VERSION ""

NS_ :

BS_:

BU_: Skylark_EV

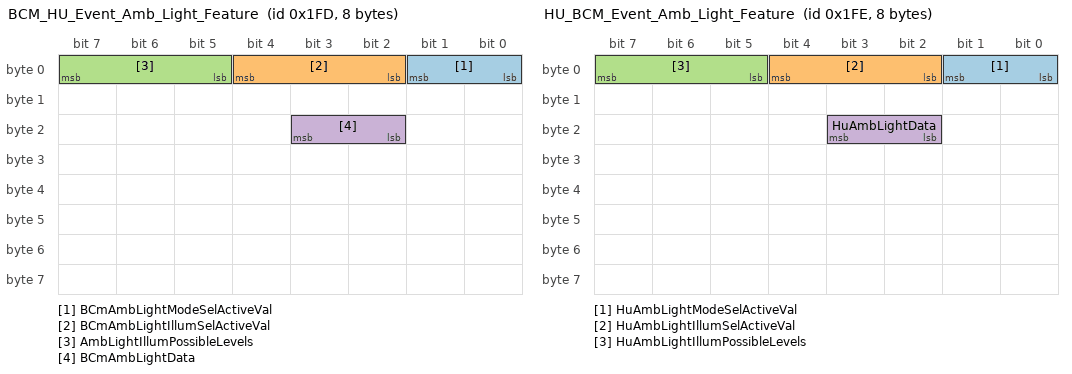
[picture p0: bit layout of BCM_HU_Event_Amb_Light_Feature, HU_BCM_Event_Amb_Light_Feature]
BO_ 509 BCM_HU_Event_Amb_Light_Feature: 8 Vector__XXX
 SG_ BCmAmbLightModeSelActiveVal : 1|2@0+ (1,0) [0|3] ""  Skylark_EV
 SG_ BCmAmbLightIllumSelActiveVal : 4|3@0+ (1,0) [0|7] ""  Skylark_EV
 SG_ AmbLightIllumPossibleLevels : 7|3@0+ (1,0) [0|7] ""  Skylark_EV
 SG_ BCmAmbLightData : 19|2@0+ (1,0) [0|3] ""  Skylark_EV

BO_ 510 HU_BCM_Event_Amb_Light_Feature: 8 Skylark_EV
 SG_ HuAmbLightModeSelActiveVal : 1|2@0+ (1,0) [0|3] "" Vector__XXX
 SG_ HuAmbLightIllumSelActiveVal : 4|3@0+ (1,0) [0|7] "" Vector__XXX
 SG_ HuAmbLightIllumPossibleLevels : 7|3@0+ (1,0) [0|7] "" Vector__XXX
 SG_ HuAmbLightData : 19|2@0+ (1,0) [0|3] "" Vector__XXX

BO_ 571 CCM_HU_Info: 8 Vector__XXX
 SG_ ColorThemeCoDrvr : 50|3@0+ (1,0) [0|7] ""  Skylark_EV
 SG_ ColorThemeDrvr : 53|3@0+ (1,0) [0|7] ""  Skylark_EV
 SG_ CcmHuRearBlwrOnOffState : 56|1@0+ (1,0) [0|1] ""  Skylark_EV
 SG_ CcmHuUserInterventionBeep : 62|1@0+ (1,0) [0|1] ""  Skylark_EV
 SG_ AutoDefogState : 40|2@0+ (1,0) [0|3] ""  Skylark_EV
 SG_ CCmHuExpressCoolSwitchStatus : 63|1@0+ (1,0) [0|1] ""  Skylark_EV
 SG_ CCmHuFanSpdStatus : 3|4@0+ (1,0) [0|15] ""  Skylark_EV
 SG_ CCmHuDistribSwitchStatus : 6|3@0+ (1,0) [0|7] ""  Skylark_EV
 SG_ CCmHuDualModeSwStatus : 7|1@0+ (1,0) [0|1] ""  Skylark_EV
 SG_ CCmHuTempWhlStatusPass : 12|5@0+ (0.5,0) [0|31] "Deg C"  Skylark_EV
 SG_ CCMHuFreshAirRecircSwitchStatus : 14|2@0+ (1,0) [0|3] ""  Skylark_EV
 SG_ CCmHuAutoSwitchStatus : 15|1@0+ (1,0) [0|1] ""  Skylark_EV
 SG_ CCmHuTempWhlStatus : 20|5@0+ (0.5,0) [0|31] "Deg C"  Skylark_EV
 SG_ CCmHuEconModeSwitchStatus : 21|1@0+ (1,0) [0|1] ""  Skylark_EV
 SG_ CCmHuMaxDefrstSwitchStatus : 22|1@0+ (1,0) [0|1] ""  Skylark_EV
 SG_ CCmHuRearDefogSwitchStatus : 23|1@0+ (1,0) [0|1] ""  Skylark_EV
 SG_ CCmHuTempWhlStatusDrvr : 28|5@0+ (0.5,0) [0|31] "Deg  C"  Skylark_EV
 SG_ CCmHuAirConCompSwitchStatus : 29|1@0+ (1,0) [0|1] ""  Skylark_EV
 SG_ CCmHuCtrlPnlStatus : 30|1@0+ (1,0) [0|1] ""  Skylark_EV
 SG_ CCmHuChangeBit : 31|1@0+ (1,0) [0|1] ""  Skylark_EV
 SG_ CCmHuUserInterventionStatusFlag : 37|5@0+ (1,0) [0|31] ""  Skylark_EV
 SG_ CCmHuTempWhlStatusStatus : 39|2@0+ (1,0) [0|3] ""  Skylark_EV
 SG_ CCmHuErrStatus : 41|1@0+ (1,0) [0|1] ""  Skylark_EV
 SG_ CCmHuDualModeSwStatusStatus : 43|2@0+ (1,0) [0|3] ""  Skylark_EV
 SG_ CCmHuTempWhlStatusPassStatus : 45|2@0+ (1,0) [0|3] ""  Skylark_EV
 SG_ CCmHuTempWhlStatusDrvrStatus : 47|2@0+ (1,0) [0|3] ""  Skylark_EV

BO_ 573 ESCL1_RC: 8 Vector__XXX
 SG_ LockStateESCL : 2|1@0+ (1,0) [0|1] ""  Skylark_EV
 SG_ UnlockStateESCL : 3|1@0+ (1,0) [0|1] ""  Skylark_EV

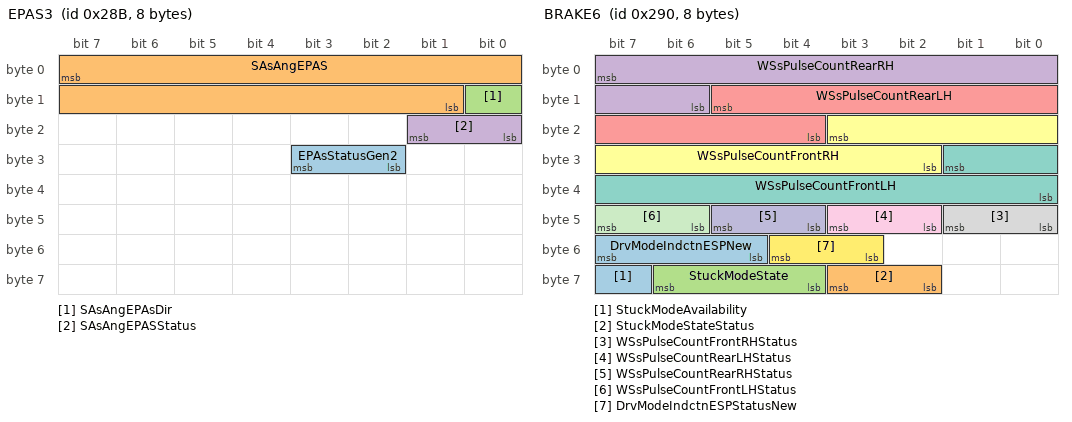
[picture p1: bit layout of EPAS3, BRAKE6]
BO_ 651 EPAS3: 8 Vector__XXX
 SG_ EPAsStatusGen2 : 27|2@0+ (1,0) [0|3] ""  Skylark_EV
 SG_ SAsAngEPAS : 7|15@0+ (0.04375,0) [0|1433.55625] " deg"  Skylark_EV
 SG_ SAsAngEPAsDir : 8|1@0+ (1,0) [0|1] ""  Skylark_EV
 SG_ SAsAngEPASStatus : 17|2@0+ (1,0) [0|3] ""  Skylark_EV

BO_ 656 BRAKE6: 8 Vector__XXX
 SG_ StuckModeAvailability : 63|1@0+ (1,0) [0|1] ""  Skylark_EV
 SG_ StuckModeStateStatus : 59|2@0+ (1,0) [0|3] ""  Skylark_EV
 SG_ StuckModeState : 62|3@0+ (1,0) [0|7] ""  Skylark_EV
 SG_ WSsPulseCountRearRH : 7|10@0+ (1,0) [0|1023] "Pulse"  Skylark_EV
 SG_ WSsPulseCountRearLH : 13|10@0+ (1,0) [0|1023] "Pulse"  Skylark_EV
 SG_ WSsPulseCountFrontRH : 19|10@0+ (1,0) [0|1023] "Pulse"  Skylark_EV
 SG_ WSsPulseCountFrontLH : 25|10@0+ (1,0) [0|1023] "Pulse"  Skylark_EV
 SG_ WSsPulseCountFrontRHStatus : 41|2@0+ (1,0) [0|3] ""  Skylark_EV
 SG_ WSsPulseCountRearLHStatus : 43|2@0+ (1,0) [0|3] ""  Skylark_EV
 SG_ WSsPulseCountRearRHStatus : 45|2@0+ (1,0) [0|3] ""  Skylark_EV
 SG_ WSsPulseCountFrontLHStatus : 47|2@0+ (1,0) [0|3] ""  Skylark_EV
 SG_ DrvModeIndctnESPStatusNew : 52|2@0+ (1,0) [0|3] ""  Skylark_EV
 SG_ DrvModeIndctnESPNew : 55|3@0+ (1,0) [0|7] ""  Skylark_EV

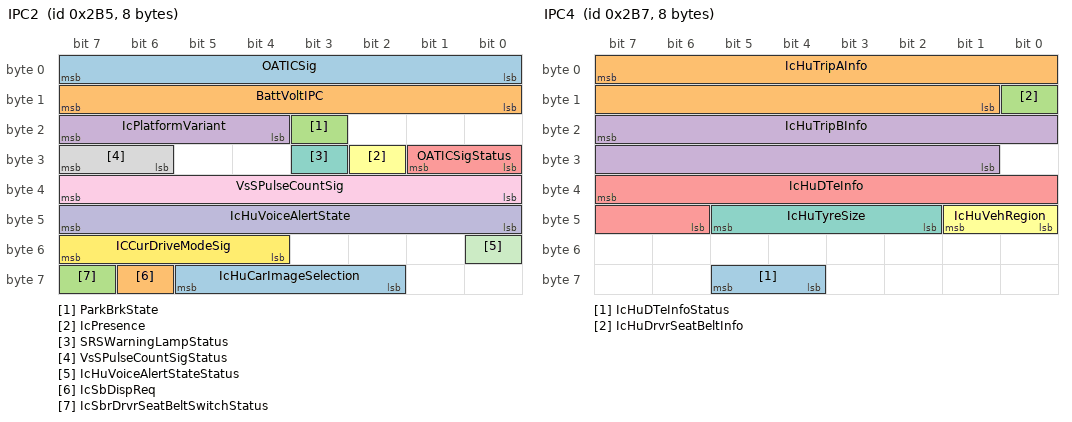
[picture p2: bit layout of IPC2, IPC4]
BO_ 693 IPC2: 8 Vector__XXX
 SG_ OATICSig : 7|8@0+ (0.5,-40) [-40|85] "degC"  Skylark_EV
 SG_ BattVoltIPC : 15|8@0+ (0.1,0) [0|25.4] "Volts"  Skylark_EV
 SG_ ParkBrkState : 19|1@0+ (1,0) [0|1] ""  Skylark_EV
 SG_ IcPlatformVariant : 23|4@0+ (1,0) [0|15] ""  Skylark_EV
 SG_ OATICSigStatus : 25|2@0+ (1,0) [0|3] ""  Skylark_EV
 SG_ IcPresence : 26|1@0+ (1,0) [0|1] ""  Skylark_EV
 SG_ SRSWarningLampStatus : 27|1@0+ (1,0) [0|1] ""  Skylark_EV
 SG_ VsSPulseCountSigStatus : 31|2@0+ (1,0) [0|3] ""  Skylark_EV
 SG_ VsSPulseCountSig : 39|8@0+ (1,0) [0|255] "Pulse"  Skylark_EV
 SG_ IcHuVoiceAlertState : 47|8@0+ (1,0) [0|255] ""  Skylark_EV
 SG_ IcHuVoiceAlertStateStatus : 48|1@0+ (1,0) [0|1] ""  Skylark_EV
 SG_ ICCurDriveModeSig : 55|4@0+ (1,0) [0|15] ""  Skylark_EV
 SG_ IcHuCarImageSelection : 61|4@0+ (1,0) [0|15] ""  Skylark_EV
 SG_ IcSbDispReq : 62|1@0+ (1,0) [0|1] ""  Skylark_EV
 SG_ IcSbrDrvrSeatBeltSwitchStatus : 63|1@0+ (1,0) [0|1] ""  Skylark_EV

BO_ 695 IPC4: 8 Vector__XXX
 SG_ IcHuDTeInfoStatus : 61|2@0+ (1,0) [0|3] ""  Skylark_EV
 SG_ IcHuTripAInfo : 7|15@0+ (0.1,0) [0|1999] "Km"  Skylark_EV
 SG_ IcHuDrvrSeatBeltInfo : 8|1@0+ (1,0) [0|1] ""  Skylark_EV
 SG_ IcHuTripBInfo : 23|15@0+ (0.1,0) [0|1999] "Km"  Skylark_EV
 SG_ IcHuDTeInfo : 39|10@0+ (1,0) [0|999] ""  Skylark_EV
 SG_ IcHuVehRegion : 41|2@0+ (1,0) [0|3] ""  Skylark_EV
 SG_ IcHuTyreSize : 45|4@0+ (1,0) [0|15] ""  Skylark_EV

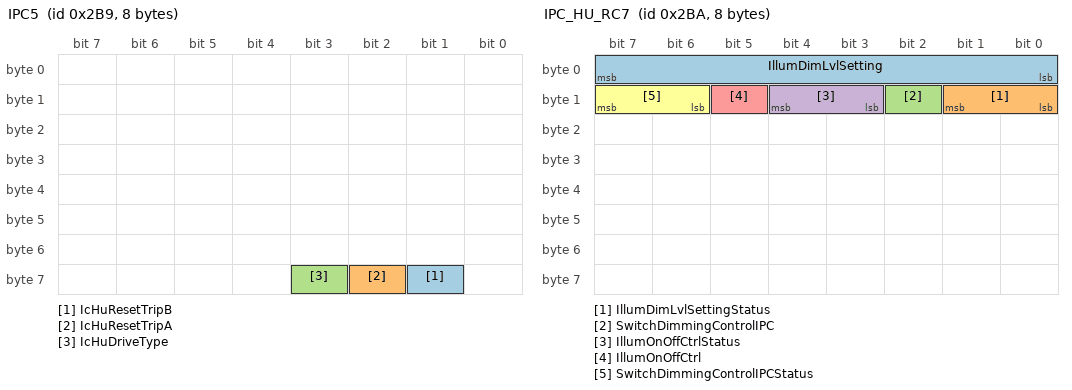
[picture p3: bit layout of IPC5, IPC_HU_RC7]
BO_ 697 IPC5: 8 Vector__XXX
 SG_ IcHuResetTripB : 57|1@0+ (1,0) [0|1] ""  Skylark_EV
 SG_ IcHuResetTripA : 58|1@0+ (1,0) [0|1] ""  Skylark_EV
 SG_ IcHuDriveType : 59|1@0+ (1,0) [0|1] ""  Skylark_EV

BO_ 698 IPC_HU_RC7: 8 Vector__XXX
 SG_ IllumDimLvlSetting : 7|8@0+ (1,0) [0|100] "%"  Skylark_EV
 SG_ IllumDimLvlSettingStatus : 9|2@0+ (1,0) [0|3] ""  Skylark_EV
 SG_ SwitchDimmingControlIPC : 10|1@0+ (1,0) [0|1] ""  Skylark_EV
 SG_ IllumOnOffCtrlStatus : 12|2@0+ (1,0) [0|3] ""  Skylark_EV
 SG_ IllumOnOffCtrl : 13|1@0+ (1,0) [0|1] ""  Skylark_EV
 SG_ SwitchDimmingControlIPCStatus : 15|2@0+ (1,0) [0|3] ""  Skylark_EV

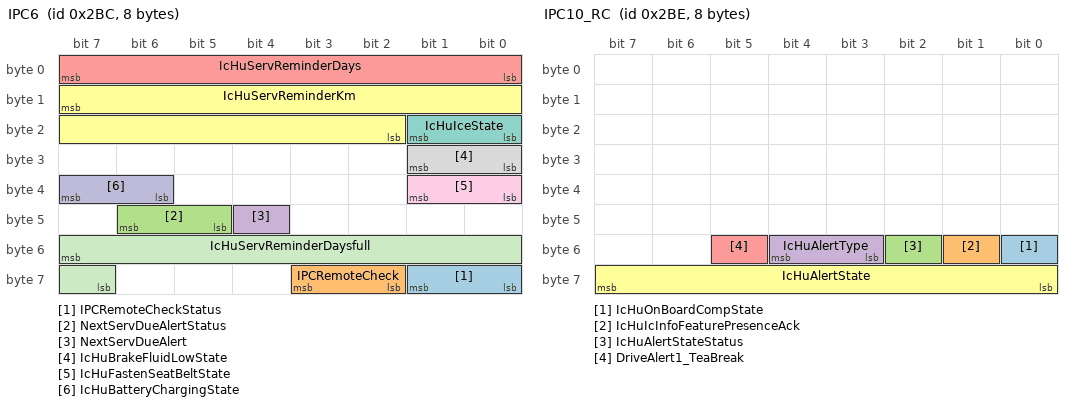
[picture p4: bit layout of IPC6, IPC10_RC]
BO_ 700 IPC6: 8 Vector__XXX
 SG_ IPCRemoteCheckStatus : 57|2@0+ (1,0) [0|3] ""  Skylark_EV
 SG_ IPCRemoteCheck : 59|2@0+ (1,0) [0|3] ""  Skylark_EV
 SG_ NextServDueAlertStatus : 46|2@0+ (1,0) [0|3] ""  Skylark_EV
 SG_ NextServDueAlert : 44|1@0+ (1,0) [0|1] ""  Skylark_EV
 SG_ IcHuServReminderDays : 7|8@0+ (1,0) [0|255] "Day"  Skylark_EV
 SG_ IcHuServReminderKm : 15|14@0+ (1,0) [0|16383] "Km"  Skylark_EV
 SG_ IcHuIceState : 17|2@0+ (1,0) [0|3] ""  Skylark_EV
 SG_ IcHuBrakeFluidLowState : 25|2@0+ (1,0) [0|3] ""  Skylark_EV
 SG_ IcHuFastenSeatBeltState : 33|2@0+ (1,0) [0|3] ""  Skylark_EV
 SG_ IcHuBatteryChargingState : 39|2@0+ (1,0) [0|3] ""  Skylark_EV
 SG_ IcHuServReminderDaysfull : 55|9@0+ (1,0) [0|511] "Day"  Skylark_EV

BO_ 702 IPC10_RC: 8 Vector__XXX
 SG_ IcHuOnBoardCompState : 48|1@0+ (1,0) [0|1] ""  Skylark_EV
 SG_ IcHuIcInfoFeaturePresenceAck : 49|1@0+ (1,0) [0|1] ""  Skylark_EV
 SG_ IcHuAlertStateStatus : 50|1@0+ (1,0) [0|1] ""  Skylark_EV
 SG_ IcHuAlertType : 52|2@0+ (1,0) [0|3] ""  Skylark_EV
 SG_ DriveAlert1_TeaBreak : 53|1@0+ (1,0) [0|1] ""  Skylark_EV
 SG_ IcHuAlertState : 63|8@0+ (1,0) [0|255] ""  Skylark_EV

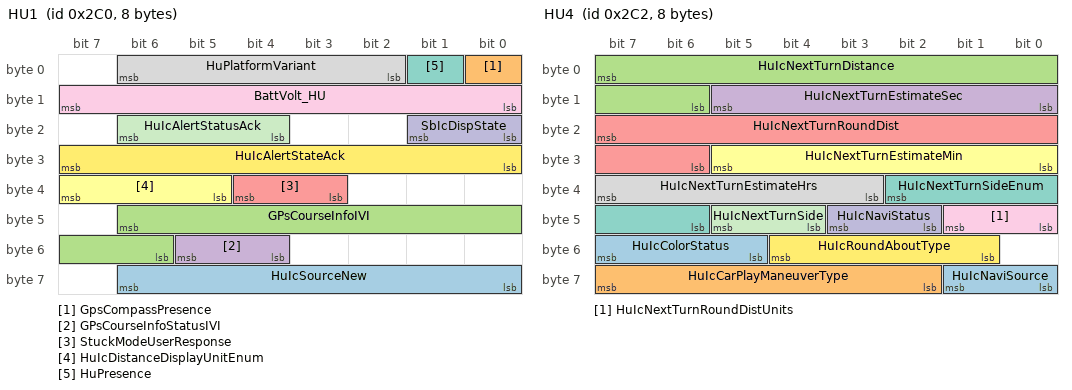
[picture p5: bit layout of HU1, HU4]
BO_ 704 HU1: 8 Skylark_EV
 SG_ HuIcSourceNew : 62|7@0+ (1,0) [0|127] "" Vector__XXX
 SG_ GpsCompassPresence : 0|1@0+ (1,0) [0|1] "" Vector__XXX
 SG_ GPsCourseInfoIVI : 46|9@0+ (1,0) [0|360] "" Vector__XXX
 SG_ GPsCourseInfoStatusIVI : 53|2@0+ (1,0) [0|3] "" Vector__XXX
 SG_ StuckModeUserResponse : 36|2@0+ (1,0) [0|3] "" Vector__XXX
 SG_ HuIcDistanceDisplayUnitEnum : 39|3@0+ (1,0) [0|7] "" Vector__XXX
 SG_ HuPresence : 1|1@0+ (1,0) [0|1] "" Vector__XXX
 SG_ HuPlatformVariant : 6|5@0+ (1,0) [0|31] "" Vector__XXX
 SG_ BattVolt_HU : 15|8@0+ (0.1,0) [0|25] "Volts" Vector__XXX
 SG_ SbIcDispState : 17|2@0+ (1,0) [0|3] "" Vector__XXX
 SG_ HuIcAlertStatusAck : 22|3@0+ (1,0) [0|7] "" Vector__XXX
 SG_ HuIcAlertStateAck : 31|8@0+ (1,0) [0|255] "" Vector__XXX

BO_ 706 HU4: 8 Skylark_EV
 SG_ HuIcNaviSource : 57|2@0+ (1,0) [0|3] "" Vector__XXX
 SG_ HuIcCarPlayManeuverType : 63|6@0+ (1,0) [0|63] "" Vector__XXX
 SG_ HuIcNextTurnDistance : 7|10@0+ (1,0) [0|1023] "m" Vector__XXX
 SG_ HuIcNextTurnEstimateSec : 13|6@0+ (1,0) [0|59] "sec" Vector__XXX
 SG_ HuIcNextTurnRoundDist : 23|10@0+ (1,0) [0|1023] "m" Vector__XXX
 SG_ HuIcNextTurnEstimateMin : 29|6@0+ (1,0) [0|59] "min" Vector__XXX
 SG_ HuIcNextTurnSideEnum : 34|5@0+ (1,0) [0|31] "" Vector__XXX
 SG_ HuIcNextTurnEstimateHrs : 39|5@0+ (1,0) [0|23] "hr" Vector__XXX
 SG_ HuIcNextTurnRoundDistUnits : 41|2@0+ (1,0) [0|3] "" Vector__XXX
 SG_ HuIcNaviStatus : 43|2@0+ (1,0) [0|3] "" Vector__XXX
 SG_ HuIcNextTurnSide : 45|2@0+ (1,0) [0|3] "" Vector__XXX
 SG_ HuIcRoundAboutType : 52|4@0+ (1,0) [0|15] "" Vector__XXX
 SG_ HuIcColorStatus : 55|3@0+ (1,0) [0|7] "" Vector__XXX

BO_ 707 HU2: 8 Skylark_EV
 SG_ HuIcNextTurnRoundDistUnitsNew : 59|3@0+ (1,0) [0|7] "" Vector__XXX
 SG_ HuIcNextTurnDistanceNew : 41|14@0+ (1,0) [0|16383] "m" Vector__XXX
 SG_ LinSwcSbPowerModeCan : 43|2@0+ (1,0) [0|3] "" Vector__XXX
 SG_ LinSwcIcKey9Can : 46|3@0+ (1,0) [0|7] "" Vector__XXX
 SG_ LinSwcIcKey8Can : 33|3@0+ (1,0) [0|7] "" Vector__XXX
 SG_ LinSwcIcKey7Can : 36|3@0+ (1,0) [0|7] "" Vector__XXX
 SG_ LinSwcIcKey6Can : 39|3@0+ (1,0) [0|7] "" Vector__XXX
 SG_ LinSwcIcViewCan : 26|3@0+ (1,0) [0|7] "" Vector__XXX
 SG_ LinSwcIcMenuSelectCan : 29|3@0+ (1,0) [0|7] "" Vector__XXX
 SG_ LinSwcIcMenuDownCan : 16|3@0+ (1,0) [0|7] "" Vector__XXX
 SG_ LinSwcIcMenuUpCan : 19|3@0+ (1,0) [0|7] "" Vector__XXX
 SG_ LinSwcIcpaginationCan : 22|3@0+ (1,0) [0|7] "" Vector__XXX
 SG_ LinSwcPresenceCanStatus : 4|2@0+ (1,0) [0|3] "" Vector__XXX
 SG_ LinSwcIcVariant : 7|3@0+ (1,0) [0|7] "" Vector__XXX
 SG_ LinSwcPresenceCan : 23|1@0+ (1,0) [0|1] "" Vector__XXX
 SG_ HuIcVoiceAlertStatusAck : 2|3@0+ (1,0) [0|7] "" Vector__XXX
 SG_ HuIcVoiceAlertStateAck : 15|8@0+ (1,0) [0|255] "" Vector__XXX

BO_ 710 PDC1: 8 Vector__XXX
 SG_ PDcHuFaultState : 4|5@0+ (1,0) [0|31] ""  Skylark_EV
 SG_ PDcHuAudioZoneState : 7|3@0+ (1,0) [0|7] ""  Skylark_EV
 SG_ PDcHuVisualZoneRearLHSensState : 11|4@0+ (1,0) [0|15] ""  Skylark_EV
 SG_ PDcHuVisualZoneRearMidRHSensStat : 15|4@0+ (1,0) [0|15] ""  Skylark_EV
 SG_ PDcHuVisualZoneRearRHSensState : 19|4@0+ (1,0) [0|15] ""  Skylark_EV
 SG_ PDcHuVisualZoneRearMidLHSensStat : 23|4@0+ (1,0) [0|15] ""  Skylark_EV
 SG_ PDcPresence : 24|1@0+ (1,0) [0|1] ""  Skylark_EV
 SG_ PDcHuState : 25|1@0+ (1,0) [0|1] ""  Skylark_EV
 SG_ PDcHuPwrModeState : 29|4@0+ (1,0) [0|15] ""  Skylark_EV
 SG_ PDcVariant : 31|2@0+ (1,0) [0|3] ""  Skylark_EV
 SG_ PDcHuVisualZoneFrontLHSensState : 35|4@0+ (1,0) [0|15] ""  Skylark_EV
 SG_ PDcHuVisualZoneFrontMidLHSensSta : 39|4@0+ (1,0) [0|15] ""  Skylark_EV
 SG_ PDcHuVisualZoneFrontMidRHSensSta : 43|4@0+ (1,0) [0|15] ""  Skylark_EV
 SG_ PDcHuVisualZoneFrontRHSensState : 47|4@0+ (1,0) [0|15] ""  Skylark_EV
 SG_ PDcHuFrontAudioZoneState : 50|3@0+ (1,0) [0|7] ""  Skylark_EV
 SG_ PDcHuFrontFaultState : 55|5@0+ (1,0) [0|31] ""  Skylark_EV
 SG_ PDcHuFrontState : 56|1@0+ (1,0) [0|1] ""  Skylark_EV
 SG_ PDcIPcFrontActive : 59|1@0+ (1,0) [0|1] ""  Skylark_EV
 SG_ PDcIPcRearActive : 60|1@0+ (1,0) [0|1] ""  Skylark_EV

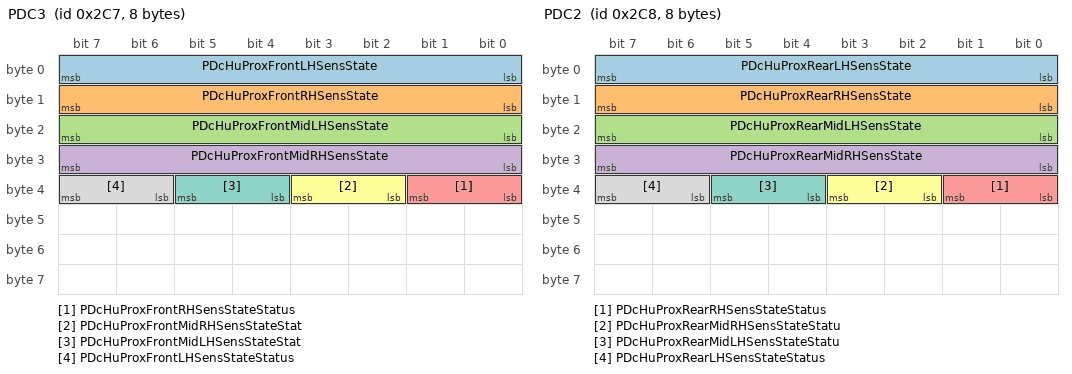
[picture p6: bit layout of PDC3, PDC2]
BO_ 711 PDC3: 8 Vector__XXX
 SG_ PDcHuProxFrontLHSensState : 7|8@0+ (1,0) [0|255] "cms"  Skylark_EV
 SG_ PDcHuProxFrontRHSensState : 15|8@0+ (1,0) [0|255] "cms"  Skylark_EV
 SG_ PDcHuProxFrontMidLHSensState : 23|8@0+ (1,0) [0|255] "cms"  Skylark_EV
 SG_ PDcHuProxFrontMidRHSensState : 31|8@0+ (1,0) [0|255] "cm"  Skylark_EV
 SG_ PDcHuProxFrontRHSensStateStatus : 33|2@0+ (1,0) [0|3] ""  Skylark_EV
 SG_ PDcHuProxFrontMidRHSensStateStat : 35|2@0+ (1,0) [0|3] ""  Skylark_EV
 SG_ PDcHuProxFrontMidLHSensStateStat : 37|2@0+ (1,0) [0|3] ""  Skylark_EV
 SG_ PDcHuProxFrontLHSensStateStatus : 39|2@0+ (1,0) [0|3] ""  Skylark_EV

BO_ 712 PDC2: 8 Vector__XXX
 SG_ PDcHuProxRearLHSensState : 7|8@0+ (1,0) [0|255] "cms"  Skylark_EV
 SG_ PDcHuProxRearRHSensState : 15|8@0+ (1,0) [0|255] "cms"  Skylark_EV
 SG_ PDcHuProxRearMidLHSensState : 23|8@0+ (1,0) [0|255] "cms"  Skylark_EV
 SG_ PDcHuProxRearMidRHSensState : 31|8@0+ (1,0) [0|255] "cm"  Skylark_EV
 SG_ PDcHuProxRearRHSensStateStatus : 33|2@0+ (1,0) [0|3] ""  Skylark_EV
 SG_ PDcHuProxRearMidRHSensStateStatu : 35|2@0+ (1,0) [0|3] ""  Skylark_EV
 SG_ PDcHuProxRearMidLHSensStateStatu : 37|2@0+ (1,0) [0|3] ""  Skylark_EV
 SG_ PDcHuProxRearLHSensStateStatus : 39|2@0+ (1,0) [0|3] ""  Skylark_EV

BO_ 713 HU5: 8 Skylark_EV
 SG_ HuIcMediaState : 3|4@0+ (1,0) [0|15] "" Vector__XXX
 SG_ HuIcSource : 7|4@0+ (1,0) [0|15] "" Vector__XXX
 SG_ HuIcAudioVolumeStatus : 12|5@0+ (1,0) [0|31] "" Vector__XXX
 SG_ HuIcBTStatus : 15|3@0+ (1,0) [0|7] "" Vector__XXX
 SG_ HuIcPlabackCallDurationSec : 21|6@0+ (1,0) [0|59] "sec." Vector__XXX
 SG_ HuIcRepeatOneState : 22|1@0+ (1,0) [0|1] "" Vector__XXX
 SG_ HuIcMuteStatus : 23|1@0+ (1,0) [0|1] "" Vector__XXX
 SG_ HuIcPlabackCallDurationMin : 29|6@0+ (1,0) [0|59] "min" Vector__XXX
 SG_ HuIcSMSReceiveState : 30|1@0+ (1,0) [0|1] "" Vector__XXX
 SG_ HuIcRepeatState : 31|1@0+ (1,0) [0|1] "" Vector__XXX
 SG_ HuIcPlabackCallDurationHrs : 36|5@0+ (1,0) [0|23] "hr" Vector__XXX
 SG_ HuIcPhoneCallStatus : 39|3@0+ (1,0) [0|7] "" Vector__XXX
 SG_ HuIcPlaybackElapsedTimeHrs : 44|5@0+ (1,0) [0|23] "hr" Vector__XXX
 SG_ HuIcNetworkSignalStatus : 47|3@0+ (1,0) [0|7] "" Vector__XXX
 SG_ HuIcPlaybackElapsedTimeMin : 53|6@0+ (1,0) [0|59] "min" Vector__XXX
 SG_ HuIcInfoFeaturePresence : 54|1@0+ (1,0) [0|1] "" Vector__XXX
 SG_ HuIcShuffleState : 55|1@0+ (1,0) [0|1] "" Vector__XXX
 SG_ HuIcPlaybackElapsedTimeSec : 61|6@0+ (1,0) [0|59] "sec" Vector__XXX

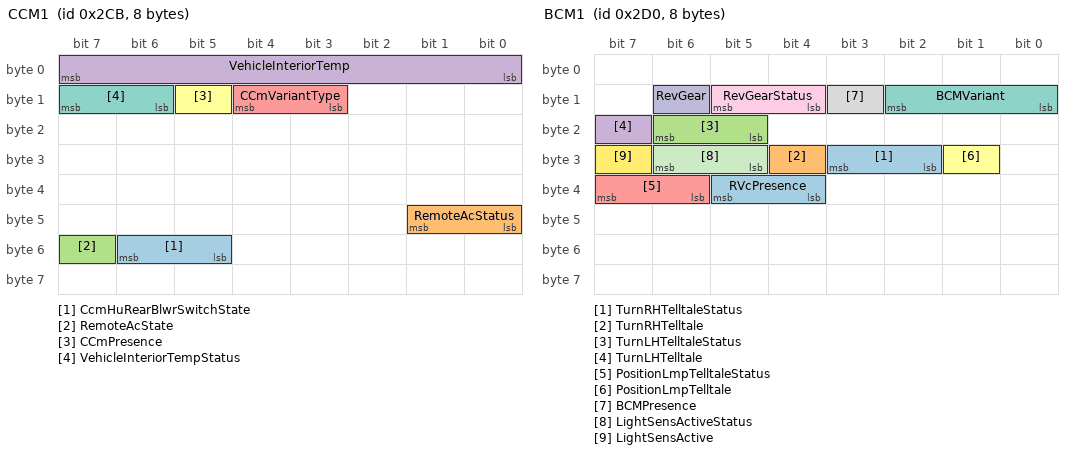
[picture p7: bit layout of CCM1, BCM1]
BO_ 715 CCM1: 8 Vector__XXX
 SG_ CcmHuRearBlwrSwitchState : 54|2@0+ (1,0) [0|3] ""  Skylark_EV
 SG_ RemoteAcStatus : 41|2@0+ (1,0) [0|3] ""  Skylark_EV
 SG_ RemoteAcState : 55|1@0+ (1,0) [0|1] ""  Skylark_EV
 SG_ VehicleInteriorTemp : 7|8@0+ (0.5,-40) [-40|85] "Deg"  Skylark_EV
 SG_ CCmVariantType : 12|2@0+ (1,0) [0|3] ""  Skylark_EV
 SG_ CCmPresence : 13|1@0+ (1,0) [0|1] ""  Skylark_EV
 SG_ VehicleInteriorTempStatus : 15|2@0+ (1,0) [0|3] ""  Skylark_EV

BO_ 720 BCM1: 8 Vector__XXX
 SG_ TurnRHTelltaleStatus : 27|2@0+ (1,0) [0|3] ""  Skylark_EV
 SG_ TurnRHTelltale : 28|1@0+ (1,0) [0|1] ""  Skylark_EV
 SG_ TurnLHTelltaleStatus : 22|2@0+ (1,0) [0|3] ""  Skylark_EV
 SG_ TurnLHTelltale : 23|1@0+ (1,0) [0|1] ""  Skylark_EV
 SG_ PositionLmpTelltaleStatus : 39|2@0+ (1,0) [0|3] ""  Skylark_EV
 SG_ PositionLmpTelltale : 25|1@0+ (1,0) [0|1] ""  Skylark_EV
 SG_ BCMVariant : 10|3@0+ (1,0) [0|7] ""  Skylark_EV
 SG_ BCMPresence : 11|1@0+ (1,0) [0|1] ""  Skylark_EV
 SG_ RevGearStatus : 13|2@0+ (1,0) [0|3] ""  Skylark_EV
 SG_ RevGear : 14|1@0+ (1,0) [0|1] ""  Skylark_EV
 SG_ LightSensActiveStatus : 30|2@0+ (1,0) [0|3] ""  Skylark_EV
 SG_ LightSensActive : 31|1@0+ (1,0) [0|1] ""  Skylark_EV
 SG_ RVcPresence : 37|2@0+ (1,0) [0|3] ""  Skylark_EV

BO_ 722 BCM_HUICTrailer_RC1: 8 Vector__XXX
 SG_ PowerModeStateMsgCnt : 51|4@0+ (1,0) [0|15] ""  Skylark_EV
 SG_ PowerModeStateCRC : 63|8@0+ (1,0) [0|255] ""  Skylark_EV
 SG_ PowerModeStateStatus : 1|2@0+ (1,0) [0|3] ""  Skylark_EV
 SG_ PowerModeState : 5|4@0+ (1,0) [0|15] ""  Skylark_EV
 SG_ PositionLmpTelltaleStatus : 7|2@0+ (1,0) [0|3] ""  Skylark_EV
 SG_ PositionLmpTelltale : 8|1@0+ (1,0) [0|1] ""  Skylark_EV
 SG_ TurnRHTelltale : 12|1@0+ (1,0) [0|1] ""  Skylark_EV
 SG_ TurnLHTelltaleStatus : 14|2@0+ (1,0) [0|3] ""  Skylark_EV
 SG_ TurnLHTelltale : 15|1@0+ (1,0) [0|1] ""  Skylark_EV
 SG_ TurnRHTelltaleStatus : 17|2@0+ (1,0) [0|3] ""  Skylark_EV
 SG_ BattSaverFnONStatus : 19|2@0+ (1,0) [0|3] ""  Skylark_EV
 SG_ BattSaverFnON : 20|1@0+ (1,0) [0|1] ""  Skylark_EV
 SG_ CockpitSigECuStatus : 25|2@0+ (1,0) [0|3] ""  Skylark_EV
 SG_ CockpitSigECu : 39|8@0+ (1,0) [0|100] "%"  Skylark_EV
 SG_ VehicleLockStateStatus : 41|2@0+ (1,0) [0|3] ""  Skylark_EV
 SG_ HighBeamTelltaleStatus : 43|2@0+ (1,0) [0|3] ""  Skylark_EV
 SG_ HighBeamTelltale : 44|1@0+ (1,0) [0|1] ""  Skylark_EV
 SG_ VehicleLockState : 55|3@0+ (1,0) [0|7] ""  Skylark_EV

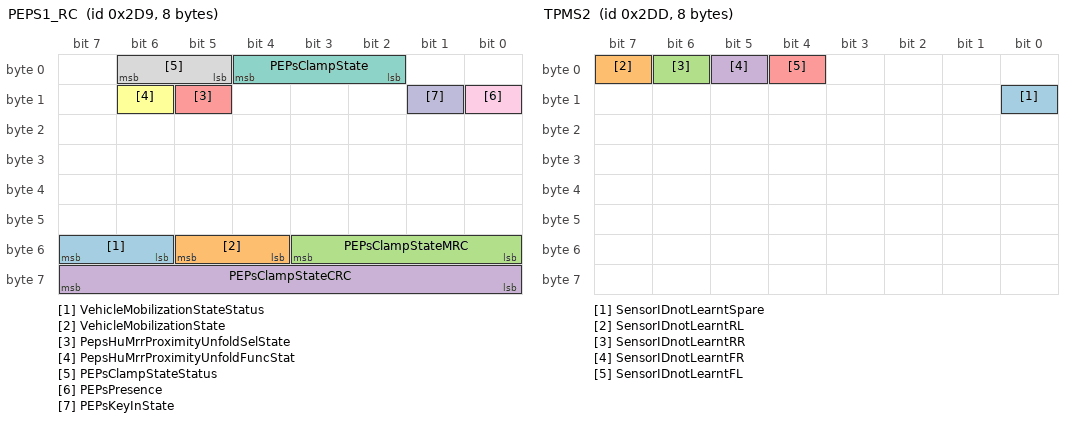
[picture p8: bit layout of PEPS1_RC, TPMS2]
BO_ 729 PEPS1_RC: 8 Vector__XXX
 SG_ VehicleMobilizationStateStatus : 55|2@0+ (1,0) [0|3] ""  Skylark_EV
 SG_ VehicleMobilizationState : 53|2@0+ (1,0) [0|3] ""  Skylark_EV
 SG_ PEPsClampStateMRC : 51|4@0+ (1,0) [0|15] ""  Skylark_EV
 SG_ PEPsClampStateCRC : 63|8@0+ (1,0) [0|255] ""  Skylark_EV
 SG_ PepsHuMrrProximityUnfoldSelState : 13|1@0+ (1,0) [0|1] ""  Skylark_EV
 SG_ PepsHuMrrProximityUnfoldFuncStat : 14|1@0+ (1,0) [0|1] ""  Skylark_EV
 SG_ PEPsClampState : 4|3@0+ (1,0) [0|7] ""  Skylark_EV
 SG_ PEPsClampStateStatus : 6|2@0+ (1,0) [0|3] ""  Skylark_EV
 SG_ PEPsPresence : 8|1@0+ (1,0) [0|1] ""  Skylark_EV
 SG_ PEPsKeyInState : 9|1@0+ (1,0) [0|1] ""  Skylark_EV

BO_ 732 TPMS1: 8 Vector__XXX
 SG_ TpmsTireSensorConfig : 47|2@0+ (1,0) [0|3] ""  Skylark_EV
 SG_ TPMSPresence : 49|1@0+ (1,0) [0|1] ""  Skylark_EV
 SG_ LowTirePresAlertSpare : 14|1@0+ (1,0) [0|1] ""  Skylark_EV
 SG_ LowTirePresAlertRL : 13|1@0+ (1,0) [0|1] ""  Skylark_EV
 SG_ LowTirePresAlertRR : 12|1@0+ (1,0) [0|1] ""  Skylark_EV
 SG_ LowTirePresAlertFR : 11|1@0+ (1,0) [0|1] ""  Skylark_EV
 SG_ LowTirePresAlertFL : 10|1@0+ (1,0) [0|1] ""  Skylark_EV
 SG_ HighTirePresAlertSpare : 4|1@0+ (1,0) [0|1] ""  Skylark_EV
 SG_ HighTirePresAlertRL : 2|1@0+ (1,0) [0|1] ""  Skylark_EV
 SG_ HighTirePresAlertRR : 3|1@0+ (1,0) [0|1] ""  Skylark_EV
 SG_ HighTirePresAlertFR : 1|1@0+ (1,0) [0|1] ""  Skylark_EV
 SG_ HighTirePresAlertFL : 0|1@0+ (1,0) [0|1] ""  Skylark_EV
 SG_ HighTireTempAlertSpare : 9|1@0+ (1,0) [0|1] ""  Skylark_EV
 SG_ HighTireTempAlertRL : 7|1@0+ (1,0) [0|1] ""  Skylark_EV
 SG_ HighTireTempAlertRR : 8|1@0+ (1,0) [0|1] ""  Skylark_EV
 SG_ HighTireTempAlertFR : 6|1@0+ (1,0) [0|1] ""  Skylark_EV
 SG_ HighTireTempAlertFL : 5|1@0+ (1,0) [0|1] ""  Skylark_EV
 SG_ PresLeakageAlertSpare : 19|1@0+ (1,0) [0|1] ""  Skylark_EV
 SG_ PresLeakageAlertRL : 17|1@0+ (1,0) [0|1] ""  Skylark_EV
 SG_ PresLeakageAlertRR : 18|1@0+ (1,0) [0|1] ""  Skylark_EV
 SG_ PresLeakageAlertFR : 16|1@0+ (1,0) [0|1] ""  Skylark_EV
 SG_ PresLeakageAlertFL : 15|1@0+ (1,0) [0|1] ""  Skylark_EV
 SG_ TpmsAlertStatus : 45|2@0+ (1,0) [0|3] ""  Skylark_EV
 SG_ TpmsReceiverRXFault : 48|1@0+ (1,0) [0|1] ""  Skylark_EV
 SG_ SensorMalfncFaultSpare : 29|1@0+ (1,0) [0|1] ""  Skylark_EV
 SG_ SensorMalfncFaultRL : 27|1@0+ (1,0) [0|1] ""  Skylark_EV
 SG_ SensorMalfncFaultRR : 28|1@0+ (1,0) [0|1] ""  Skylark_EV
 SG_ SensorMalfncFaultFR : 26|1@0+ (1,0) [0|1] ""  Skylark_EV
 SG_ SensorMalfncFaultFL : 25|1@0+ (1,0) [0|1] ""  Skylark_EV
 SG_ TpmsFaultStatus : 39|2@0+ (1,0) [0|3] ""  Skylark_EV
 SG_ TpmsNotLearntFault : 40|1@0+ (1,0) [0|1] ""  Skylark_EV
 SG_ SensorMissingFaultRL : 32|1@0+ (1,0) [0|1] ""  Skylark_EV
 SG_ SensorMissingFaultRR : 33|1@0+ (1,0) [0|1] ""  Skylark_EV
 SG_ SensorMissingFaultFR : 31|1@0+ (1,0) [0|1] ""  Skylark_EV
 SG_ SensorMissingFaultFL : 30|1@0+ (1,0) [0|1] ""  Skylark_EV
 SG_ TpmsLearnStatus : 51|2@0+ (1,0) [0|3] ""  Skylark_EV
 SG_ SpareTireSwapFlagRL : 36|1@0+ (1,0) [0|1] ""  Skylark_EV
 SG_ SpareTireSwapFlagRR : 37|1@0+ (1,0) [0|1] ""  Skylark_EV
 SG_ SpareTireSwapFlagFR : 35|1@0+ (1,0) [0|1] ""  Skylark_EV
 SG_ SpareTireSwapFlagFL : 34|1@0+ (1,0) [0|1] ""  Skylark_EV
 SG_ SensorLearningStatus : 43|3@0+ (1,0) [0|7] ""  Skylark_EV
 SG_ SensorDetectFlagSpare : 24|1@0+ (1,0) [0|1] ""  Skylark_EV
 SG_ SensorDetectFlagRL : 22|1@0+ (1,0) [0|1] ""  Skylark_EV
 SG_ SensorDetectFlagRR : 23|1@0+ (1,0) [0|1] ""  Skylark_EV
 SG_ SensorDetectFlagFR : 21|1@0+ (1,0) [0|1] ""  Skylark_EV
 SG_ SensorDetectFlagFL : 20|1@0+ (1,0) [0|1] ""  Skylark_EV

BO_ 733 TPMS2: 8 Vector__XXX
 SG_ SensorIDnotLearntSpare : 8|1@0+ (1,0) [0|1] ""  Skylark_EV
 SG_ SensorIDnotLearntRL : 7|1@0+ (1,0) [0|1] ""  Skylark_EV
 SG_ SensorIDnotLearntRR : 6|1@0+ (1,0) [0|1] ""  Skylark_EV
 SG_ SensorIDnotLearntFR : 5|1@0+ (1,0) [0|1] ""  Skylark_EV
 SG_ SensorIDnotLearntFL : 4|1@0+ (1,0) [0|1] ""  Skylark_EV

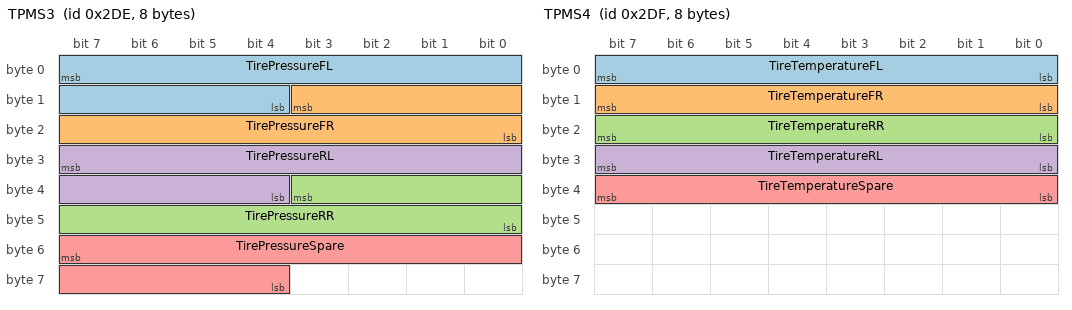
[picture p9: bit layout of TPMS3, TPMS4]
BO_ 734 TPMS3: 8 Vector__XXX
 SG_ TirePressureFL : 7|12@0+ (0.1,0) [0|409.5] "Psi"  Skylark_EV
 SG_ TirePressureFR : 11|12@0+ (0.1,0) [0|409.5] "Psi"  Skylark_EV
 SG_ TirePressureRR : 35|12@0+ (0.1,0) [0|409.5] "Psi"  Skylark_EV
 SG_ TirePressureRL : 31|12@0+ (0.1,0) [0|409.5] "Psi"  Skylark_EV
 SG_ TirePressureSpare : 55|12@0+ (0.1,0) [0|409.5] "Psi"  Skylark_EV

BO_ 735 TPMS4: 8 Vector__XXX
 SG_ TireTemperatureFL : 7|8@0+ (1,-40) [-40|215] "Deg C"  Skylark_EV
 SG_ TireTemperatureFR : 15|8@0+ (1,-40) [-40|215] "Deg C"  Skylark_EV
 SG_ TireTemperatureRR : 23|8@0+ (1,-40) [-40|215] "Deg C"  Skylark_EV
 SG_ TireTemperatureRL : 31|8@0+ (1,-40) [-40|215] "Deg C"  Skylark_EV
 SG_ TireTemperatureSpare : 39|8@0+ (1,-40) [-40|215] "Deg C"  Skylark_EV

BO_ 744 HU_CCM_VR_Control: 8 Skylark_EV
 SG_ HuCCmFanSpdDuringVR : 5|4@0+ (1,0) [0|15] "" Vector__XXX
 SG_ HuCCmVRSession : 7|2@0+ (1,0) [0|3] "" Vector__XXX

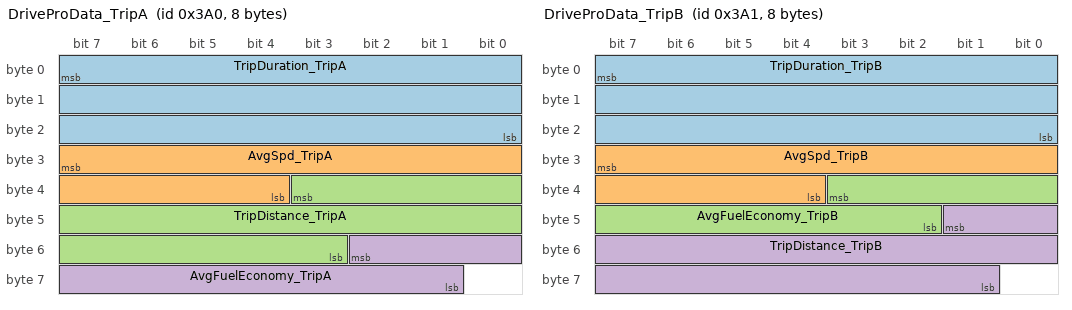
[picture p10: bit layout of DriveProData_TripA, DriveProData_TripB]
BO_ 928 DriveProData_TripA: 8 Vector__XXX
 SG_ TripDuration_TripA : 7|24@0+ (1,0) [0|3600000] "sec"  Skylark_EV
 SG_ AvgSpd_TripA : 31|12@0+ (0.03125,0) [0|127.96875] "m/s"  Skylark_EV
 SG_ TripDistance_TripA : 35|17@0+ (0.1,0) [0|9999.9] "Km"  Skylark_EV
 SG_ AvgFuelEconomy_TripA : 50|10@0+ (0.1,0) [0|99.9] "Km/L"  Skylark_EV

BO_ 929 DriveProData_TripB: 8 Vector__XXX
 SG_ TripDuration_TripB : 7|24@0+ (1,0) [0|3600000] "sec"  Skylark_EV
 SG_ AvgSpd_TripB : 31|12@0+ (0.03125,0) [0|127.96875] "m/s"  Skylark_EV
 SG_ AvgFuelEconomy_TripB : 35|10@0+ (0.1,0) [0|99.9] "Km/L"  Skylark_EV
 SG_ TripDistance_TripB : 41|17@0+ (0.1,0) [0|9999.9] "Km"  Skylark_EV

CM_ SG_ 509 BCmAmbLightModeSelActiveVal "Current Ambient light mode from BCM to HU";
CM_ SG_ 509 BCmAmbLightIllumSelActiveVal "Current Ambient light illumination from BCM to HU";
CM_ SG_ 509 AmbLightIllumPossibleLevels "Ambient Light Number of illumination levels  to be displayed on HU send by BCM";
CM_ SG_ 509 BCmAmbLightData "BCM sends ambient light data frame or give acknowledgement to HU.";
CM_ SG_ 510 HuAmbLightModeSelActiveVal "Current Ambient light illumination from HU to BCM";
CM_ SG_ 510 HuAmbLightIllumSelActiveVal "Current Ambient light illumination from HU to BCM.";
CM_ SG_ 510 HuAmbLightIllumPossibleLevels "Current Ambient light illumination possible values  from HU to BCM.";
CM_ SG_ 510 HuAmbLightData "HU sends ambient light user changed data or give acknowledgement to BCM.";
CM_ SG_ 571 ColorThemeCoDrvr "Gives perticular band of color based on co-driver side ERL level";
CM_ SG_ 571 ColorThemeDrvr "Gives perticular band of color based on driver side ERL level";
CM_ SG_ 571 CcmHuRearBlwrOnOffState "ON/OFF status of Rear Blower to HU";
CM_ SG_ 571 CcmHuUserInterventionBeep "Audio Beep request for the user intervention on touched CCH panel.";
CM_ SG_ 571 AutoDefogState "This signal indicates the state/present condition of Auto defog function";
CM_ SG_ 571 CCmHuExpressCoolSwitchStatus "Indicates whether the Express cooling feature is ON or OFF";
CM_ SG_ 571 CCmHuFanSpdStatus "Indicates the speed of the fan";
CM_ SG_ 571 CCmHuDistribSwitchStatus "Indicates the different distribution modes";
CM_ SG_ 571 CCmHuDualModeSwStatus "Indicates whether the dual mode is ON or OFF";
CM_ SG_ 571 CCmHuTempWhlStatusPass "Indicates the left temperature value in Deg(Physical value range shall be considered as LO,16-30,HI)";
CM_ SG_ 571 CCMHuFreshAirRecircSwitchStatus "Indicates the different values of fresh air recirculation mode";
CM_ SG_ 571 CCmHuAutoSwitchStatus "Indicates whether the Auto mode is ON or OFF";
CM_ SG_ 571 CCmHuTempWhlStatus "Indicates the temperature value in Deg(Physical value range shall be considered as LO,16-30,HI)";
CM_ SG_ 571 CCmHuEconModeSwitchStatus "Indicates whether the Economy AC is ON or OFF";
CM_ SG_ 571 CCmHuMaxDefrstSwitchStatus "Indicates whether the maximum defrost control is ON or OFF";
CM_ SG_ 571 CCmHuRearDefogSwitchStatus "Indicates whether the rear defog control is ON or OFF";
CM_ SG_ 571 CCmHuTempWhlStatusDrvr "Indicates the right temperature value Deg(Physical value range shall be considered as LO,16-30,HI)";
CM_ SG_ 571 CCmHuAirConCompSwitchStatus "Indicates whether the AC is ON or OFF";
CM_ SG_ 571 CCmHuCtrlPnlStatus "Indicates whether the control panel is ON or OFF";
CM_ SG_ 571 CCmHuChangeBit "change bit";
CM_ SG_ 571 CCmHuUserInterventionStatusFlag "Indicates which HVAC control user has operated";
CM_ SG_ 571 CCmHuTempWhlStatusStatus "Indicates the status of the temperature knob";
CM_ SG_ 571 CCmHuErrStatus "CCM Switched Off due to detected failure  Evap Temp  Sens- STB or o/p EvapTemp Sens-STG  Air Distrib Drive Motor - Actuator stuck Air Distrib Drive Motor Line - STB/STG  Air Distri Drv Motor  Line -  STG Air Distrib Drive Motor Drive Line - Op";
CM_ SG_ 571 CCmHuDualModeSwStatusStatus "status information ";
CM_ SG_ 571 CCmHuTempWhlStatusPassStatus "Indicates the status of the Passenger temperature knob";
CM_ SG_ 571 CCmHuTempWhlStatusDrvrStatus "Indicates the status of the Driver temperature knob";
CM_ SG_ 573 LockStateESCL "The current locking state of the ESCL";
CM_ SG_ 573 UnlockStateESCL "The current unlocking state of the ESCL";
CM_ BO_ 651 "Frame to be enabled through DID for X4 ";
CM_ SG_ 651 EPAsStatusGen2 "Status signal of EPAS System for IC and other ECU if required.Ic should glow the lamp if any implausible signal will transmit. ";
CM_ SG_ 651 SAsAngEPAS "Steering Angle information can be used only for comfort function. It has ASIL B.";
CM_ SG_ 651 SAsAngEPAsDir "Steering wheel angle direction";
CM_ SG_ 651 SAsAngEPASStatus "SAS angle status which is showing the plausibilityof this signal";
CM_ SG_ 656 StuckModeAvailability "Availability signal for stuck mode function";
CM_ SG_ 656 StuckModeStateStatus "Current status of the stuck mode function of ABS";
CM_ SG_ 656 StuckModeState "Current state indicated by Stuck mode functionality";
CM_ SG_ 656 WSsPulseCountRearRH "ESP transmits it to HU for navigation purposes.";
CM_ SG_ 656 WSsPulseCountRearLH "ESP transmits it to HU for navigation purposes.";
CM_ SG_ 656 WSsPulseCountFrontRH "ESP transmits it to HU for navigation purposes.";
CM_ SG_ 656 WSsPulseCountFrontLH "ESP transmits it to HU for navigation purposes.";
CM_ SG_ 656 WSsPulseCountFrontRHStatus "ESP transmits it to HU for navigation purposes";
CM_ SG_ 656 WSsPulseCountRearLHStatus "ESP transmits it to HU for navigation purposes";
CM_ SG_ 656 WSsPulseCountRearRHStatus "ESP transmits it to HU for navigation purposes";
CM_ SG_ 656 WSsPulseCountFrontLHStatus "ESP transmits it to HU for navigation purposes";
CM_ SG_ 656 DrvModeIndctnESPStatusNew "Status of the Drive mode indication ESP signal. It is 'Package Protected' signal.";
CM_ SG_ 656 DrvModeIndctnESPNew "Information to ESP to IPC and rotary switch indicating that it has switched to correcpoding mode. It is 'Package Protected' signal.";
CM_ SG_ 693 OATICSig "Signal represents Outside Ambient Temperature raw value evaluated by Instrument Cluster ";
CM_ SG_ 693 BattVoltIPC "Battery voltage evaluated by IPC";
CM_ SG_ 693 ParkBrkState " Signal represents Status of ParkBrake";
CM_ SG_ 693 IcPlatformVariant "IC shall publish its variant type to all partner ECUs.";
CM_ SG_ 693 OATICSigStatus "Signal represents Status of OATSig";
CM_ SG_ 693 IcPresence "IC shall publish its presence to all partner ECUs";
CM_ SG_ 693 SRSWarningLampStatus "AWL Warning Lamp Status from IC";
CM_ SG_ 693 VsSPulseCountSigStatus "Indicates status of VsSPulseCountSig status";
CM_ SG_ 693 VsSPulseCountSig "Signal represents the number of VSS pulses produced.";
CM_ SG_ 693 IcHuVoiceAlertState "IC sends alerts to HU.";
CM_ SG_ 693 IcHuVoiceAlertStateStatus "Status of IcHUVoiceAlert signal";
CM_ SG_ 693 ICCurDriveModeSig "Signal represents the current drive mode selected in Vehicle";
CM_ SG_ 693 IcHuCarImageSelection "Car image selection";
CM_ SG_ 693 IcSbDispReq "Indicates request to infotainment to drive IC display";
CM_ SG_ 693 IcSbrDrvrSeatBeltSwitchStatus "Driver seat belt information";
CM_ SG_ 695 IcHuDTeInfoStatus "Distance to Empty Information Status";
CM_ SG_ 695 IcHuTripAInfo "This signal indicates Trip A info.";
CM_ SG_ 695 IcHuDrvrSeatBeltInfo "Driver seat belt information";
CM_ SG_ 695 IcHuTripBInfo "This signal indicates Trip B info.";
CM_ SG_ 695 IcHuDTeInfo "This signal indicates distance to empty info.";
CM_ SG_ 695 IcHuVehRegion "This signal indicates the  vehicle geography.";
CM_ SG_ 695 IcHuTyreSize "This signal indicates the  vehicle tyre size.";
CM_ SG_ 697 IcHuResetTripB "This signal indicates the Set/Reset of Trip B.";
CM_ SG_ 697 IcHuResetTripA "This signal indicates the Set/Reset of Trip A.";
CM_ SG_ 697 IcHuDriveType "This signal indicates the drive type of vehicle.";
CM_ SG_ 698 IllumDimLvlSetting "Signal represents Dimming Level evaluated by Instrument Cluster";
CM_ SG_ 698 IllumDimLvlSettingStatus "Signal represents Status of Dimming Level Signal";
CM_ SG_ 698 SwitchDimmingControlIPC "Status of Switch Illumination";
CM_ SG_ 698 IllumOnOffCtrlStatus "status of the interior illumination";
CM_ SG_ 698 IllumOnOffCtrl "this signal is used to turn ON/OFF the interior illumination of the individual ECU's";
CM_ SG_ 698 SwitchDimmingControlIPCStatus "Status of Switch Illumination status";
CM_ SG_ 700 IPCRemoteCheckStatus "IPC Remote Engine and AC signal check Status";
CM_ SG_ 700 IPCRemoteCheck "IPC Remote Engine and AC signal check";
CM_ SG_ 700 NextServDueAlertStatus "signal represents the next service due alert status";
CM_ SG_ 700 NextServDueAlert "signal represents the next service due alert ";
CM_ SG_ 700 IcHuServReminderDays "This signal indicates the  service reminder in days.";
CM_ SG_ 700 IcHuServReminderKm "This signal indicates the  service reminder in Kms";
CM_ SG_ 700 IcHuIceState "This information is used   to display or indicate the possibility of snowfall.";
CM_ SG_ 700 IcHuBrakeFluidLowState "This information is used   to display or indicate the Brake fluid low state .";
CM_ SG_ 700 IcHuFastenSeatBeltState "This information is used   to display or indicate the FASTEN SEAT BELT state.";
CM_ SG_ 700 IcHuBatteryChargingState "This information is used   to display or indicate the Battery Charging state .";
CM_ SG_ 700 IcHuServReminderDaysfull "This signal indicates the  service reminder in days.";
CM_ SG_ 702 IcHuOnBoardCompState "Indicates the Function state";
CM_ SG_ 702 IcHuIcInfoFeaturePresenceAck "Media Information in IC";
CM_ SG_ 702 IcHuAlertStateStatus "Alert Status";
CM_ SG_ 702 IcHuAlertType "Informs type of alert";
CM_ SG_ 702 DriveAlert1_TeaBreak "Tea Break alert from IC to HU";
CM_ SG_ 702 IcHuAlertState "IC HU test message details";
CM_ SG_ 704 HuIcSourceNew "Indicating current playing source";
CM_ SG_ 704 GpsCompassPresence "This is to check compass information, available or not in IVI ";
CM_ SG_ 704 GPsCourseInfoIVI "This signal shall be published by IVI . It shall contain GPS Course angle info";
CM_ SG_ 704 GPsCourseInfoStatusIVI "Status of signal GPsCourseInfoStatusIVI";
CM_ SG_ 704 StuckModeUserResponse "User input information for end user";
CM_ SG_ 704 HuIcDistanceDisplayUnitEnum "Indicating navigation next turn round disatnce unit";
CM_ SG_ 704 HuPresence "HU shall publish its presence to all partner ECUs.";
CM_ SG_ 704 HuPlatformVariant "HU shall publish its variant type to all partner ECUs";
CM_ SG_ 704 BattVolt_HU "Battery voltage evaluated by HU";
CM_ SG_ 704 SbIcDispState "Indicates silver box readiness to drive IC display";
CM_ SG_ 704 HuIcAlertStatusAck "Alert delivery status";
CM_ SG_ 704 HuIcAlertStateAck " HU send ack for each alert";
CM_ SG_ 706 HuIcNaviSource "Indicating navigation source type";
CM_ SG_ 706 HuIcCarPlayManeuverType "Indicating car play navigation source type";
CM_ SG_ 706 HuIcNextTurnDistance "Navigation Info In IC";
CM_ SG_ 706 HuIcNextTurnEstimateSec "Navigation Info In IC";
CM_ SG_ 706 HuIcNextTurnRoundDist "Navigation Info In IC";
CM_ SG_ 706 HuIcNextTurnEstimateMin "Navigation Info In IC";
CM_ SG_ 706 HuIcNextTurnSideEnum "Navigation Info In IC";
CM_ SG_ 706 HuIcNextTurnEstimateHrs "Navigation Info In IC";
CM_ SG_ 706 HuIcNextTurnRoundDistUnits "Navigation Info In IC";
CM_ SG_ 706 HuIcNaviStatus "Navigation Info In IC";
CM_ SG_ 706 HuIcNextTurnSide "Navigation Info In IC";
CM_ SG_ 706 HuIcRoundAboutType "Indicating navigation next turn round type";
CM_ SG_ 706 HuIcColorStatus "Theme color from HU to IC";
CM_ SG_ 707 HuIcNextTurnRoundDistUnitsNew "Indicating navigation next turn round disatnce unit";
CM_ SG_ 707 HuIcNextTurnDistanceNew "Indicating navigation next turn distance";
CM_ SG_ 707 LinSwcSbPowerModeCan "It is used to specify LinSwc power mode state";
CM_ SG_ 707 LinSwcIcKey9Can "It is used to specify Reserve key9 state";
CM_ SG_ 707 LinSwcIcKey8Can "It is used to specify Reserve key8 state";
CM_ SG_ 707 LinSwcIcKey7Can "It is used to specify Reserve key7 state";
CM_ SG_ 707 LinSwcIcKey6Can "It is used to specify Reserve key6 state";
CM_ SG_ 707 LinSwcIcViewCan "It is used to specify view Button state";
CM_ SG_ 707 LinSwcIcMenuSelectCan "It is used to specify menu select Button state";
CM_ SG_ 707 LinSwcIcMenuDownCan "It is used to specify menu down Button state";
CM_ SG_ 707 LinSwcIcMenuUpCan "It is used to specify menu up Button state";
CM_ SG_ 707 LinSwcIcpaginationCan "It is used to specify pagination Button state";
CM_ SG_ 707 LinSwcPresenceCanStatus "LinSwcIc shall publish its status to all partner ECUs.";
CM_ SG_ 707 LinSwcIcVariant "LinSwcIc shall publish its variant type to all partner ECUs.";
CM_ SG_ 707 LinSwcPresenceCan "LinSwc shall publish its presence to partner ECUs.";
CM_ SG_ 707 HuIcVoiceAlertStatusAck "HU transmits status of alerts to IC.";
CM_ SG_ 707 HuIcVoiceAlertStateAck "HU Acknowledges to the alert received by IPC.";
CM_ SG_ 710 PDcHuFaultState "This input signal to HU from BCM is to update Rear PDC fault  information.";
CM_ SG_ 710 PDcHuAudioZoneState "This signal is used as an output from BCM to HU to know Audio Zone state for rear PDC.";
CM_ SG_ 710 PDcHuVisualZoneRearLHSensState "It is used as an input to HU from BCM to update the display warning zone from RearLeft Sensor";
CM_ SG_ 710 PDcHuVisualZoneRearMidRHSensStat "It is used as an input to HU from BCM to update the display warning zone from Rear Mid-Right sensor.";
CM_ SG_ 710 PDcHuVisualZoneRearRHSensState "It is used as an input to HU from BCM to update the display warning zone from Rear Right sensor.";
CM_ SG_ 710 PDcHuVisualZoneRearMidLHSensStat "It is used as an input to HU from BCM to update the display warning zone from Rear Mid-Left sensor.";
CM_ SG_ 710 PDcPresence "This is O/P signal from BCM to provide its presence to all ECU in n/w";
CM_ SG_ 710 PDcHuState "This signal is used an input from BCM to HU to know Rear PDC function is Active/Deactive state.";
CM_ SG_ 710 PDcHuPwrModeState "It is used to know PDC power mode.";
CM_ SG_ 710 PDcVariant "This is O/P signal from PDC to provide its variant details to all other ECUs in n/w";
CM_ SG_ 710 PDcHuVisualZoneFrontLHSensState "IIt is used as an input to HU from BCM to update the display warning zone from Rear Left sensor.";
CM_ SG_ 710 PDcHuVisualZoneFrontMidLHSensSta "It is used as an input to HU from BCM to update the display warning zone from Rear Mid-Left sensor.";
CM_ SG_ 710 PDcHuVisualZoneFrontMidRHSensSta "It is used as an input to HU from BCM to update the display warning zone from Rear Mid-Right sensor.";
CM_ SG_ 710 PDcHuVisualZoneFrontRHSensState "It is used as an input to HU from BCM to update the display warning zone from Rear Right sensor.";
CM_ SG_ 710 PDcHuFrontAudioZoneState "This signal is used as an output from BCM to HU to know Audio Zone state for Front PDC";
CM_ SG_ 710 PDcHuFrontFaultState "This input signal to HU from BCM is to update Front PDC fault  information.";
CM_ SG_ 710 PDcHuFrontState "This signal is used an input from BCM to HU to know Front PDC function is Active/Deactive state.";
CM_ SG_ 710 PDcIPcFrontActive "This signal is sent by BCM to IPC for displaying PDC warnings";
CM_ SG_ 710 PDcIPcRearActive "This signal is sent by BCM to IPC for displaying PDC warnings";
CM_ SG_ 711 PDcHuProxFrontLHSensState "IIt is used as an input to HU from BCM to update proximity distance  from Front Left sensor.";
CM_ SG_ 711 PDcHuProxFrontRHSensState "It is used as an input to HU from BCM to update proximity distance  from Front Right sensor.";
CM_ SG_ 711 PDcHuProxFrontMidLHSensState "It is used as an input to HU from BCMto update proximity distance  from Front Mid-Left sensor.";
CM_ SG_ 711 PDcHuProxFrontMidRHSensState "It is used as an input to HU from BCM to update proximity distance  from Front Mid-Right sensor.";
CM_ SG_ 711 PDcHuProxFrontRHSensStateStatus "It is used to know proximity info status.BCM will send Plausible / Implausible status to HU.";
CM_ SG_ 711 PDcHuProxFrontMidRHSensStateStat "It is used to know proximity info status.BCM will send Plausible / Implausible status to HU.";
CM_ SG_ 711 PDcHuProxFrontMidLHSensStateStat "It is used to know proximity info status.BCM will send Plausible / Implausible status to HU.";
CM_ SG_ 711 PDcHuProxFrontLHSensStateStatus "It is used to know proximity info status.BCM will send Plausible / Implausible status to HU.";
CM_ SG_ 712 PDcHuProxRearLHSensState "It is used as an input to HU from BCM to update proximity distance  from Rear Left sensor.";
CM_ SG_ 712 PDcHuProxRearRHSensState "It is used as an input to HU from BCM to update proximity distance  from Rear Right sensor.";
CM_ SG_ 712 PDcHuProxRearMidLHSensState "IIt is used as an input to HU from BCMto update proximity distance  from Rear Mid-Left sensor.";
CM_ SG_ 712 PDcHuProxRearMidRHSensState "It is used as an input to HU from BCM to update proximity distance  from Rear Mid-Right sensor.";
CM_ SG_ 712 PDcHuProxRearRHSensStateStatus "It is used to know proximity info status.BCM will send Plausible / Implausible status to HU.";
CM_ SG_ 712 PDcHuProxRearMidRHSensStateStatu "It is used to know proximity info status.BCM will send Plausible / Implausible status to HU.";
CM_ SG_ 712 PDcHuProxRearMidLHSensStateStatu "It is used to know proximity info status.BCM will send Plausible / Implausible status to HU.";
CM_ SG_ 712 PDcHuProxRearLHSensStateStatus "It is used to know proximity info status.BCM will send Plausible / Implausible status to HU.";
CM_ SG_ 713 HuIcMediaState "Media Information in IC";
CM_ SG_ 713 HuIcSource "Media Information in IC";
CM_ SG_ 713 HuIcAudioVolumeStatus "Media Information in IC";
CM_ SG_ 713 HuIcBTStatus "Media Information in IC";
CM_ SG_ 713 HuIcPlabackCallDurationSec "Media Information in IC";
CM_ SG_ 713 HuIcRepeatOneState "Media Information in IC";
CM_ SG_ 713 HuIcMuteStatus "Media Information in IC";
CM_ SG_ 713 HuIcPlabackCallDurationMin "Media Information in IC";
CM_ SG_ 713 HuIcSMSReceiveState "Media Information in IC";
CM_ SG_ 713 HuIcRepeatState "Media Information in IC";
CM_ SG_ 713 HuIcPlabackCallDurationHrs "Media Information in IC";
CM_ SG_ 713 HuIcPhoneCallStatus "Media Information in IC";
CM_ SG_ 713 HuIcPlaybackElapsedTimeHrs "Media Information in IC";
CM_ SG_ 713 HuIcNetworkSignalStatus "Media Information in IC";
CM_ SG_ 713 HuIcPlaybackElapsedTimeMin "Media Information in IC";
CM_ SG_ 713 HuIcInfoFeaturePresence "Media Information in IC";
CM_ SG_ 713 HuIcShuffleState "Media Information in IC";
CM_ SG_ 713 HuIcPlaybackElapsedTimeSec "Media Information in IC";
CM_ SG_ 715 CcmHuRearBlwrSwitchState "Indicate Rear blower physical switch position";
CM_ SG_ 715 RemoteAcStatus "Plausibility status of Remote AC ON/OFF status from FATC to TCM";
CM_ SG_ 715 RemoteAcState "Remote AC ON/OFF status from FATC to TCM";
CM_ SG_ 715 VehicleInteriorTemp "HVAC receives the raw Interior temperature value from sensor and transmits the same to IPC for global snapshot only";
CM_ SG_ 715 CCmVariantType "Indicates whether CCM is ETC/FATC single or dual zone";
CM_ SG_ 715 CCmPresence " presence of CCM ECU";
CM_ SG_ 715 VehicleInteriorTempStatus "sensor value status";
CM_ SG_ 720 TurnRHTelltaleStatus "Status of the turn right tell-tale





";
CM_ SG_ 720 TurnRHTelltale "IC to display the turn right tell-tale when the right side indicator lamp is active



";
CM_ SG_ 720 TurnLHTelltaleStatus "Status of the turn left tell-tale";
CM_ SG_ 720 TurnLHTelltale "IC to display the turn left tell-tale when the left side indicator lamp is active";
CM_ SG_ 720 PositionLmpTelltaleStatus "Status of the Position Lamp Tell-taleStatus of the Position Lamp Tell-taleStatus of the Position Lamp Tell-tale";
CM_ SG_ 720 PositionLmpTelltale "IC to display the position lamp telltale when the position lamp is active. (For backlight illumination - wherever Telltale is not applicable)IC to display the position lamp telltale when the position lamp is active. (For backlight illumination - wherever Telltale is not applicable)IC to display the position lamp telltale when the position lamp is active. (For backlight illumination - wherever Telltale is not applicable)";
CM_ SG_ 720 BCMVariant "Indicates the BCM variant to other ECU, if BCM is present.";
CM_ SG_ 720 BCMPresence "Indicates the state of the BCM presence to other ECU.";
CM_ SG_ 720 RevGearStatus "Status of the Reverse gear";
CM_ SG_ 720 RevGear "Status of the Reverse gear";
CM_ SG_ 720 LightSensActiveStatus "Status of the Light sensor active";
CM_ SG_ 720 LightSensActive "When an auto light switch is configured as a separate switch and is non-latchable then BCM shall communicate  the light sensor ON status text message signal LightSensorActive via CAN to IC.";
CM_ SG_ 720 RVcPresence "This signal is used as an input from BCM to HU to know if camera is present and if it is what type of camera it is";
CM_ SG_ 722 PowerModeStateMsgCnt "Message counter for E2E-Protection";
CM_ SG_ 722 PowerModeStateCRC "CRC-Checksum over signals for E2E-Protection.";
CM_ SG_ 722 PowerModeStateStatus "This signal is used to verify the correctness of Power Mode Status";
CM_ SG_ 722 PowerModeState "Vehicle power mode signal shall be used by all ECUs of the vehicle for their respective functional implementation";
CM_ SG_ 722 PositionLmpTelltaleStatus "Status of the Position Lamp Tell-taleStatus of the Position Lamp Tell-taleStatus of the Position Lamp Tell-tale";
CM_ SG_ 722 PositionLmpTelltale "IC to display the position lamp telltale when the position lamp is active. (For backlight illumination - wherever Telltale is not applicable)IC to display the position lamp telltale when the position lamp is active. (For backlight illumination - wherever Telltale is not applicable)IC to display the position lamp telltale when the position lamp is active. (For backlight illumination - wherever Telltale is not applicable)";
CM_ SG_ 722 TurnRHTelltale "IC to display the turn right tell-tale when the right side indicator lamp is active



";
CM_ SG_ 722 TurnLHTelltaleStatus "Status of the turn left tell-tale";
CM_ SG_ 722 TurnLHTelltale "IC to display the turn left tell-tale when the left side indicator lamp is active";
CM_ SG_ 722 TurnRHTelltaleStatus "Status of the turn right tell-tale





";
CM_ SG_ 722 BattSaverFnONStatus "Status of the Battery Saver Function ON





";
CM_ SG_ 722 BattSaverFnON "BCM to transmit battery saver active message when the battery saver mode is made active.



";
CM_ SG_ 722 CockpitSigECuStatus "Status of the Cockpit Signal ECU.";
CM_ SG_ 722 CockpitSigECu "BCM sends cockpit signal to other ECUs. It is 'Package Protected' signal.


";
CM_ SG_ 722 VehicleLockStateStatus "Status of the 'VehicleLockState' signal";
CM_ SG_ 722 HighBeamTelltaleStatus "Status of the High Beam Telltale";
CM_ SG_ 722 HighBeamTelltale "IC to display the high beam tell-tale when the high beam lamp is active";
CM_ SG_ 722 VehicleLockState "Vehicle central lock state signal from BCM to PEPS ECU";
CM_ SG_ 729 VehicleMobilizationStateStatus "Status of the VehicleMobilizationState signal";
CM_ SG_ 729 VehicleMobilizationState "Vehicle Mobilization and immobilization  response to prevent vehicle crank";
CM_ SG_ 729 PEPsClampStateMRC "Message counter for E2E-Protection";
CM_ SG_ 729 PEPsClampStateCRC "CRC for E2E protection";
CM_ SG_ 729 PepsHuMrrProximityUnfoldSelState "ORVM Proximity Fold / Unfold function user selection Current state data from Peps to HU";
CM_ SG_ 729 PepsHuMrrProximityUnfoldFuncStat "ORVM Proximity Fold / Unfold feature present/Absent on vehicle data from PEPS to HU for auto-learning";
CM_ SG_ 729 PEPsClampState "PEPS power mode signal shall be used by BCM for it's respective functional implementation";
CM_ SG_ 729 PEPsClampStateStatus "Status of the 'PEPSClampState' signal";
CM_ SG_ 729 PEPsPresence "Indicates the state of the PEPS presence to other ECU.";
CM_ SG_ 729 PEPsKeyInState "PEPS KeyIn state from PEPS to BCM - 'Inside the vehicle / Outside the vehicle'";
CM_ SG_ 732 TpmsTireSensorConfig "TPMS Tire Sensor Configuration";
CM_ SG_ 732 TPMSPresence "TPMS Presence";
CM_ SG_ 732 LowTirePresAlertSpare "Low Tire Pressure Alert Spare";
CM_ SG_ 732 LowTirePresAlertRL "Low Tire Pressure Alert Rear Left";
CM_ SG_ 732 LowTirePresAlertRR "Low Tire Pressure Alert Rear Right";
CM_ SG_ 732 LowTirePresAlertFR "Low Tire Pressure Alert Front Right
";
CM_ SG_ 732 LowTirePresAlertFL "Low Tire Pressure Alert Front Left";
CM_ SG_ 732 HighTirePresAlertSpare "High Tire Pressure Alert Spare";
CM_ SG_ 732 HighTirePresAlertRL "High Tire Pressure Alert Rear Left";
CM_ SG_ 732 HighTirePresAlertRR "High Tire Pressure Alert Rear Right";
CM_ SG_ 732 HighTirePresAlertFR "High Tire Pressure Alert Front Right";
CM_ SG_ 732 HighTirePresAlertFL "High Tire Pressure Alert Front Left";
CM_ SG_ 732 HighTireTempAlertSpare "High Tire Temperature Alert Spart";
CM_ SG_ 732 HighTireTempAlertRL "High Tire Temperature Alert Rear Left";
CM_ SG_ 732 HighTireTempAlertRR "High Tire Temperature Alert Rear Right";
CM_ SG_ 732 HighTireTempAlertFR "High Tire Temperature Alert Front Right";
CM_ SG_ 732 HighTireTempAlertFL "High Tire Temperature Alert Front Left";
CM_ SG_ 732 PresLeakageAlertSpare "Pressure Leakage Alert Spare";
CM_ SG_ 732 PresLeakageAlertRL "Pressure Leakage Alert Rear Left";
CM_ SG_ 732 PresLeakageAlertRR "Pressure Leakage Alert Rear Right";
CM_ SG_ 732 PresLeakageAlertFR "Pressure Leakage Alert Front Right";
CM_ SG_ 732 PresLeakageAlertFL "Pressure Leakage Alert Front Left";
CM_ SG_ 732 TpmsAlertStatus "PMS Alert Status";
CM_ SG_ 732 TpmsReceiverRXFault "TPMS Receiver Rx Fault";
CM_ SG_ 732 SensorMalfncFaultSpare "Sensor Malfunction Fault Spare";
CM_ SG_ 732 SensorMalfncFaultRL "Sensor Malfunction Fault Rear Left";
CM_ SG_ 732 SensorMalfncFaultRR "Sensor Malfunction Fault Rear Right";
CM_ SG_ 732 SensorMalfncFaultFR "Sensor Malfunction Fault Front Right
";
CM_ SG_ 732 SensorMalfncFaultFL "Sensor Malfunction Fault Front Left";
CM_ SG_ 732 TpmsFaultStatus "TPMS Fault Status";
CM_ SG_ 732 TpmsNotLearntFault "TPMS Not Learnt Fault";
CM_ SG_ 732 SensorMissingFaultRL "Sensor Missing Fault Rear Left";
CM_ SG_ 732 SensorMissingFaultRR "Sensor Missing Fault Rear Right";
CM_ SG_ 732 SensorMissingFaultFR "Sensor Missing Fault Front Right";
CM_ SG_ 732 SensorMissingFaultFL "Sensor Missing Fault Front Left";
CM_ SG_ 732 TpmsLearnStatus "TPMS Learning Status";
CM_ SG_ 732 SpareTireSwapFlagRL "Spare Tire Swap Flag Rear Left";
CM_ SG_ 732 SpareTireSwapFlagRR "Spare Tire Swap Flag Rear Right";
CM_ SG_ 732 SpareTireSwapFlagFR "Spare Tire Swap Flag Front Right";
CM_ SG_ 732 SpareTireSwapFlagFL "Spare Tire Swap Flag Front Left";
CM_ SG_ 732 SensorLearningStatus "Tire Sensor Learning Status";
CM_ SG_ 732 SensorDetectFlagSpare "Sensor Detect Flag Spare";
CM_ SG_ 732 SensorDetectFlagRL "Sensor Detect Flag Rear Left";
CM_ SG_ 732 SensorDetectFlagRR "Sensor Detect Flag Rear Right";
CM_ SG_ 732 SensorDetectFlagFR "Sensor Detect Flag Front Right";
CM_ SG_ 732 SensorDetectFlagFL "Sensor Detect Flag Front Left";
CM_ SG_ 733 SensorIDnotLearntSpare "Sensor ID Not Learnt Spare";
CM_ SG_ 733 SensorIDnotLearntRL "Sensor ID Not Learnt Rear Left";
CM_ SG_ 733 SensorIDnotLearntRR "Sensor ID Not Learnt Rear Right";
CM_ SG_ 733 SensorIDnotLearntFR "Sensor ID Not Learnt Front Right";
CM_ SG_ 733 SensorIDnotLearntFL "Sensor ID Not Learnt Front Left";
CM_ BO_ 734 "TPMS Test Msg";
CM_ SG_ 734 TirePressureFL "Tire Pressure Front Left Tire";
CM_ SG_ 734 TirePressureFR "Tire Pressure Front Right Tire";
CM_ SG_ 734 TirePressureRR "Tire Pressure Rear Right Tire";
CM_ SG_ 734 TirePressureRL "Tire Pressure Rear Left Tire";
CM_ SG_ 734 TirePressureSpare "Tire Pressure Spare Tire";
CM_ BO_ 735 "TPMS Test Msg";
CM_ SG_ 735 TireTemperatureFL "Tire Temperature Front Left Tire";
CM_ SG_ 735 TireTemperatureFR "Tire Temperature Front Right Tire";
CM_ SG_ 735 TireTemperatureRR "Tire Temperature Rear Right Tire";
CM_ SG_ 735 TireTemperatureRL "Tire Temperature Rear Left Tire";
CM_ SG_ 735 TireTemperatureSpare "Tire Temperature Spare Tire";
CM_ SG_ 744 HuCCmFanSpdDuringVR "HU should tell to CCM about the FAN speed during VR seesion active";
CM_ SG_ 744 HuCCmVRSession "HU should tell to CCM about the VR session state";
CM_ SG_ 928 TripDuration_TripA "IC shall send Trip A Duration to HU";
CM_ SG_ 928 AvgSpd_TripA "IC shall send Trip A Average speed to HU";
CM_ SG_ 928 TripDistance_TripA "IC shall send Trip A Distance to HU";
CM_ SG_ 928 AvgFuelEconomy_TripA "IC shall send Trip A Average  Fuel Economy to HU";
CM_ SG_ 929 TripDuration_TripB "IC shall send  Trip B Duration to HU";
CM_ SG_ 929 AvgSpd_TripB "IC shall send TripB Average speed to HU";
CM_ SG_ 929 AvgFuelEconomy_TripB "IC shall send Trip B Average  Fuel Economy to HU";
CM_ SG_ 929 TripDistance_TripB "IC shall send Trip B Distance to HU";
BA_DEF_ SG_  "Remarks" STRING ;
BA_DEF_ SG_  "NWM_WakeupAllowed" ENUM  "No","Yes";
BA_DEF_ SG_  "GenSigTimeoutTime_HU_Mid_X451" INT 0 65535;
BA_DEF_ SG_  "GenSigTimeoutTime_HU_High_X451" INT 0 65535;
BA_DEF_ SG_  "GenSigTimeoutTime_HU_B" INT 0 65535;
BA_DEF_ SG_  "GenSigTimeoutTime_HU_A" INT 0 65535;
BA_DEF_ SG_  "GenSigTimeoutTime_BCM_Mid" INT 0 65535;
BA_DEF_ SG_  "GenSigTimeoutMsg_HU_Mid_X451" INT 0 65535;
BA_DEF_ SG_  "GenSigTimeoutMsg_HU_High_X451" INT 0 65535;
BA_DEF_ SG_  "GenSigTimeoutMsg_HU_B" INT 0 65535;
BA_DEF_ SG_  "GenSigTimeoutMsg_HU_A" INT 0 65535;
BA_DEF_ SG_  "GenSigStartValue" INT 0 0;
BA_DEF_ SG_  "GenSigSendType" ENUM  "Cyclic","OnWrite","OnWriteWithRepetition","OnChange","OnChangeWithRepetition","IfActive","IfActiveWithRepetition","NoSigSendType","NotUsed","NotUsed","NotUsed","NotUsed","NotUsed";
BA_DEF_ SG_  "GenSigInactiveValue" INT 0 0;
BA_DEF_ SG_  "GenSigEnvVarType" ENUM  "int","float","undef";
BA_DEF_ SG_  "GenSigCycleTimeActive" INT 0 0;
BA_DEF_ SG_  "GenSigCycleTime" INT 0 0;
BA_DEF_ SG_  "GenSigTimeoutMsg_HU_High_X445" INT 0 65535;
BA_DEF_ SG_  "GenSigTimeoutMsg_HU_Mid_X445" INT 0 65535;
BA_DEF_ SG_  "GenSigTimeoutTime_HU_High_X445" INT 0 65535;
BA_DEF_ SG_  "GenSigTimeoutTime_HU_Mid_X445" INT 0 65535;
BA_DEF_ SG_  "GenSigTimeoutMsg_IVI" INT 0 65535;
BA_DEF_ SG_  "GenSigTimeoutTime_IVI" INT 0 65535;
BA_DEF_ BO_  "NmMessage" ENUM  "no","yes";
BA_DEF_ BO_  "NmAsrMessage" ENUM  "<n.a.>","No","Yes";
BA_DEF_ BO_  "MessageTimeout" INT 0 65535;
BA_DEF_ BO_  "GenMsgStartDelayTime" INT 0 0;
BA_DEF_ BO_  "GenMsgSendType" ENUM  "Cyclic","NotUsed","NotUsed","NotUsed","NotUsed","NotUsed","NotUsed","IfActive","NoMsgSendType","NotUsed";
BA_DEF_ BO_  "GenMsgNrOfRepetition" INT 0 0;
BA_DEF_ BO_  "GenMsgILSupport" ENUM  "No","Yes";
BA_DEF_ BO_  "GenMsgDelayTime" INT 0 0;
BA_DEF_ BO_  "GenMsgCycleTimeFast" INT 0 0;
BA_DEF_ BO_  "GenMsgCycleTime" INT 0 0;
BA_DEF_ BO_  "DiagUudtResponse" ENUM  "false","true";
BA_DEF_ BO_  "DiagUsdtResponse" ENUM  "false","true";
BA_DEF_ BO_  "DiagState" ENUM  "No","Yes";
BA_DEF_ BO_  "DiagResponse" ENUM  "No","Yes";
BA_DEF_ BO_  "DiagRequest" ENUM  "No","Yes";
BA_DEF_ BO_  "MsgType" ENUM  "Application","NM","NMH";
BA_DEF_ SG_  "SystemSignalLongSymbol" STRING ;
BA_DEF_DEF_  "Remarks" "null";
BA_DEF_DEF_  "NWM_WakeupAllowed" "No";
BA_DEF_DEF_  "GenSigTimeoutTime_HU_Mid_X451" 500;
BA_DEF_DEF_  "GenSigTimeoutTime_HU_High_X451" 500;
BA_DEF_DEF_  "GenSigTimeoutTime_HU_B" 500;
BA_DEF_DEF_  "GenSigTimeoutTime_HU_A" 500;
BA_DEF_DEF_  "GenSigTimeoutTime_BCM_Mid" 0;
BA_DEF_DEF_  "GenSigTimeoutMsg_HU_Mid_X451" 500;
BA_DEF_DEF_  "GenSigTimeoutMsg_HU_High_X451" 500;
BA_DEF_DEF_  "GenSigTimeoutMsg_HU_B" 500;
BA_DEF_DEF_  "GenSigTimeoutMsg_HU_A" 500;
BA_DEF_DEF_  "GenSigStartValue" 0;
BA_DEF_DEF_  "GenSigSendType" "Cyclic";
BA_DEF_DEF_  "GenSigInactiveValue" 0;
BA_DEF_DEF_  "GenSigEnvVarType" "undef";
BA_DEF_DEF_  "GenSigCycleTimeActive" 0;
BA_DEF_DEF_  "GenSigCycleTime" 0;
BA_DEF_DEF_  "GenSigTimeoutMsg_HU_High_X445" 500;
BA_DEF_DEF_  "GenSigTimeoutMsg_HU_Mid_X445" 500;
BA_DEF_DEF_  "GenSigTimeoutTime_HU_High_X445" 500;
BA_DEF_DEF_  "GenSigTimeoutTime_HU_Mid_X445" 500;
BA_DEF_DEF_  "GenSigTimeoutMsg_IVI" 500;
BA_DEF_DEF_  "GenSigTimeoutTime_IVI" 500;
BA_DEF_DEF_  "NmMessage" "no";
BA_DEF_DEF_  "NmAsrMessage" "<n.a.>";
BA_DEF_DEF_  "MessageTimeout" 500;
BA_DEF_DEF_  "GenMsgStartDelayTime" 0;
BA_DEF_DEF_  "GenMsgSendType" "Cyclic";
BA_DEF_DEF_  "GenMsgNrOfRepetition" 0;
BA_DEF_DEF_  "GenMsgILSupport" "Yes";
BA_DEF_DEF_  "GenMsgDelayTime" 0;
BA_DEF_DEF_  "GenMsgCycleTimeFast" 0;
BA_DEF_DEF_  "GenMsgCycleTime" 0;
BA_DEF_DEF_  "DiagUudtResponse" "false";
BA_DEF_DEF_  "DiagUsdtResponse" "false";
BA_DEF_DEF_  "DiagState" "No";
BA_DEF_DEF_  "DiagResponse" "No";
BA_DEF_DEF_  "DiagRequest" "No";
BA_DEF_DEF_  "MsgType" "Application";
BA_DEF_DEF_  "SystemSignalLongSymbol" "";
BA_ "MessageTimeout" BO_ 509 0;
BA_ "GenMsgSendType" BO_ 509 8;
BA_ "MessageTimeout" BO_ 510 0;
BA_ "GenMsgSendType" BO_ 510 8;
BA_ "GenMsgCycleTime" BO_ 571 50;
BA_ "GenMsgCycleTime" BO_ 573 50;
BA_ "GenMsgCycleTime" BO_ 651 100;
BA_ "GenMsgCycleTime" BO_ 656 100;
BA_ "GenMsgStartDelayTime" BO_ 693 5;
BA_ "GenMsgCycleTime" BO_ 693 100;
BA_ "GenMsgStartDelayTime" BO_ 695 10;
BA_ "GenMsgCycleTime" BO_ 695 100;
BA_ "GenMsgStartDelayTime" BO_ 697 15;
BA_ "GenMsgCycleTime" BO_ 697 100;
BA_ "GenMsgCycleTime" BO_ 698 100;
BA_ "GenMsgStartDelayTime" BO_ 700 25;
BA_ "GenMsgCycleTime" BO_ 700 100;
BA_ "GenMsgCycleTime" BO_ 702 100;
BA_ "GenMsgCycleTime" BO_ 704 100;
BA_ "GenMsgCycleTime" BO_ 706 100;
BA_ "GenMsgStartDelayTime" BO_ 707 5;
BA_ "GenMsgCycleTime" BO_ 707 100;
BA_ "GenMsgCycleTime" BO_ 710 100;
BA_ "GenMsgCycleTime" BO_ 711 100;
BA_ "GenMsgStartDelayTime" BO_ 712 10;
BA_ "GenMsgCycleTime" BO_ 712 100;
BA_ "GenMsgCycleTime" BO_ 713 100;
BA_ "GenMsgCycleTime" BO_ 715 100;
BA_ "GenMsgCycleTime" BO_ 720 100;
BA_ "GenMsgStartDelayTime" BO_ 722 10;
BA_ "GenMsgCycleTime" BO_ 722 100;
BA_ "GenMsgCycleTime" BO_ 729 100;
BA_ "GenMsgCycleTime" BO_ 732 100;
BA_ "GenMsgCycleTime" BO_ 733 100;
BA_ "GenMsgCycleTime" BO_ 734 100;
BA_ "GenMsgCycleTime" BO_ 735 100;
BA_ "MessageTimeout" BO_ 744 1000;
BA_ "GenMsgCycleTime" BO_ 744 200;
BA_ "MessageTimeout" BO_ 928 2500;
BA_ "GenMsgCycleTime" BO_ 928 500;
BA_ "MessageTimeout" BO_ 929 2500;
BA_ "GenMsgCycleTime" BO_ 929 500;
BA_ "GenSigTimeoutTime_HU_Mid_X451" SG_ 509 BCmAmbLightModeSelActiveVal 0;
BA_ "GenSigTimeoutTime_HU_High_X451" SG_ 509 BCmAmbLightModeSelActiveVal 0;
BA_ "GenSigTimeoutTime_HU_B" SG_ 509 BCmAmbLightModeSelActiveVal 0;
BA_ "GenSigTimeoutTime_HU_A" SG_ 509 BCmAmbLightModeSelActiveVal 0;
BA_ "GenSigTimeoutMsg_HU_Mid_X451" SG_ 509 BCmAmbLightModeSelActiveVal 0;
BA_ "GenSigTimeoutMsg_HU_High_X451" SG_ 509 BCmAmbLightModeSelActiveVal 0;
BA_ "GenSigTimeoutMsg_HU_B" SG_ 509 BCmAmbLightModeSelActiveVal 0;
BA_ "GenSigTimeoutMsg_HU_A" SG_ 509 BCmAmbLightModeSelActiveVal 0;
BA_ "GenSigSendType" SG_ 509 BCmAmbLightModeSelActiveVal 1;
BA_ "GenSigTimeoutMsg_HU_High_X445" SG_ 509 BCmAmbLightModeSelActiveVal 0;
BA_ "GenSigTimeoutMsg_HU_Mid_X445" SG_ 509 BCmAmbLightModeSelActiveVal 0;
BA_ "GenSigTimeoutTime_HU_High_X445" SG_ 509 BCmAmbLightModeSelActiveVal 0;
BA_ "GenSigTimeoutTime_HU_Mid_X445" SG_ 509 BCmAmbLightModeSelActiveVal 0;
BA_ "GenSigTimeoutMsg_IVI" SG_ 509 BCmAmbLightModeSelActiveVal 0;
BA_ "GenSigTimeoutTime_IVI" SG_ 509 BCmAmbLightModeSelActiveVal 0;
BA_ "GenSigTimeoutTime_HU_Mid_X451" SG_ 509 BCmAmbLightIllumSelActiveVal 0;
BA_ "GenSigTimeoutTime_HU_High_X451" SG_ 509 BCmAmbLightIllumSelActiveVal 0;
BA_ "GenSigTimeoutTime_HU_B" SG_ 509 BCmAmbLightIllumSelActiveVal 0;
BA_ "GenSigTimeoutTime_HU_A" SG_ 509 BCmAmbLightIllumSelActiveVal 0;
BA_ "GenSigTimeoutMsg_HU_Mid_X451" SG_ 509 BCmAmbLightIllumSelActiveVal 0;
BA_ "GenSigTimeoutMsg_HU_High_X451" SG_ 509 BCmAmbLightIllumSelActiveVal 0;
BA_ "GenSigTimeoutMsg_HU_B" SG_ 509 BCmAmbLightIllumSelActiveVal 0;
BA_ "GenSigTimeoutMsg_HU_A" SG_ 509 BCmAmbLightIllumSelActiveVal 0;
BA_ "GenSigStartValue" SG_ 509 BCmAmbLightIllumSelActiveVal 5;
BA_ "GenSigSendType" SG_ 509 BCmAmbLightIllumSelActiveVal 1;
BA_ "GenSigTimeoutMsg_HU_High_X445" SG_ 509 BCmAmbLightIllumSelActiveVal 0;
BA_ "GenSigTimeoutMsg_HU_Mid_X445" SG_ 509 BCmAmbLightIllumSelActiveVal 0;
BA_ "GenSigTimeoutTime_HU_High_X445" SG_ 509 BCmAmbLightIllumSelActiveVal 0;
BA_ "GenSigTimeoutTime_HU_Mid_X445" SG_ 509 BCmAmbLightIllumSelActiveVal 0;
BA_ "GenSigTimeoutMsg_IVI" SG_ 509 BCmAmbLightIllumSelActiveVal 0;
BA_ "GenSigTimeoutTime_IVI" SG_ 509 BCmAmbLightIllumSelActiveVal 0;
BA_ "GenSigTimeoutTime_HU_Mid_X451" SG_ 509 AmbLightIllumPossibleLevels 0;
BA_ "GenSigTimeoutTime_HU_High_X451" SG_ 509 AmbLightIllumPossibleLevels 0;
BA_ "GenSigTimeoutTime_HU_B" SG_ 509 AmbLightIllumPossibleLevels 0;
BA_ "GenSigTimeoutTime_HU_A" SG_ 509 AmbLightIllumPossibleLevels 0;
BA_ "GenSigTimeoutMsg_HU_Mid_X451" SG_ 509 AmbLightIllumPossibleLevels 0;
BA_ "GenSigTimeoutMsg_HU_High_X451" SG_ 509 AmbLightIllumPossibleLevels 0;
BA_ "GenSigTimeoutMsg_HU_B" SG_ 509 AmbLightIllumPossibleLevels 0;
BA_ "GenSigTimeoutMsg_HU_A" SG_ 509 AmbLightIllumPossibleLevels 0;
BA_ "GenSigStartValue" SG_ 509 AmbLightIllumPossibleLevels 5;
BA_ "GenSigSendType" SG_ 509 AmbLightIllumPossibleLevels 1;
BA_ "GenSigTimeoutMsg_HU_High_X445" SG_ 509 AmbLightIllumPossibleLevels 0;
BA_ "GenSigTimeoutMsg_HU_Mid_X445" SG_ 509 AmbLightIllumPossibleLevels 0;
BA_ "GenSigTimeoutTime_HU_High_X445" SG_ 509 AmbLightIllumPossibleLevels 0;
BA_ "GenSigTimeoutTime_HU_Mid_X445" SG_ 509 AmbLightIllumPossibleLevels 0;
BA_ "GenSigTimeoutMsg_IVI" SG_ 509 AmbLightIllumPossibleLevels 0;
BA_ "GenSigTimeoutTime_IVI" SG_ 509 AmbLightIllumPossibleLevels 0;
BA_ "GenSigTimeoutTime_HU_Mid_X451" SG_ 509 BCmAmbLightData 0;
BA_ "GenSigTimeoutTime_HU_High_X451" SG_ 509 BCmAmbLightData 0;
BA_ "GenSigTimeoutTime_HU_B" SG_ 509 BCmAmbLightData 0;
BA_ "GenSigTimeoutTime_HU_A" SG_ 509 BCmAmbLightData 0;
BA_ "GenSigTimeoutMsg_HU_Mid_X451" SG_ 509 BCmAmbLightData 0;
BA_ "GenSigTimeoutMsg_HU_High_X451" SG_ 509 BCmAmbLightData 0;
BA_ "GenSigTimeoutMsg_HU_B" SG_ 509 BCmAmbLightData 0;
BA_ "GenSigTimeoutMsg_HU_A" SG_ 509 BCmAmbLightData 0;
BA_ "GenSigStartValue" SG_ 509 BCmAmbLightData 2;
BA_ "GenSigSendType" SG_ 509 BCmAmbLightData 1;
BA_ "GenSigTimeoutMsg_HU_High_X445" SG_ 509 BCmAmbLightData 0;
BA_ "GenSigTimeoutMsg_HU_Mid_X445" SG_ 509 BCmAmbLightData 0;
BA_ "GenSigTimeoutTime_HU_High_X445" SG_ 509 BCmAmbLightData 0;
BA_ "GenSigTimeoutTime_HU_Mid_X445" SG_ 509 BCmAmbLightData 0;
BA_ "GenSigTimeoutMsg_IVI" SG_ 509 BCmAmbLightData 0;
BA_ "GenSigTimeoutTime_IVI" SG_ 509 BCmAmbLightData 0;
BA_ "GenSigTimeoutTime_HU_Mid_X451" SG_ 510 HuAmbLightModeSelActiveVal 0;
BA_ "GenSigTimeoutTime_HU_High_X451" SG_ 510 HuAmbLightModeSelActiveVal 0;
BA_ "GenSigTimeoutTime_HU_B" SG_ 510 HuAmbLightModeSelActiveVal 0;
BA_ "GenSigTimeoutTime_HU_A" SG_ 510 HuAmbLightModeSelActiveVal 0;
BA_ "GenSigTimeoutMsg_HU_Mid_X451" SG_ 510 HuAmbLightModeSelActiveVal 0;
BA_ "GenSigTimeoutMsg_HU_High_X451" SG_ 510 HuAmbLightModeSelActiveVal 0;
BA_ "GenSigTimeoutMsg_HU_B" SG_ 510 HuAmbLightModeSelActiveVal 0;
BA_ "GenSigTimeoutMsg_HU_A" SG_ 510 HuAmbLightModeSelActiveVal 0;
BA_ "GenSigSendType" SG_ 510 HuAmbLightModeSelActiveVal 1;
BA_ "GenSigTimeoutMsg_HU_High_X445" SG_ 510 HuAmbLightModeSelActiveVal 0;
BA_ "GenSigTimeoutMsg_HU_Mid_X445" SG_ 510 HuAmbLightModeSelActiveVal 0;
BA_ "GenSigTimeoutTime_HU_High_X445" SG_ 510 HuAmbLightModeSelActiveVal 0;
BA_ "GenSigTimeoutTime_HU_Mid_X445" SG_ 510 HuAmbLightModeSelActiveVal 0;
BA_ "GenSigTimeoutMsg_IVI" SG_ 510 HuAmbLightModeSelActiveVal 0;
BA_ "GenSigTimeoutTime_IVI" SG_ 510 HuAmbLightModeSelActiveVal 0;
BA_ "GenSigTimeoutTime_HU_Mid_X451" SG_ 510 HuAmbLightIllumSelActiveVal 0;
BA_ "GenSigTimeoutTime_HU_High_X451" SG_ 510 HuAmbLightIllumSelActiveVal 0;
BA_ "GenSigTimeoutTime_HU_B" SG_ 510 HuAmbLightIllumSelActiveVal 0;
BA_ "GenSigTimeoutTime_HU_A" SG_ 510 HuAmbLightIllumSelActiveVal 0;
BA_ "GenSigTimeoutMsg_HU_Mid_X451" SG_ 510 HuAmbLightIllumSelActiveVal 0;
BA_ "GenSigTimeoutMsg_HU_High_X451" SG_ 510 HuAmbLightIllumSelActiveVal 0;
BA_ "GenSigTimeoutMsg_HU_B" SG_ 510 HuAmbLightIllumSelActiveVal 0;
BA_ "GenSigTimeoutMsg_HU_A" SG_ 510 HuAmbLightIllumSelActiveVal 0;
BA_ "GenSigSendType" SG_ 510 HuAmbLightIllumSelActiveVal 1;
BA_ "GenSigTimeoutMsg_HU_High_X445" SG_ 510 HuAmbLightIllumSelActiveVal 0;
BA_ "GenSigTimeoutMsg_HU_Mid_X445" SG_ 510 HuAmbLightIllumSelActiveVal 0;
BA_ "GenSigTimeoutTime_HU_High_X445" SG_ 510 HuAmbLightIllumSelActiveVal 0;
BA_ "GenSigTimeoutTime_HU_Mid_X445" SG_ 510 HuAmbLightIllumSelActiveVal 0;
BA_ "GenSigTimeoutMsg_IVI" SG_ 510 HuAmbLightIllumSelActiveVal 0;
BA_ "GenSigTimeoutTime_IVI" SG_ 510 HuAmbLightIllumSelActiveVal 0;
BA_ "GenSigTimeoutTime_HU_Mid_X451" SG_ 510 HuAmbLightIllumPossibleLevels 0;
BA_ "GenSigTimeoutTime_HU_High_X451" SG_ 510 HuAmbLightIllumPossibleLevels 0;
BA_ "GenSigTimeoutTime_HU_B" SG_ 510 HuAmbLightIllumPossibleLevels 0;
BA_ "GenSigTimeoutTime_HU_A" SG_ 510 HuAmbLightIllumPossibleLevels 0;
BA_ "GenSigTimeoutMsg_HU_Mid_X451" SG_ 510 HuAmbLightIllumPossibleLevels 0;
BA_ "GenSigTimeoutMsg_HU_High_X451" SG_ 510 HuAmbLightIllumPossibleLevels 0;
BA_ "GenSigTimeoutMsg_HU_B" SG_ 510 HuAmbLightIllumPossibleLevels 0;
BA_ "GenSigTimeoutMsg_HU_A" SG_ 510 HuAmbLightIllumPossibleLevels 0;
BA_ "GenSigSendType" SG_ 510 HuAmbLightIllumPossibleLevels 1;
BA_ "GenSigTimeoutMsg_HU_High_X445" SG_ 510 HuAmbLightIllumPossibleLevels 0;
BA_ "GenSigTimeoutMsg_HU_Mid_X445" SG_ 510 HuAmbLightIllumPossibleLevels 0;
BA_ "GenSigTimeoutTime_HU_High_X445" SG_ 510 HuAmbLightIllumPossibleLevels 0;
BA_ "GenSigTimeoutTime_HU_Mid_X445" SG_ 510 HuAmbLightIllumPossibleLevels 0;
BA_ "GenSigTimeoutMsg_IVI" SG_ 510 HuAmbLightIllumPossibleLevels 0;
BA_ "GenSigTimeoutTime_IVI" SG_ 510 HuAmbLightIllumPossibleLevels 0;
BA_ "GenSigTimeoutTime_HU_Mid_X451" SG_ 510 HuAmbLightData 0;
BA_ "GenSigTimeoutTime_HU_High_X451" SG_ 510 HuAmbLightData 0;
BA_ "GenSigTimeoutTime_HU_B" SG_ 510 HuAmbLightData 0;
BA_ "GenSigTimeoutTime_HU_A" SG_ 510 HuAmbLightData 0;
BA_ "GenSigTimeoutMsg_HU_Mid_X451" SG_ 510 HuAmbLightData 0;
BA_ "GenSigTimeoutMsg_HU_High_X451" SG_ 510 HuAmbLightData 0;
BA_ "GenSigTimeoutMsg_HU_B" SG_ 510 HuAmbLightData 0;
BA_ "GenSigTimeoutMsg_HU_A" SG_ 510 HuAmbLightData 0;
BA_ "GenSigSendType" SG_ 510 HuAmbLightData 1;
BA_ "GenSigTimeoutMsg_HU_High_X445" SG_ 510 HuAmbLightData 0;
BA_ "GenSigTimeoutMsg_HU_Mid_X445" SG_ 510 HuAmbLightData 0;
BA_ "GenSigTimeoutTime_HU_High_X445" SG_ 510 HuAmbLightData 0;
BA_ "GenSigTimeoutTime_HU_Mid_X445" SG_ 510 HuAmbLightData 0;
BA_ "GenSigTimeoutMsg_IVI" SG_ 510 HuAmbLightData 0;
BA_ "GenSigTimeoutTime_IVI" SG_ 510 HuAmbLightData 0;
BA_ "GenSigSendType" SG_ 571 ColorThemeCoDrvr 7;
BA_ "GenSigCycleTimeActive" SG_ 571 ColorThemeCoDrvr 50;
BA_ "GenSigCycleTime" SG_ 571 ColorThemeCoDrvr 50;
BA_ "GenSigSendType" SG_ 571 ColorThemeDrvr 7;
BA_ "GenSigCycleTimeActive" SG_ 571 ColorThemeDrvr 50;
BA_ "GenSigCycleTime" SG_ 571 ColorThemeDrvr 50;
BA_ "GenSigSendType" SG_ 571 CcmHuRearBlwrOnOffState 7;
BA_ "GenSigCycleTimeActive" SG_ 571 CcmHuRearBlwrOnOffState 50;
BA_ "GenSigCycleTime" SG_ 571 CcmHuRearBlwrOnOffState 50;
BA_ "GenSigSendType" SG_ 571 CcmHuUserInterventionBeep 7;
BA_ "GenSigCycleTimeActive" SG_ 571 CcmHuUserInterventionBeep 50;
BA_ "GenSigCycleTime" SG_ 571 CcmHuUserInterventionBeep 50;
BA_ "GenSigSendType" SG_ 571 AutoDefogState 7;
BA_ "GenSigCycleTimeActive" SG_ 571 AutoDefogState 50;
BA_ "GenSigCycleTime" SG_ 571 AutoDefogState 50;
BA_ "GenSigSendType" SG_ 571 CCmHuExpressCoolSwitchStatus 7;
BA_ "GenSigCycleTimeActive" SG_ 571 CCmHuExpressCoolSwitchStatus 50;
BA_ "GenSigCycleTime" SG_ 571 CCmHuExpressCoolSwitchStatus 50;
BA_ "GenSigSendType" SG_ 571 CCmHuFanSpdStatus 7;
BA_ "GenSigCycleTimeActive" SG_ 571 CCmHuFanSpdStatus 50;
BA_ "GenSigCycleTime" SG_ 571 CCmHuFanSpdStatus 50;
BA_ "GenSigSendType" SG_ 571 CCmHuDistribSwitchStatus 7;
BA_ "GenSigCycleTimeActive" SG_ 571 CCmHuDistribSwitchStatus 50;
BA_ "GenSigCycleTime" SG_ 571 CCmHuDistribSwitchStatus 50;
BA_ "GenSigSendType" SG_ 571 CCmHuDualModeSwStatus 7;
BA_ "GenSigCycleTimeActive" SG_ 571 CCmHuDualModeSwStatus 50;
BA_ "GenSigCycleTime" SG_ 571 CCmHuDualModeSwStatus 50;
BA_ "GenSigSendType" SG_ 571 CCmHuTempWhlStatusPass 7;
BA_ "GenSigCycleTimeActive" SG_ 571 CCmHuTempWhlStatusPass 50;
BA_ "GenSigCycleTime" SG_ 571 CCmHuTempWhlStatusPass 50;
BA_ "GenSigSendType" SG_ 571 CCMHuFreshAirRecircSwitchStatus 7;
BA_ "GenSigCycleTimeActive" SG_ 571 CCMHuFreshAirRecircSwitchStatus 50;
BA_ "GenSigCycleTime" SG_ 571 CCMHuFreshAirRecircSwitchStatus 50;
BA_ "GenSigSendType" SG_ 571 CCmHuAutoSwitchStatus 7;
BA_ "GenSigCycleTimeActive" SG_ 571 CCmHuAutoSwitchStatus 50;
BA_ "GenSigCycleTime" SG_ 571 CCmHuAutoSwitchStatus 50;
BA_ "GenSigSendType" SG_ 571 CCmHuTempWhlStatus 7;
BA_ "GenSigCycleTimeActive" SG_ 571 CCmHuTempWhlStatus 50;
BA_ "GenSigCycleTime" SG_ 571 CCmHuTempWhlStatus 50;
BA_ "GenSigSendType" SG_ 571 CCmHuEconModeSwitchStatus 7;
BA_ "GenSigCycleTimeActive" SG_ 571 CCmHuEconModeSwitchStatus 50;
BA_ "GenSigCycleTime" SG_ 571 CCmHuEconModeSwitchStatus 50;
BA_ "GenSigSendType" SG_ 571 CCmHuMaxDefrstSwitchStatus 7;
BA_ "GenSigCycleTimeActive" SG_ 571 CCmHuMaxDefrstSwitchStatus 50;
BA_ "GenSigCycleTime" SG_ 571 CCmHuMaxDefrstSwitchStatus 50;
BA_ "GenSigSendType" SG_ 571 CCmHuRearDefogSwitchStatus 7;
BA_ "GenSigCycleTimeActive" SG_ 571 CCmHuRearDefogSwitchStatus 50;
BA_ "GenSigCycleTime" SG_ 571 CCmHuRearDefogSwitchStatus 50;
BA_ "GenSigSendType" SG_ 571 CCmHuTempWhlStatusDrvr 7;
BA_ "GenSigCycleTimeActive" SG_ 571 CCmHuTempWhlStatusDrvr 50;
BA_ "GenSigCycleTime" SG_ 571 CCmHuTempWhlStatusDrvr 50;
BA_ "GenSigSendType" SG_ 571 CCmHuAirConCompSwitchStatus 7;
BA_ "GenSigCycleTimeActive" SG_ 571 CCmHuAirConCompSwitchStatus 50;
BA_ "GenSigCycleTime" SG_ 571 CCmHuAirConCompSwitchStatus 50;
BA_ "GenSigSendType" SG_ 571 CCmHuCtrlPnlStatus 7;
BA_ "GenSigCycleTimeActive" SG_ 571 CCmHuCtrlPnlStatus 50;
BA_ "GenSigCycleTime" SG_ 571 CCmHuCtrlPnlStatus 50;
BA_ "GenSigSendType" SG_ 571 CCmHuChangeBit 7;
BA_ "GenSigCycleTimeActive" SG_ 571 CCmHuChangeBit 50;
BA_ "GenSigCycleTime" SG_ 571 CCmHuChangeBit 50;
BA_ "GenSigSendType" SG_ 571 CCmHuUserInterventionStatusFlag 7;
BA_ "GenSigCycleTimeActive" SG_ 571 CCmHuUserInterventionStatusFlag 50;
BA_ "GenSigCycleTime" SG_ 571 CCmHuUserInterventionStatusFlag 50;
BA_ "GenSigSendType" SG_ 571 CCmHuTempWhlStatusStatus 7;
BA_ "GenSigCycleTimeActive" SG_ 571 CCmHuTempWhlStatusStatus 50;
BA_ "GenSigCycleTime" SG_ 571 CCmHuTempWhlStatusStatus 50;
BA_ "GenSigSendType" SG_ 571 CCmHuErrStatus 7;
BA_ "GenSigCycleTimeActive" SG_ 571 CCmHuErrStatus 50;
BA_ "GenSigCycleTime" SG_ 571 CCmHuErrStatus 50;
BA_ "GenSigSendType" SG_ 571 CCmHuDualModeSwStatusStatus 7;
BA_ "GenSigCycleTimeActive" SG_ 571 CCmHuDualModeSwStatusStatus 50;
BA_ "GenSigCycleTime" SG_ 571 CCmHuDualModeSwStatusStatus 50;
BA_ "GenSigSendType" SG_ 571 CCmHuTempWhlStatusPassStatus 7;
BA_ "GenSigCycleTimeActive" SG_ 571 CCmHuTempWhlStatusPassStatus 50;
BA_ "GenSigCycleTime" SG_ 571 CCmHuTempWhlStatusPassStatus 50;
BA_ "GenSigSendType" SG_ 571 CCmHuTempWhlStatusDrvrStatus 7;
BA_ "GenSigCycleTimeActive" SG_ 571 CCmHuTempWhlStatusDrvrStatus 50;
BA_ "GenSigCycleTime" SG_ 571 CCmHuTempWhlStatusDrvrStatus 50;
BA_ "Remarks" SG_ 573 LockStateESCL "*";
BA_ "GenSigSendType" SG_ 573 LockStateESCL 7;
BA_ "GenSigCycleTimeActive" SG_ 573 LockStateESCL 50;
BA_ "GenSigCycleTime" SG_ 573 LockStateESCL 50;
BA_ "Remarks" SG_ 573 UnlockStateESCL "*";
BA_ "GenSigSendType" SG_ 573 UnlockStateESCL 7;
BA_ "GenSigCycleTimeActive" SG_ 573 UnlockStateESCL 50;
BA_ "GenSigCycleTime" SG_ 573 UnlockStateESCL 50;
BA_ "GenSigSendType" SG_ 651 EPAsStatusGen2 7;
BA_ "GenSigCycleTimeActive" SG_ 651 EPAsStatusGen2 100;
BA_ "GenSigCycleTime" SG_ 651 EPAsStatusGen2 100;
BA_ "GenSigSendType" SG_ 651 SAsAngEPAS 7;
BA_ "GenSigCycleTimeActive" SG_ 651 SAsAngEPAS 100;
BA_ "GenSigCycleTime" SG_ 651 SAsAngEPAS 100;
BA_ "GenSigSendType" SG_ 651 SAsAngEPAsDir 7;
BA_ "GenSigCycleTimeActive" SG_ 651 SAsAngEPAsDir 100;
BA_ "GenSigCycleTime" SG_ 651 SAsAngEPAsDir 100;
BA_ "GenSigStartValue" SG_ 651 SAsAngEPASStatus 2;
BA_ "GenSigSendType" SG_ 651 SAsAngEPASStatus 7;
BA_ "GenSigCycleTimeActive" SG_ 651 SAsAngEPASStatus 100;
BA_ "GenSigCycleTime" SG_ 651 SAsAngEPASStatus 100;
BA_ "GenSigSendType" SG_ 656 StuckModeAvailability 7;
BA_ "GenSigCycleTimeActive" SG_ 656 StuckModeAvailability 100;
BA_ "GenSigCycleTime" SG_ 656 StuckModeAvailability 100;
BA_ "GenSigSendType" SG_ 656 StuckModeStateStatus 7;
BA_ "GenSigCycleTimeActive" SG_ 656 StuckModeStateStatus 100;
BA_ "GenSigCycleTime" SG_ 656 StuckModeStateStatus 100;
BA_ "GenSigSendType" SG_ 656 StuckModeState 7;
BA_ "GenSigCycleTimeActive" SG_ 656 StuckModeState 100;
BA_ "GenSigCycleTime" SG_ 656 StuckModeState 100;
BA_ "GenSigSendType" SG_ 656 WSsPulseCountRearRH 7;
BA_ "GenSigCycleTimeActive" SG_ 656 WSsPulseCountRearRH 100;
BA_ "GenSigCycleTime" SG_ 656 WSsPulseCountRearRH 100;
BA_ "GenSigSendType" SG_ 656 WSsPulseCountRearLH 7;
BA_ "GenSigCycleTimeActive" SG_ 656 WSsPulseCountRearLH 100;
BA_ "GenSigCycleTime" SG_ 656 WSsPulseCountRearLH 100;
BA_ "GenSigSendType" SG_ 656 WSsPulseCountFrontRH 7;
BA_ "GenSigCycleTimeActive" SG_ 656 WSsPulseCountFrontRH 100;
BA_ "GenSigCycleTime" SG_ 656 WSsPulseCountFrontRH 100;
BA_ "GenSigSendType" SG_ 656 WSsPulseCountFrontLH 7;
BA_ "GenSigCycleTimeActive" SG_ 656 WSsPulseCountFrontLH 100;
BA_ "GenSigCycleTime" SG_ 656 WSsPulseCountFrontLH 100;
BA_ "GenSigSendType" SG_ 656 WSsPulseCountFrontRHStatus 7;
BA_ "GenSigCycleTimeActive" SG_ 656 WSsPulseCountFrontRHStatus 100;
BA_ "GenSigCycleTime" SG_ 656 WSsPulseCountFrontRHStatus 100;
BA_ "GenSigSendType" SG_ 656 WSsPulseCountRearLHStatus 7;
BA_ "GenSigCycleTimeActive" SG_ 656 WSsPulseCountRearLHStatus 100;
BA_ "GenSigCycleTime" SG_ 656 WSsPulseCountRearLHStatus 100;
BA_ "GenSigSendType" SG_ 656 WSsPulseCountRearRHStatus 7;
BA_ "GenSigCycleTimeActive" SG_ 656 WSsPulseCountRearRHStatus 100;
BA_ "GenSigCycleTime" SG_ 656 WSsPulseCountRearRHStatus 100;
BA_ "GenSigSendType" SG_ 656 WSsPulseCountFrontLHStatus 7;
BA_ "GenSigCycleTimeActive" SG_ 656 WSsPulseCountFrontLHStatus 100;
BA_ "GenSigCycleTime" SG_ 656 WSsPulseCountFrontLHStatus 100;
BA_ "GenSigSendType" SG_ 656 DrvModeIndctnESPStatusNew 7;
BA_ "GenSigCycleTimeActive" SG_ 656 DrvModeIndctnESPStatusNew 100;
BA_ "GenSigCycleTime" SG_ 656 DrvModeIndctnESPStatusNew 100;
BA_ "GenSigSendType" SG_ 656 DrvModeIndctnESPNew 7;
BA_ "GenSigCycleTimeActive" SG_ 656 DrvModeIndctnESPNew 100;
BA_ "GenSigCycleTime" SG_ 656 DrvModeIndctnESPNew 100;
BA_ "GenSigStartValue" SG_ 693 OATICSig 130;
BA_ "GenSigSendType" SG_ 693 OATICSig 7;
BA_ "GenSigCycleTimeActive" SG_ 693 OATICSig 100;
BA_ "GenSigCycleTime" SG_ 693 OATICSig 100;
BA_ "GenSigSendType" SG_ 693 BattVoltIPC 7;
BA_ "GenSigCycleTimeActive" SG_ 693 BattVoltIPC 100;
BA_ "GenSigCycleTime" SG_ 693 BattVoltIPC 100;
BA_ "GenSigStartValue" SG_ 693 ParkBrkState 1;
BA_ "GenSigSendType" SG_ 693 ParkBrkState 7;
BA_ "GenSigCycleTimeActive" SG_ 693 ParkBrkState 100;
BA_ "GenSigCycleTime" SG_ 693 ParkBrkState 100;
BA_ "GenSigSendType" SG_ 693 IcPlatformVariant 7;
BA_ "GenSigCycleTimeActive" SG_ 693 IcPlatformVariant 100;
BA_ "GenSigCycleTime" SG_ 693 IcPlatformVariant 100;
BA_ "GenSigStartValue" SG_ 693 OATICSigStatus 2;
BA_ "GenSigSendType" SG_ 693 OATICSigStatus 7;
BA_ "GenSigCycleTimeActive" SG_ 693 OATICSigStatus 100;
BA_ "GenSigCycleTime" SG_ 693 OATICSigStatus 100;
BA_ "GenSigSendType" SG_ 693 IcPresence 7;
BA_ "GenSigCycleTimeActive" SG_ 693 IcPresence 100;
BA_ "GenSigCycleTime" SG_ 693 IcPresence 100;
BA_ "GenSigSendType" SG_ 693 SRSWarningLampStatus 7;
BA_ "GenSigCycleTimeActive" SG_ 693 SRSWarningLampStatus 100;
BA_ "GenSigCycleTime" SG_ 693 SRSWarningLampStatus 100;
BA_ "GenSigSendType" SG_ 693 VsSPulseCountSigStatus 7;
BA_ "GenSigCycleTimeActive" SG_ 693 VsSPulseCountSigStatus 100;
BA_ "GenSigCycleTime" SG_ 693 VsSPulseCountSigStatus 100;
BA_ "GenSigSendType" SG_ 693 VsSPulseCountSig 7;
BA_ "GenSigCycleTimeActive" SG_ 693 VsSPulseCountSig 100;
BA_ "GenSigCycleTime" SG_ 693 VsSPulseCountSig 100;
BA_ "GenSigSendType" SG_ 693 IcHuVoiceAlertState 7;
BA_ "GenSigCycleTimeActive" SG_ 693 IcHuVoiceAlertState 100;
BA_ "GenSigCycleTime" SG_ 693 IcHuVoiceAlertState 100;
BA_ "GenSigSendType" SG_ 693 IcHuVoiceAlertStateStatus 7;
BA_ "GenSigCycleTimeActive" SG_ 693 IcHuVoiceAlertStateStatus 100;
BA_ "GenSigCycleTime" SG_ 693 IcHuVoiceAlertStateStatus 100;
BA_ "GenSigSendType" SG_ 693 ICCurDriveModeSig 7;
BA_ "GenSigCycleTimeActive" SG_ 693 ICCurDriveModeSig 100;
BA_ "GenSigCycleTime" SG_ 693 ICCurDriveModeSig 100;
BA_ "GenSigSendType" SG_ 693 IcHuCarImageSelection 7;
BA_ "GenSigCycleTimeActive" SG_ 693 IcHuCarImageSelection 100;
BA_ "GenSigCycleTime" SG_ 693 IcHuCarImageSelection 100;
BA_ "GenSigSendType" SG_ 693 IcSbDispReq 7;
BA_ "GenSigCycleTimeActive" SG_ 693 IcSbDispReq 100;
BA_ "GenSigCycleTime" SG_ 693 IcSbDispReq 100;
BA_ "GenSigSendType" SG_ 693 IcSbrDrvrSeatBeltSwitchStatus 7;
BA_ "GenSigCycleTimeActive" SG_ 693 IcSbrDrvrSeatBeltSwitchStatus 100;
BA_ "GenSigCycleTime" SG_ 693 IcSbrDrvrSeatBeltSwitchStatus 100;
BA_ "GenSigSendType" SG_ 695 IcHuDTeInfoStatus 7;
BA_ "GenSigCycleTimeActive" SG_ 695 IcHuDTeInfoStatus 100;
BA_ "GenSigCycleTime" SG_ 695 IcHuDTeInfoStatus 100;
BA_ "GenSigSendType" SG_ 695 IcHuTripAInfo 7;
BA_ "GenSigCycleTimeActive" SG_ 695 IcHuTripAInfo 100;
BA_ "GenSigCycleTime" SG_ 695 IcHuTripAInfo 100;
BA_ "GenSigSendType" SG_ 695 IcHuDrvrSeatBeltInfo 7;
BA_ "GenSigCycleTimeActive" SG_ 695 IcHuDrvrSeatBeltInfo 100;
BA_ "GenSigCycleTime" SG_ 695 IcHuDrvrSeatBeltInfo 100;
BA_ "GenSigSendType" SG_ 695 IcHuTripBInfo 7;
BA_ "GenSigCycleTimeActive" SG_ 695 IcHuTripBInfo 100;
BA_ "GenSigCycleTime" SG_ 695 IcHuTripBInfo 100;
BA_ "GenSigSendType" SG_ 695 IcHuDTeInfo 7;
BA_ "GenSigCycleTimeActive" SG_ 695 IcHuDTeInfo 100;
BA_ "GenSigCycleTime" SG_ 695 IcHuDTeInfo 100;
BA_ "GenSigSendType" SG_ 695 IcHuVehRegion 7;
BA_ "GenSigCycleTimeActive" SG_ 695 IcHuVehRegion 100;
BA_ "GenSigCycleTime" SG_ 695 IcHuVehRegion 100;
BA_ "GenSigSendType" SG_ 695 IcHuTyreSize 7;
BA_ "GenSigCycleTimeActive" SG_ 695 IcHuTyreSize 100;
BA_ "GenSigCycleTime" SG_ 695 IcHuTyreSize 100;
BA_ "GenSigSendType" SG_ 697 IcHuResetTripB 7;
BA_ "GenSigCycleTimeActive" SG_ 697 IcHuResetTripB 100;
BA_ "GenSigCycleTime" SG_ 697 IcHuResetTripB 100;
BA_ "GenSigSendType" SG_ 697 IcHuResetTripA 7;
BA_ "GenSigCycleTimeActive" SG_ 697 IcHuResetTripA 100;
BA_ "GenSigCycleTime" SG_ 697 IcHuResetTripA 100;
BA_ "GenSigStartValue" SG_ 697 IcHuDriveType 1;
BA_ "GenSigSendType" SG_ 697 IcHuDriveType 7;
BA_ "GenSigCycleTimeActive" SG_ 697 IcHuDriveType 100;
BA_ "GenSigCycleTime" SG_ 697 IcHuDriveType 100;
BA_ "GenSigSendType" SG_ 698 IllumDimLvlSetting 7;
BA_ "GenSigCycleTimeActive" SG_ 698 IllumDimLvlSetting 100;
BA_ "GenSigCycleTime" SG_ 698 IllumDimLvlSetting 100;
BA_ "GenSigSendType" SG_ 698 IllumDimLvlSettingStatus 7;
BA_ "GenSigCycleTimeActive" SG_ 698 IllumDimLvlSettingStatus 100;
BA_ "GenSigCycleTime" SG_ 698 IllumDimLvlSettingStatus 100;
BA_ "GenSigSendType" SG_ 698 SwitchDimmingControlIPC 7;
BA_ "GenSigCycleTimeActive" SG_ 698 SwitchDimmingControlIPC 100;
BA_ "GenSigCycleTime" SG_ 698 SwitchDimmingControlIPC 100;
BA_ "GenSigSendType" SG_ 698 IllumOnOffCtrlStatus 7;
BA_ "GenSigCycleTimeActive" SG_ 698 IllumOnOffCtrlStatus 100;
BA_ "GenSigCycleTime" SG_ 698 IllumOnOffCtrlStatus 100;
BA_ "GenSigSendType" SG_ 698 IllumOnOffCtrl 7;
BA_ "GenSigCycleTimeActive" SG_ 698 IllumOnOffCtrl 100;
BA_ "GenSigCycleTime" SG_ 698 IllumOnOffCtrl 100;
BA_ "GenSigSendType" SG_ 698 SwitchDimmingControlIPCStatus 7;
BA_ "GenSigCycleTimeActive" SG_ 698 SwitchDimmingControlIPCStatus 100;
BA_ "GenSigCycleTime" SG_ 698 SwitchDimmingControlIPCStatus 100;
BA_ "GenSigSendType" SG_ 700 IPCRemoteCheckStatus 7;
BA_ "GenSigCycleTimeActive" SG_ 700 IPCRemoteCheckStatus 100;
BA_ "GenSigCycleTime" SG_ 700 IPCRemoteCheckStatus 100;
BA_ "GenSigSendType" SG_ 700 IPCRemoteCheck 7;
BA_ "GenSigCycleTimeActive" SG_ 700 IPCRemoteCheck 100;
BA_ "GenSigCycleTime" SG_ 700 IPCRemoteCheck 100;
BA_ "GenSigStartValue" SG_ 700 NextServDueAlertStatus 2;
BA_ "GenSigSendType" SG_ 700 NextServDueAlertStatus 7;
BA_ "GenSigCycleTimeActive" SG_ 700 NextServDueAlertStatus 100;
BA_ "GenSigCycleTime" SG_ 700 NextServDueAlertStatus 100;
BA_ "GenSigSendType" SG_ 700 NextServDueAlert 7;
BA_ "GenSigCycleTimeActive" SG_ 700 NextServDueAlert 100;
BA_ "GenSigCycleTime" SG_ 700 NextServDueAlert 100;
BA_ "GenSigSendType" SG_ 700 IcHuServReminderDays 7;
BA_ "GenSigCycleTimeActive" SG_ 700 IcHuServReminderDays 100;
BA_ "GenSigCycleTime" SG_ 700 IcHuServReminderDays 100;
BA_ "GenSigSendType" SG_ 700 IcHuServReminderKm 7;
BA_ "GenSigCycleTimeActive" SG_ 700 IcHuServReminderKm 100;
BA_ "GenSigCycleTime" SG_ 700 IcHuServReminderKm 100;
BA_ "GenSigSendType" SG_ 700 IcHuIceState 7;
BA_ "GenSigCycleTimeActive" SG_ 700 IcHuIceState 100;
BA_ "GenSigCycleTime" SG_ 700 IcHuIceState 100;
BA_ "GenSigSendType" SG_ 700 IcHuBrakeFluidLowState 7;
BA_ "GenSigCycleTimeActive" SG_ 700 IcHuBrakeFluidLowState 100;
BA_ "GenSigCycleTime" SG_ 700 IcHuBrakeFluidLowState 100;
BA_ "GenSigSendType" SG_ 700 IcHuFastenSeatBeltState 7;
BA_ "GenSigCycleTimeActive" SG_ 700 IcHuFastenSeatBeltState 100;
BA_ "GenSigCycleTime" SG_ 700 IcHuFastenSeatBeltState 100;
BA_ "GenSigSendType" SG_ 700 IcHuBatteryChargingState 7;
BA_ "GenSigCycleTimeActive" SG_ 700 IcHuBatteryChargingState 100;
BA_ "GenSigCycleTime" SG_ 700 IcHuBatteryChargingState 100;
BA_ "GenSigSendType" SG_ 700 IcHuServReminderDaysfull 7;
BA_ "GenSigCycleTimeActive" SG_ 700 IcHuServReminderDaysfull 100;
BA_ "GenSigCycleTime" SG_ 700 IcHuServReminderDaysfull 100;
BA_ "GenSigSendType" SG_ 702 IcHuOnBoardCompState 7;
BA_ "GenSigCycleTimeActive" SG_ 702 IcHuOnBoardCompState 100;
BA_ "GenSigCycleTime" SG_ 702 IcHuOnBoardCompState 100;
BA_ "GenSigSendType" SG_ 702 IcHuIcInfoFeaturePresenceAck 7;
BA_ "GenSigCycleTimeActive" SG_ 702 IcHuIcInfoFeaturePresenceAck 100;
BA_ "GenSigCycleTime" SG_ 702 IcHuIcInfoFeaturePresenceAck 100;
BA_ "GenSigSendType" SG_ 702 IcHuAlertStateStatus 7;
BA_ "GenSigCycleTimeActive" SG_ 702 IcHuAlertStateStatus 100;
BA_ "GenSigCycleTime" SG_ 702 IcHuAlertStateStatus 100;
BA_ "GenSigSendType" SG_ 702 IcHuAlertType 7;
BA_ "GenSigCycleTimeActive" SG_ 702 IcHuAlertType 100;
BA_ "GenSigCycleTime" SG_ 702 IcHuAlertType 100;
BA_ "GenSigSendType" SG_ 702 DriveAlert1_TeaBreak 7;
BA_ "GenSigCycleTimeActive" SG_ 702 DriveAlert1_TeaBreak 100;
BA_ "GenSigCycleTime" SG_ 702 DriveAlert1_TeaBreak 100;
BA_ "GenSigSendType" SG_ 702 IcHuAlertState 7;
BA_ "GenSigCycleTimeActive" SG_ 702 IcHuAlertState 100;
BA_ "GenSigCycleTime" SG_ 702 IcHuAlertState 100;
BA_ "GenSigSendType" SG_ 704 HuIcSourceNew 7;
BA_ "GenSigCycleTimeActive" SG_ 704 HuIcSourceNew 100;
BA_ "GenSigCycleTime" SG_ 704 HuIcSourceNew 100;
BA_ "GenSigSendType" SG_ 704 GpsCompassPresence 7;
BA_ "GenSigCycleTimeActive" SG_ 704 GpsCompassPresence 100;
BA_ "GenSigCycleTime" SG_ 704 GpsCompassPresence 100;
BA_ "GenSigSendType" SG_ 704 GPsCourseInfoIVI 7;
BA_ "GenSigCycleTimeActive" SG_ 704 GPsCourseInfoIVI 100;
BA_ "GenSigCycleTime" SG_ 704 GPsCourseInfoIVI 100;
BA_ "GenSigSendType" SG_ 704 GPsCourseInfoStatusIVI 7;
BA_ "GenSigCycleTimeActive" SG_ 704 GPsCourseInfoStatusIVI 100;
BA_ "GenSigCycleTime" SG_ 704 GPsCourseInfoStatusIVI 100;
BA_ "GenSigSendType" SG_ 704 StuckModeUserResponse 7;
BA_ "GenSigCycleTimeActive" SG_ 704 StuckModeUserResponse 100;
BA_ "GenSigCycleTime" SG_ 704 StuckModeUserResponse 100;
BA_ "GenSigSendType" SG_ 704 HuIcDistanceDisplayUnitEnum 7;
BA_ "GenSigCycleTimeActive" SG_ 704 HuIcDistanceDisplayUnitEnum 100;
BA_ "GenSigCycleTime" SG_ 704 HuIcDistanceDisplayUnitEnum 100;
BA_ "GenSigSendType" SG_ 704 HuPresence 7;
BA_ "GenSigCycleTimeActive" SG_ 704 HuPresence 100;
BA_ "GenSigCycleTime" SG_ 704 HuPresence 100;
BA_ "GenSigSendType" SG_ 704 HuPlatformVariant 7;
BA_ "GenSigCycleTimeActive" SG_ 704 HuPlatformVariant 100;
BA_ "GenSigCycleTime" SG_ 704 HuPlatformVariant 100;
BA_ "GenSigSendType" SG_ 704 BattVolt_HU 7;
BA_ "GenSigCycleTimeActive" SG_ 704 BattVolt_HU 100;
BA_ "GenSigCycleTime" SG_ 704 BattVolt_HU 100;
BA_ "GenSigSendType" SG_ 704 SbIcDispState 7;
BA_ "GenSigCycleTimeActive" SG_ 704 SbIcDispState 100;
BA_ "GenSigCycleTime" SG_ 704 SbIcDispState 100;
BA_ "GenSigSendType" SG_ 704 HuIcAlertStatusAck 7;
BA_ "GenSigCycleTimeActive" SG_ 704 HuIcAlertStatusAck 100;
BA_ "GenSigCycleTime" SG_ 704 HuIcAlertStatusAck 100;
BA_ "GenSigSendType" SG_ 704 HuIcAlertStateAck 7;
BA_ "GenSigCycleTimeActive" SG_ 704 HuIcAlertStateAck 100;
BA_ "GenSigCycleTime" SG_ 704 HuIcAlertStateAck 100;
BA_ "GenSigSendType" SG_ 706 HuIcNaviSource 7;
BA_ "GenSigCycleTimeActive" SG_ 706 HuIcNaviSource 100;
BA_ "GenSigCycleTime" SG_ 706 HuIcNaviSource 100;
BA_ "GenSigSendType" SG_ 706 HuIcCarPlayManeuverType 7;
BA_ "GenSigCycleTimeActive" SG_ 706 HuIcCarPlayManeuverType 100;
BA_ "GenSigCycleTime" SG_ 706 HuIcCarPlayManeuverType 100;
BA_ "GenSigSendType" SG_ 706 HuIcNextTurnDistance 7;
BA_ "GenSigCycleTimeActive" SG_ 706 HuIcNextTurnDistance 100;
BA_ "GenSigCycleTime" SG_ 706 HuIcNextTurnDistance 100;
BA_ "GenSigSendType" SG_ 706 HuIcNextTurnEstimateSec 7;
BA_ "GenSigCycleTimeActive" SG_ 706 HuIcNextTurnEstimateSec 100;
BA_ "GenSigCycleTime" SG_ 706 HuIcNextTurnEstimateSec 100;
BA_ "GenSigSendType" SG_ 706 HuIcNextTurnRoundDist 7;
BA_ "GenSigCycleTimeActive" SG_ 706 HuIcNextTurnRoundDist 100;
BA_ "GenSigCycleTime" SG_ 706 HuIcNextTurnRoundDist 100;
BA_ "GenSigSendType" SG_ 706 HuIcNextTurnEstimateMin 7;
BA_ "GenSigCycleTimeActive" SG_ 706 HuIcNextTurnEstimateMin 100;
BA_ "GenSigCycleTime" SG_ 706 HuIcNextTurnEstimateMin 100;
BA_ "GenSigSendType" SG_ 706 HuIcNextTurnSideEnum 7;
BA_ "GenSigCycleTimeActive" SG_ 706 HuIcNextTurnSideEnum 100;
BA_ "GenSigCycleTime" SG_ 706 HuIcNextTurnSideEnum 100;
BA_ "GenSigSendType" SG_ 706 HuIcNextTurnEstimateHrs 7;
BA_ "GenSigCycleTimeActive" SG_ 706 HuIcNextTurnEstimateHrs 100;
BA_ "GenSigCycleTime" SG_ 706 HuIcNextTurnEstimateHrs 100;
BA_ "GenSigSendType" SG_ 706 HuIcNextTurnRoundDistUnits 7;
BA_ "GenSigCycleTimeActive" SG_ 706 HuIcNextTurnRoundDistUnits 100;
BA_ "GenSigCycleTime" SG_ 706 HuIcNextTurnRoundDistUnits 100;
BA_ "GenSigSendType" SG_ 706 HuIcNaviStatus 7;
BA_ "GenSigCycleTimeActive" SG_ 706 HuIcNaviStatus 100;
BA_ "GenSigCycleTime" SG_ 706 HuIcNaviStatus 100;
BA_ "GenSigSendType" SG_ 706 HuIcNextTurnSide 7;
BA_ "GenSigCycleTimeActive" SG_ 706 HuIcNextTurnSide 100;
BA_ "GenSigCycleTime" SG_ 706 HuIcNextTurnSide 100;
BA_ "GenSigSendType" SG_ 706 HuIcRoundAboutType 7;
BA_ "GenSigCycleTimeActive" SG_ 706 HuIcRoundAboutType 100;
BA_ "GenSigCycleTime" SG_ 706 HuIcRoundAboutType 100;
BA_ "GenSigSendType" SG_ 706 HuIcColorStatus 7;
BA_ "GenSigCycleTimeActive" SG_ 706 HuIcColorStatus 100;
BA_ "GenSigCycleTime" SG_ 706 HuIcColorStatus 100;
BA_ "GenSigSendType" SG_ 707 HuIcNextTurnRoundDistUnitsNew 7;
BA_ "GenSigCycleTimeActive" SG_ 707 HuIcNextTurnRoundDistUnitsNew 100;
BA_ "GenSigCycleTime" SG_ 707 HuIcNextTurnRoundDistUnitsNew 100;
BA_ "GenSigSendType" SG_ 707 HuIcNextTurnDistanceNew 7;
BA_ "GenSigCycleTimeActive" SG_ 707 HuIcNextTurnDistanceNew 100;
BA_ "GenSigCycleTime" SG_ 707 HuIcNextTurnDistanceNew 100;
BA_ "GenSigSendType" SG_ 707 LinSwcSbPowerModeCan 7;
BA_ "GenSigCycleTimeActive" SG_ 707 LinSwcSbPowerModeCan 100;
BA_ "GenSigCycleTime" SG_ 707 LinSwcSbPowerModeCan 100;
BA_ "GenSigSendType" SG_ 707 LinSwcIcKey9Can 7;
BA_ "GenSigCycleTimeActive" SG_ 707 LinSwcIcKey9Can 100;
BA_ "GenSigCycleTime" SG_ 707 LinSwcIcKey9Can 100;
BA_ "GenSigSendType" SG_ 707 LinSwcIcKey8Can 7;
BA_ "GenSigCycleTimeActive" SG_ 707 LinSwcIcKey8Can 100;
BA_ "GenSigCycleTime" SG_ 707 LinSwcIcKey8Can 100;
BA_ "GenSigSendType" SG_ 707 LinSwcIcKey7Can 7;
BA_ "GenSigCycleTimeActive" SG_ 707 LinSwcIcKey7Can 100;
BA_ "GenSigCycleTime" SG_ 707 LinSwcIcKey7Can 100;
BA_ "GenSigSendType" SG_ 707 LinSwcIcKey6Can 7;
BA_ "GenSigCycleTimeActive" SG_ 707 LinSwcIcKey6Can 100;
BA_ "GenSigCycleTime" SG_ 707 LinSwcIcKey6Can 100;
BA_ "GenSigSendType" SG_ 707 LinSwcIcViewCan 7;
BA_ "GenSigCycleTimeActive" SG_ 707 LinSwcIcViewCan 100;
BA_ "GenSigCycleTime" SG_ 707 LinSwcIcViewCan 100;
BA_ "GenSigSendType" SG_ 707 LinSwcIcMenuSelectCan 7;
BA_ "GenSigCycleTimeActive" SG_ 707 LinSwcIcMenuSelectCan 100;
BA_ "GenSigCycleTime" SG_ 707 LinSwcIcMenuSelectCan 100;
BA_ "GenSigSendType" SG_ 707 LinSwcIcMenuDownCan 7;
BA_ "GenSigCycleTimeActive" SG_ 707 LinSwcIcMenuDownCan 100;
BA_ "GenSigCycleTime" SG_ 707 LinSwcIcMenuDownCan 100;
BA_ "GenSigSendType" SG_ 707 LinSwcIcMenuUpCan 7;
BA_ "GenSigCycleTimeActive" SG_ 707 LinSwcIcMenuUpCan 100;
BA_ "GenSigCycleTime" SG_ 707 LinSwcIcMenuUpCan 100;
BA_ "GenSigSendType" SG_ 707 LinSwcIcpaginationCan 7;
BA_ "GenSigCycleTimeActive" SG_ 707 LinSwcIcpaginationCan 100;
BA_ "GenSigCycleTime" SG_ 707 LinSwcIcpaginationCan 100;
BA_ "GenSigSendType" SG_ 707 LinSwcPresenceCanStatus 7;
BA_ "GenSigCycleTimeActive" SG_ 707 LinSwcPresenceCanStatus 100;
BA_ "GenSigCycleTime" SG_ 707 LinSwcPresenceCanStatus 100;
BA_ "GenSigSendType" SG_ 707 LinSwcIcVariant 7;
BA_ "GenSigCycleTimeActive" SG_ 707 LinSwcIcVariant 100;
BA_ "GenSigCycleTime" SG_ 707 LinSwcIcVariant 100;
BA_ "GenSigSendType" SG_ 707 LinSwcPresenceCan 7;
BA_ "GenSigCycleTimeActive" SG_ 707 LinSwcPresenceCan 100;
BA_ "GenSigCycleTime" SG_ 707 LinSwcPresenceCan 100;
BA_ "GenSigSendType" SG_ 707 HuIcVoiceAlertStatusAck 7;
BA_ "GenSigCycleTimeActive" SG_ 707 HuIcVoiceAlertStatusAck 100;
BA_ "GenSigCycleTime" SG_ 707 HuIcVoiceAlertStatusAck 100;
BA_ "GenSigSendType" SG_ 707 HuIcVoiceAlertStateAck 7;
BA_ "GenSigCycleTimeActive" SG_ 707 HuIcVoiceAlertStateAck 100;
BA_ "GenSigCycleTime" SG_ 707 HuIcVoiceAlertStateAck 100;
BA_ "GenSigSendType" SG_ 710 PDcHuFaultState 7;
BA_ "GenSigCycleTimeActive" SG_ 710 PDcHuFaultState 100;
BA_ "GenSigCycleTime" SG_ 710 PDcHuFaultState 100;
BA_ "GenSigSendType" SG_ 710 PDcHuAudioZoneState 7;
BA_ "GenSigCycleTimeActive" SG_ 710 PDcHuAudioZoneState 100;
BA_ "GenSigCycleTime" SG_ 710 PDcHuAudioZoneState 100;
BA_ "GenSigSendType" SG_ 710 PDcHuVisualZoneRearLHSensState 7;
BA_ "GenSigCycleTimeActive" SG_ 710 PDcHuVisualZoneRearLHSensState 100;
BA_ "GenSigCycleTime" SG_ 710 PDcHuVisualZoneRearLHSensState 100;
BA_ "GenSigSendType" SG_ 710 PDcHuVisualZoneRearMidRHSensStat 7;
BA_ "GenSigCycleTimeActive" SG_ 710 PDcHuVisualZoneRearMidRHSensStat 100;
BA_ "GenSigCycleTime" SG_ 710 PDcHuVisualZoneRearMidRHSensStat 100;
BA_ "SystemSignalLongSymbol" SG_ 710 PDcHuVisualZoneRearMidRHSensStat "PDcHuVisualZoneRearMidRHSensState";
BA_ "GenSigSendType" SG_ 710 PDcHuVisualZoneRearRHSensState 7;
BA_ "GenSigCycleTimeActive" SG_ 710 PDcHuVisualZoneRearRHSensState 100;
BA_ "GenSigCycleTime" SG_ 710 PDcHuVisualZoneRearRHSensState 100;
BA_ "GenSigSendType" SG_ 710 PDcHuVisualZoneRearMidLHSensStat 7;
BA_ "GenSigCycleTimeActive" SG_ 710 PDcHuVisualZoneRearMidLHSensStat 100;
BA_ "GenSigCycleTime" SG_ 710 PDcHuVisualZoneRearMidLHSensStat 100;
BA_ "SystemSignalLongSymbol" SG_ 710 PDcHuVisualZoneRearMidLHSensStat "PDcHuVisualZoneRearMidLHSensState";
BA_ "GenSigSendType" SG_ 710 PDcPresence 7;
BA_ "GenSigCycleTimeActive" SG_ 710 PDcPresence 100;
BA_ "GenSigCycleTime" SG_ 710 PDcPresence 100;
BA_ "GenSigSendType" SG_ 710 PDcHuState 7;
BA_ "GenSigCycleTimeActive" SG_ 710 PDcHuState 100;
BA_ "GenSigCycleTime" SG_ 710 PDcHuState 100;
BA_ "GenSigSendType" SG_ 710 PDcHuPwrModeState 7;
BA_ "GenSigCycleTimeActive" SG_ 710 PDcHuPwrModeState 100;
BA_ "GenSigCycleTime" SG_ 710 PDcHuPwrModeState 100;
BA_ "GenSigSendType" SG_ 710 PDcVariant 7;
BA_ "GenSigCycleTimeActive" SG_ 710 PDcVariant 100;
BA_ "GenSigCycleTime" SG_ 710 PDcVariant 100;
BA_ "GenSigSendType" SG_ 710 PDcHuVisualZoneFrontLHSensState 7;
BA_ "GenSigCycleTimeActive" SG_ 710 PDcHuVisualZoneFrontLHSensState 100;
BA_ "GenSigCycleTime" SG_ 710 PDcHuVisualZoneFrontLHSensState 100;
BA_ "GenSigSendType" SG_ 710 PDcHuVisualZoneFrontMidLHSensSta 7;
BA_ "GenSigCycleTimeActive" SG_ 710 PDcHuVisualZoneFrontMidLHSensSta 100;
BA_ "GenSigCycleTime" SG_ 710 PDcHuVisualZoneFrontMidLHSensSta 100;
BA_ "SystemSignalLongSymbol" SG_ 710 PDcHuVisualZoneFrontMidLHSensSta "PDcHuVisualZoneFrontMidLHSensState";
BA_ "GenSigSendType" SG_ 710 PDcHuVisualZoneFrontMidRHSensSta 7;
BA_ "GenSigCycleTimeActive" SG_ 710 PDcHuVisualZoneFrontMidRHSensSta 100;
BA_ "GenSigCycleTime" SG_ 710 PDcHuVisualZoneFrontMidRHSensSta 100;
BA_ "SystemSignalLongSymbol" SG_ 710 PDcHuVisualZoneFrontMidRHSensSta "PDcHuVisualZoneFrontMidRHSensState";
BA_ "GenSigSendType" SG_ 710 PDcHuVisualZoneFrontRHSensState 7;
BA_ "GenSigCycleTimeActive" SG_ 710 PDcHuVisualZoneFrontRHSensState 100;
BA_ "GenSigCycleTime" SG_ 710 PDcHuVisualZoneFrontRHSensState 100;
BA_ "GenSigSendType" SG_ 710 PDcHuFrontAudioZoneState 7;
BA_ "GenSigCycleTimeActive" SG_ 710 PDcHuFrontAudioZoneState 100;
BA_ "GenSigCycleTime" SG_ 710 PDcHuFrontAudioZoneState 100;
BA_ "GenSigSendType" SG_ 710 PDcHuFrontFaultState 7;
BA_ "GenSigCycleTimeActive" SG_ 710 PDcHuFrontFaultState 100;
BA_ "GenSigCycleTime" SG_ 710 PDcHuFrontFaultState 100;
BA_ "GenSigSendType" SG_ 710 PDcHuFrontState 7;
BA_ "GenSigCycleTimeActive" SG_ 710 PDcHuFrontState 100;
BA_ "GenSigCycleTime" SG_ 710 PDcHuFrontState 100;
BA_ "GenSigSendType" SG_ 710 PDcIPcFrontActive 7;
BA_ "GenSigCycleTimeActive" SG_ 710 PDcIPcFrontActive 100;
BA_ "GenSigCycleTime" SG_ 710 PDcIPcFrontActive 100;
BA_ "GenSigSendType" SG_ 710 PDcIPcRearActive 7;
BA_ "GenSigCycleTimeActive" SG_ 710 PDcIPcRearActive 100;
BA_ "GenSigCycleTime" SG_ 710 PDcIPcRearActive 100;
BA_ "GenSigStartValue" SG_ 711 PDcHuProxFrontLHSensState 255;
BA_ "GenSigSendType" SG_ 711 PDcHuProxFrontLHSensState 7;
BA_ "GenSigCycleTimeActive" SG_ 711 PDcHuProxFrontLHSensState 100;
BA_ "GenSigCycleTime" SG_ 711 PDcHuProxFrontLHSensState 100;
BA_ "GenSigStartValue" SG_ 711 PDcHuProxFrontRHSensState 255;
BA_ "GenSigSendType" SG_ 711 PDcHuProxFrontRHSensState 7;
BA_ "GenSigCycleTimeActive" SG_ 711 PDcHuProxFrontRHSensState 100;
BA_ "GenSigCycleTime" SG_ 711 PDcHuProxFrontRHSensState 100;
BA_ "GenSigStartValue" SG_ 711 PDcHuProxFrontMidLHSensState 255;
BA_ "GenSigSendType" SG_ 711 PDcHuProxFrontMidLHSensState 7;
BA_ "GenSigCycleTimeActive" SG_ 711 PDcHuProxFrontMidLHSensState 100;
BA_ "GenSigCycleTime" SG_ 711 PDcHuProxFrontMidLHSensState 100;
BA_ "GenSigStartValue" SG_ 711 PDcHuProxFrontMidRHSensState 255;
BA_ "GenSigSendType" SG_ 711 PDcHuProxFrontMidRHSensState 7;
BA_ "GenSigCycleTimeActive" SG_ 711 PDcHuProxFrontMidRHSensState 100;
BA_ "GenSigCycleTime" SG_ 711 PDcHuProxFrontMidRHSensState 100;
BA_ "GenSigSendType" SG_ 711 PDcHuProxFrontRHSensStateStatus 7;
BA_ "GenSigCycleTimeActive" SG_ 711 PDcHuProxFrontRHSensStateStatus 100;
BA_ "GenSigCycleTime" SG_ 711 PDcHuProxFrontRHSensStateStatus 100;
BA_ "GenSigSendType" SG_ 711 PDcHuProxFrontMidRHSensStateStat 7;
BA_ "GenSigCycleTimeActive" SG_ 711 PDcHuProxFrontMidRHSensStateStat 100;
BA_ "GenSigCycleTime" SG_ 711 PDcHuProxFrontMidRHSensStateStat 100;
BA_ "SystemSignalLongSymbol" SG_ 711 PDcHuProxFrontMidRHSensStateStat "PDcHuProxFrontMidRHSensStateStatus";
BA_ "GenSigSendType" SG_ 711 PDcHuProxFrontMidLHSensStateStat 7;
BA_ "GenSigCycleTimeActive" SG_ 711 PDcHuProxFrontMidLHSensStateStat 100;
BA_ "GenSigCycleTime" SG_ 711 PDcHuProxFrontMidLHSensStateStat 100;
BA_ "SystemSignalLongSymbol" SG_ 711 PDcHuProxFrontMidLHSensStateStat "PDcHuProxFrontMidLHSensStateStatus";
BA_ "GenSigSendType" SG_ 711 PDcHuProxFrontLHSensStateStatus 7;
BA_ "GenSigCycleTimeActive" SG_ 711 PDcHuProxFrontLHSensStateStatus 100;
BA_ "GenSigCycleTime" SG_ 711 PDcHuProxFrontLHSensStateStatus 100;
BA_ "GenSigStartValue" SG_ 712 PDcHuProxRearLHSensState 255;
BA_ "GenSigSendType" SG_ 712 PDcHuProxRearLHSensState 7;
BA_ "GenSigCycleTimeActive" SG_ 712 PDcHuProxRearLHSensState 100;
BA_ "GenSigCycleTime" SG_ 712 PDcHuProxRearLHSensState 100;
BA_ "GenSigStartValue" SG_ 712 PDcHuProxRearRHSensState 255;
BA_ "GenSigSendType" SG_ 712 PDcHuProxRearRHSensState 7;
BA_ "GenSigCycleTimeActive" SG_ 712 PDcHuProxRearRHSensState 100;
BA_ "GenSigCycleTime" SG_ 712 PDcHuProxRearRHSensState 100;
BA_ "GenSigStartValue" SG_ 712 PDcHuProxRearMidLHSensState 255;
BA_ "GenSigSendType" SG_ 712 PDcHuProxRearMidLHSensState 7;
BA_ "GenSigCycleTimeActive" SG_ 712 PDcHuProxRearMidLHSensState 100;
BA_ "GenSigCycleTime" SG_ 712 PDcHuProxRearMidLHSensState 100;
BA_ "GenSigStartValue" SG_ 712 PDcHuProxRearMidRHSensState 255;
BA_ "GenSigSendType" SG_ 712 PDcHuProxRearMidRHSensState 7;
BA_ "GenSigCycleTimeActive" SG_ 712 PDcHuProxRearMidRHSensState 100;
BA_ "GenSigCycleTime" SG_ 712 PDcHuProxRearMidRHSensState 100;
BA_ "GenSigSendType" SG_ 712 PDcHuProxRearRHSensStateStatus 7;
BA_ "GenSigCycleTimeActive" SG_ 712 PDcHuProxRearRHSensStateStatus 100;
BA_ "GenSigCycleTime" SG_ 712 PDcHuProxRearRHSensStateStatus 100;
BA_ "GenSigSendType" SG_ 712 PDcHuProxRearMidRHSensStateStatu 7;
BA_ "GenSigCycleTimeActive" SG_ 712 PDcHuProxRearMidRHSensStateStatu 100;
BA_ "GenSigCycleTime" SG_ 712 PDcHuProxRearMidRHSensStateStatu 100;
BA_ "SystemSignalLongSymbol" SG_ 712 PDcHuProxRearMidRHSensStateStatu "PDcHuProxRearMidRHSensStateStatus";
BA_ "GenSigSendType" SG_ 712 PDcHuProxRearMidLHSensStateStatu 7;
BA_ "GenSigCycleTimeActive" SG_ 712 PDcHuProxRearMidLHSensStateStatu 100;
BA_ "GenSigCycleTime" SG_ 712 PDcHuProxRearMidLHSensStateStatu 100;
BA_ "SystemSignalLongSymbol" SG_ 712 PDcHuProxRearMidLHSensStateStatu "PDcHuProxRearMidLHSensStateStatus";
BA_ "GenSigSendType" SG_ 712 PDcHuProxRearLHSensStateStatus 7;
BA_ "GenSigCycleTimeActive" SG_ 712 PDcHuProxRearLHSensStateStatus 100;
BA_ "GenSigCycleTime" SG_ 712 PDcHuProxRearLHSensStateStatus 100;
BA_ "GenSigSendType" SG_ 713 HuIcMediaState 7;
BA_ "GenSigCycleTimeActive" SG_ 713 HuIcMediaState 100;
BA_ "GenSigCycleTime" SG_ 713 HuIcMediaState 100;
BA_ "GenSigSendType" SG_ 713 HuIcSource 7;
BA_ "GenSigCycleTimeActive" SG_ 713 HuIcSource 100;
BA_ "GenSigCycleTime" SG_ 713 HuIcSource 100;
BA_ "GenSigSendType" SG_ 713 HuIcAudioVolumeStatus 7;
BA_ "GenSigCycleTimeActive" SG_ 713 HuIcAudioVolumeStatus 100;
BA_ "GenSigCycleTime" SG_ 713 HuIcAudioVolumeStatus 100;
BA_ "GenSigSendType" SG_ 713 HuIcBTStatus 7;
BA_ "GenSigCycleTimeActive" SG_ 713 HuIcBTStatus 100;
BA_ "GenSigCycleTime" SG_ 713 HuIcBTStatus 100;
BA_ "GenSigSendType" SG_ 713 HuIcPlabackCallDurationSec 7;
BA_ "GenSigCycleTimeActive" SG_ 713 HuIcPlabackCallDurationSec 100;
BA_ "GenSigCycleTime" SG_ 713 HuIcPlabackCallDurationSec 100;
BA_ "GenSigSendType" SG_ 713 HuIcRepeatOneState 7;
BA_ "GenSigCycleTimeActive" SG_ 713 HuIcRepeatOneState 100;
BA_ "GenSigCycleTime" SG_ 713 HuIcRepeatOneState 100;
BA_ "GenSigSendType" SG_ 713 HuIcMuteStatus 7;
BA_ "GenSigCycleTimeActive" SG_ 713 HuIcMuteStatus 100;
BA_ "GenSigCycleTime" SG_ 713 HuIcMuteStatus 100;
BA_ "GenSigSendType" SG_ 713 HuIcPlabackCallDurationMin 7;
BA_ "GenSigCycleTimeActive" SG_ 713 HuIcPlabackCallDurationMin 100;
BA_ "GenSigCycleTime" SG_ 713 HuIcPlabackCallDurationMin 100;
BA_ "GenSigSendType" SG_ 713 HuIcSMSReceiveState 7;
BA_ "GenSigCycleTimeActive" SG_ 713 HuIcSMSReceiveState 100;
BA_ "GenSigCycleTime" SG_ 713 HuIcSMSReceiveState 100;
BA_ "GenSigSendType" SG_ 713 HuIcRepeatState 7;
BA_ "GenSigCycleTimeActive" SG_ 713 HuIcRepeatState 100;
BA_ "GenSigCycleTime" SG_ 713 HuIcRepeatState 100;
BA_ "GenSigSendType" SG_ 713 HuIcPlabackCallDurationHrs 7;
BA_ "GenSigCycleTimeActive" SG_ 713 HuIcPlabackCallDurationHrs 100;
BA_ "GenSigCycleTime" SG_ 713 HuIcPlabackCallDurationHrs 100;
BA_ "GenSigSendType" SG_ 713 HuIcPhoneCallStatus 7;
BA_ "GenSigCycleTimeActive" SG_ 713 HuIcPhoneCallStatus 100;
BA_ "GenSigCycleTime" SG_ 713 HuIcPhoneCallStatus 100;
BA_ "GenSigSendType" SG_ 713 HuIcPlaybackElapsedTimeHrs 7;
BA_ "GenSigCycleTimeActive" SG_ 713 HuIcPlaybackElapsedTimeHrs 100;
BA_ "GenSigCycleTime" SG_ 713 HuIcPlaybackElapsedTimeHrs 100;
BA_ "GenSigSendType" SG_ 713 HuIcNetworkSignalStatus 7;
BA_ "GenSigCycleTimeActive" SG_ 713 HuIcNetworkSignalStatus 100;
BA_ "GenSigCycleTime" SG_ 713 HuIcNetworkSignalStatus 100;
BA_ "GenSigSendType" SG_ 713 HuIcPlaybackElapsedTimeMin 7;
BA_ "GenSigCycleTimeActive" SG_ 713 HuIcPlaybackElapsedTimeMin 100;
BA_ "GenSigCycleTime" SG_ 713 HuIcPlaybackElapsedTimeMin 100;
BA_ "GenSigSendType" SG_ 713 HuIcInfoFeaturePresence 7;
BA_ "GenSigCycleTimeActive" SG_ 713 HuIcInfoFeaturePresence 100;
BA_ "GenSigCycleTime" SG_ 713 HuIcInfoFeaturePresence 100;
BA_ "GenSigSendType" SG_ 713 HuIcShuffleState 7;
BA_ "GenSigCycleTimeActive" SG_ 713 HuIcShuffleState 100;
BA_ "GenSigCycleTime" SG_ 713 HuIcShuffleState 100;
BA_ "GenSigSendType" SG_ 713 HuIcPlaybackElapsedTimeSec 7;
BA_ "GenSigCycleTimeActive" SG_ 713 HuIcPlaybackElapsedTimeSec 100;
BA_ "GenSigCycleTime" SG_ 713 HuIcPlaybackElapsedTimeSec 100;
BA_ "GenSigSendType" SG_ 715 CcmHuRearBlwrSwitchState 7;
BA_ "GenSigCycleTimeActive" SG_ 715 CcmHuRearBlwrSwitchState 100;
BA_ "GenSigCycleTime" SG_ 715 CcmHuRearBlwrSwitchState 100;
BA_ "GenSigSendType" SG_ 715 RemoteAcStatus 7;
BA_ "GenSigCycleTimeActive" SG_ 715 RemoteAcStatus 100;
BA_ "GenSigCycleTime" SG_ 715 RemoteAcStatus 100;
BA_ "GenSigSendType" SG_ 715 RemoteAcState 7;
BA_ "GenSigCycleTimeActive" SG_ 715 RemoteAcState 100;
BA_ "GenSigCycleTime" SG_ 715 RemoteAcState 100;
BA_ "GenSigStartValue" SG_ 715 VehicleInteriorTemp 130;
BA_ "GenSigSendType" SG_ 715 VehicleInteriorTemp 7;
BA_ "GenSigCycleTimeActive" SG_ 715 VehicleInteriorTemp 100;
BA_ "GenSigCycleTime" SG_ 715 VehicleInteriorTemp 100;
BA_ "GenSigSendType" SG_ 715 CCmVariantType 7;
BA_ "GenSigCycleTimeActive" SG_ 715 CCmVariantType 100;
BA_ "GenSigCycleTime" SG_ 715 CCmVariantType 100;
BA_ "GenSigSendType" SG_ 715 CCmPresence 7;
BA_ "GenSigCycleTimeActive" SG_ 715 CCmPresence 100;
BA_ "GenSigCycleTime" SG_ 715 CCmPresence 100;
BA_ "GenSigSendType" SG_ 715 VehicleInteriorTempStatus 7;
BA_ "GenSigCycleTimeActive" SG_ 715 VehicleInteriorTempStatus 100;
BA_ "GenSigCycleTime" SG_ 715 VehicleInteriorTempStatus 100;
BA_ "GenSigSendType" SG_ 720 TurnRHTelltaleStatus 7;
BA_ "GenSigCycleTimeActive" SG_ 720 TurnRHTelltaleStatus 100;
BA_ "GenSigCycleTime" SG_ 720 TurnRHTelltaleStatus 100;
BA_ "GenSigSendType" SG_ 720 TurnRHTelltale 7;
BA_ "GenSigCycleTimeActive" SG_ 720 TurnRHTelltale 100;
BA_ "GenSigCycleTime" SG_ 720 TurnRHTelltale 100;
BA_ "GenSigSendType" SG_ 720 TurnLHTelltaleStatus 7;
BA_ "GenSigCycleTimeActive" SG_ 720 TurnLHTelltaleStatus 100;
BA_ "GenSigCycleTime" SG_ 720 TurnLHTelltaleStatus 100;
BA_ "GenSigSendType" SG_ 720 TurnLHTelltale 7;
BA_ "GenSigCycleTimeActive" SG_ 720 TurnLHTelltale 100;
BA_ "GenSigCycleTime" SG_ 720 TurnLHTelltale 100;
BA_ "GenSigSendType" SG_ 720 PositionLmpTelltaleStatus 7;
BA_ "GenSigCycleTimeActive" SG_ 720 PositionLmpTelltaleStatus 100;
BA_ "GenSigCycleTime" SG_ 720 PositionLmpTelltaleStatus 100;
BA_ "GenSigSendType" SG_ 720 PositionLmpTelltale 7;
BA_ "GenSigCycleTimeActive" SG_ 720 PositionLmpTelltale 100;
BA_ "GenSigCycleTime" SG_ 720 PositionLmpTelltale 100;
BA_ "GenSigSendType" SG_ 720 BCMVariant 7;
BA_ "GenSigCycleTimeActive" SG_ 720 BCMVariant 100;
BA_ "GenSigCycleTime" SG_ 720 BCMVariant 100;
BA_ "GenSigSendType" SG_ 720 BCMPresence 7;
BA_ "GenSigCycleTimeActive" SG_ 720 BCMPresence 100;
BA_ "GenSigCycleTime" SG_ 720 BCMPresence 100;
BA_ "GenSigSendType" SG_ 720 RevGearStatus 7;
BA_ "GenSigCycleTimeActive" SG_ 720 RevGearStatus 100;
BA_ "GenSigCycleTime" SG_ 720 RevGearStatus 100;
BA_ "GenSigSendType" SG_ 720 RevGear 7;
BA_ "GenSigCycleTimeActive" SG_ 720 RevGear 100;
BA_ "GenSigCycleTime" SG_ 720 RevGear 100;
BA_ "GenSigSendType" SG_ 720 LightSensActiveStatus 7;
BA_ "GenSigCycleTimeActive" SG_ 720 LightSensActiveStatus 100;
BA_ "GenSigCycleTime" SG_ 720 LightSensActiveStatus 100;
BA_ "GenSigSendType" SG_ 720 LightSensActive 7;
BA_ "GenSigCycleTimeActive" SG_ 720 LightSensActive 100;
BA_ "GenSigCycleTime" SG_ 720 LightSensActive 100;
BA_ "GenSigSendType" SG_ 720 RVcPresence 7;
BA_ "GenSigCycleTimeActive" SG_ 720 RVcPresence 100;
BA_ "GenSigCycleTime" SG_ 720 RVcPresence 100;
BA_ "GenSigCycleTime" SG_ 722 PowerModeStateMsgCnt 100;
BA_ "GenSigCycleTimeActive" SG_ 722 PowerModeStateMsgCnt 100;
BA_ "GenSigSendType" SG_ 722 PowerModeStateMsgCnt 7;
BA_ "GenSigCycleTime" SG_ 722 PowerModeStateCRC 100;
BA_ "GenSigCycleTimeActive" SG_ 722 PowerModeStateCRC 100;
BA_ "GenSigSendType" SG_ 722 PowerModeStateCRC 7;
BA_ "GenSigSendType" SG_ 722 PowerModeStateStatus 7;
BA_ "GenSigCycleTimeActive" SG_ 722 PowerModeStateStatus 100;
BA_ "GenSigCycleTime" SG_ 722 PowerModeStateStatus 100;
BA_ "GenSigStartValue" SG_ 722 PowerModeState 1;
BA_ "GenSigSendType" SG_ 722 PowerModeState 7;
BA_ "GenSigCycleTimeActive" SG_ 722 PowerModeState 100;
BA_ "GenSigCycleTime" SG_ 722 PowerModeState 100;
BA_ "GenSigSendType" SG_ 722 PositionLmpTelltaleStatus 7;
BA_ "GenSigCycleTimeActive" SG_ 722 PositionLmpTelltaleStatus 100;
BA_ "GenSigCycleTime" SG_ 722 PositionLmpTelltaleStatus 100;
BA_ "GenSigSendType" SG_ 722 PositionLmpTelltale 7;
BA_ "GenSigCycleTimeActive" SG_ 722 PositionLmpTelltale 100;
BA_ "GenSigCycleTime" SG_ 722 PositionLmpTelltale 100;
BA_ "GenSigSendType" SG_ 722 TurnRHTelltale 7;
BA_ "GenSigCycleTimeActive" SG_ 722 TurnRHTelltale 100;
BA_ "GenSigCycleTime" SG_ 722 TurnRHTelltale 100;
BA_ "GenSigSendType" SG_ 722 TurnLHTelltaleStatus 7;
BA_ "GenSigCycleTimeActive" SG_ 722 TurnLHTelltaleStatus 100;
BA_ "GenSigCycleTime" SG_ 722 TurnLHTelltaleStatus 100;
BA_ "GenSigSendType" SG_ 722 TurnLHTelltale 7;
BA_ "GenSigCycleTimeActive" SG_ 722 TurnLHTelltale 100;
BA_ "GenSigCycleTime" SG_ 722 TurnLHTelltale 100;
BA_ "GenSigSendType" SG_ 722 TurnRHTelltaleStatus 7;
BA_ "GenSigCycleTimeActive" SG_ 722 TurnRHTelltaleStatus 100;
BA_ "GenSigCycleTime" SG_ 722 TurnRHTelltaleStatus 100;
BA_ "GenSigSendType" SG_ 722 BattSaverFnONStatus 7;
BA_ "GenSigCycleTimeActive" SG_ 722 BattSaverFnONStatus 100;
BA_ "GenSigCycleTime" SG_ 722 BattSaverFnONStatus 100;
BA_ "GenSigSendType" SG_ 722 BattSaverFnON 7;
BA_ "GenSigCycleTimeActive" SG_ 722 BattSaverFnON 100;
BA_ "GenSigCycleTime" SG_ 722 BattSaverFnON 100;
BA_ "GenSigStartValue" SG_ 722 CockpitSigECuStatus 2;
BA_ "GenSigSendType" SG_ 722 CockpitSigECuStatus 7;
BA_ "GenSigCycleTimeActive" SG_ 722 CockpitSigECuStatus 100;
BA_ "GenSigCycleTime" SG_ 722 CockpitSigECuStatus 100;
BA_ "GenSigSendType" SG_ 722 CockpitSigECu 7;
BA_ "GenSigCycleTimeActive" SG_ 722 CockpitSigECu 100;
BA_ "GenSigCycleTime" SG_ 722 CockpitSigECu 100;
BA_ "GenSigSendType" SG_ 722 VehicleLockStateStatus 7;
BA_ "GenSigCycleTimeActive" SG_ 722 VehicleLockStateStatus 100;
BA_ "GenSigCycleTime" SG_ 722 VehicleLockStateStatus 100;
BA_ "GenSigSendType" SG_ 722 HighBeamTelltaleStatus 7;
BA_ "GenSigCycleTimeActive" SG_ 722 HighBeamTelltaleStatus 100;
BA_ "GenSigCycleTime" SG_ 722 HighBeamTelltaleStatus 100;
BA_ "GenSigSendType" SG_ 722 HighBeamTelltale 7;
BA_ "GenSigCycleTimeActive" SG_ 722 HighBeamTelltale 100;
BA_ "GenSigCycleTime" SG_ 722 HighBeamTelltale 100;
BA_ "GenSigStartValue" SG_ 722 VehicleLockState 3;
BA_ "GenSigSendType" SG_ 722 VehicleLockState 7;
BA_ "GenSigInactiveValue" SG_ 722 VehicleLockState 3;
BA_ "GenSigCycleTimeActive" SG_ 722 VehicleLockState 100;
BA_ "GenSigCycleTime" SG_ 722 VehicleLockState 100;
BA_ "GenSigSendType" SG_ 729 VehicleMobilizationStateStatus 7;
BA_ "GenSigCycleTimeActive" SG_ 729 VehicleMobilizationStateStatus 100;
BA_ "GenSigCycleTime" SG_ 729 VehicleMobilizationStateStatus 100;
BA_ "GenSigStartValue" SG_ 729 VehicleMobilizationState 1;
BA_ "GenSigSendType" SG_ 729 VehicleMobilizationState 7;
BA_ "GenSigCycleTimeActive" SG_ 729 VehicleMobilizationState 100;
BA_ "GenSigCycleTime" SG_ 729 VehicleMobilizationState 100;
BA_ "GenSigCycleTime" SG_ 729 PEPsClampStateMRC 100;
BA_ "GenSigCycleTimeActive" SG_ 729 PEPsClampStateMRC 100;
BA_ "GenSigSendType" SG_ 729 PEPsClampStateMRC 7;
BA_ "GenSigCycleTime" SG_ 729 PEPsClampStateCRC 100;
BA_ "GenSigCycleTimeActive" SG_ 729 PEPsClampStateCRC 100;
BA_ "GenSigSendType" SG_ 729 PEPsClampStateCRC 7;
BA_ "GenSigSendType" SG_ 729 PepsHuMrrProximityUnfoldSelState 7;
BA_ "GenSigCycleTimeActive" SG_ 729 PepsHuMrrProximityUnfoldSelState 100;
BA_ "GenSigCycleTime" SG_ 729 PepsHuMrrProximityUnfoldSelState 100;
BA_ "GenSigSendType" SG_ 729 PepsHuMrrProximityUnfoldFuncStat 7;
BA_ "GenSigCycleTimeActive" SG_ 729 PepsHuMrrProximityUnfoldFuncStat 100;
BA_ "GenSigCycleTime" SG_ 729 PepsHuMrrProximityUnfoldFuncStat 100;
BA_ "SystemSignalLongSymbol" SG_ 729 PepsHuMrrProximityUnfoldFuncStat "PepsHuMrrProximityUnfoldFuncState";
BA_ "GenSigStartValue" SG_ 729 PEPsClampState 1;
BA_ "GenSigSendType" SG_ 729 PEPsClampState 7;
BA_ "GenSigCycleTimeActive" SG_ 729 PEPsClampState 100;
BA_ "GenSigCycleTime" SG_ 729 PEPsClampState 100;
BA_ "GenSigSendType" SG_ 729 PEPsClampStateStatus 7;
BA_ "GenSigCycleTimeActive" SG_ 729 PEPsClampStateStatus 100;
BA_ "GenSigCycleTime" SG_ 729 PEPsClampStateStatus 100;
BA_ "GenSigSendType" SG_ 729 PEPsPresence 7;
BA_ "GenSigCycleTimeActive" SG_ 729 PEPsPresence 100;
BA_ "GenSigCycleTime" SG_ 729 PEPsPresence 100;
BA_ "GenSigSendType" SG_ 729 PEPsKeyInState 7;
BA_ "GenSigCycleTimeActive" SG_ 729 PEPsKeyInState 100;
BA_ "GenSigCycleTime" SG_ 729 PEPsKeyInState 100;
BA_ "GenSigSendType" SG_ 732 TpmsTireSensorConfig 7;
BA_ "GenSigCycleTimeActive" SG_ 732 TpmsTireSensorConfig 100;
BA_ "GenSigCycleTime" SG_ 732 TpmsTireSensorConfig 100;
BA_ "GenSigSendType" SG_ 732 TPMSPresence 7;
BA_ "GenSigCycleTimeActive" SG_ 732 TPMSPresence 100;
BA_ "GenSigCycleTime" SG_ 732 TPMSPresence 100;
BA_ "GenSigSendType" SG_ 732 LowTirePresAlertSpare 7;
BA_ "GenSigCycleTimeActive" SG_ 732 LowTirePresAlertSpare 100;
BA_ "GenSigCycleTime" SG_ 732 LowTirePresAlertSpare 100;
BA_ "GenSigSendType" SG_ 732 LowTirePresAlertRL 7;
BA_ "GenSigCycleTimeActive" SG_ 732 LowTirePresAlertRL 100;
BA_ "GenSigCycleTime" SG_ 732 LowTirePresAlertRL 100;
BA_ "GenSigSendType" SG_ 732 LowTirePresAlertRR 7;
BA_ "GenSigCycleTimeActive" SG_ 732 LowTirePresAlertRR 100;
BA_ "GenSigCycleTime" SG_ 732 LowTirePresAlertRR 100;
BA_ "GenSigSendType" SG_ 732 LowTirePresAlertFR 7;
BA_ "GenSigCycleTimeActive" SG_ 732 LowTirePresAlertFR 100;
BA_ "GenSigCycleTime" SG_ 732 LowTirePresAlertFR 100;
BA_ "GenSigSendType" SG_ 732 LowTirePresAlertFL 7;
BA_ "GenSigCycleTimeActive" SG_ 732 LowTirePresAlertFL 100;
BA_ "GenSigCycleTime" SG_ 732 LowTirePresAlertFL 100;
BA_ "GenSigSendType" SG_ 732 HighTirePresAlertSpare 7;
BA_ "GenSigCycleTimeActive" SG_ 732 HighTirePresAlertSpare 100;
BA_ "GenSigCycleTime" SG_ 732 HighTirePresAlertSpare 100;
BA_ "GenSigSendType" SG_ 732 HighTirePresAlertRL 7;
BA_ "GenSigCycleTimeActive" SG_ 732 HighTirePresAlertRL 100;
BA_ "GenSigCycleTime" SG_ 732 HighTirePresAlertRL 100;
BA_ "GenSigSendType" SG_ 732 HighTirePresAlertRR 7;
BA_ "GenSigCycleTimeActive" SG_ 732 HighTirePresAlertRR 100;
BA_ "GenSigCycleTime" SG_ 732 HighTirePresAlertRR 100;
BA_ "GenSigSendType" SG_ 732 HighTirePresAlertFR 7;
BA_ "GenSigCycleTimeActive" SG_ 732 HighTirePresAlertFR 100;
BA_ "GenSigCycleTime" SG_ 732 HighTirePresAlertFR 100;
BA_ "GenSigSendType" SG_ 732 HighTirePresAlertFL 7;
BA_ "GenSigCycleTimeActive" SG_ 732 HighTirePresAlertFL 100;
BA_ "GenSigCycleTime" SG_ 732 HighTirePresAlertFL 100;
BA_ "GenSigSendType" SG_ 732 HighTireTempAlertSpare 7;
BA_ "GenSigCycleTimeActive" SG_ 732 HighTireTempAlertSpare 100;
BA_ "GenSigCycleTime" SG_ 732 HighTireTempAlertSpare 100;
BA_ "GenSigSendType" SG_ 732 HighTireTempAlertRL 7;
BA_ "GenSigCycleTimeActive" SG_ 732 HighTireTempAlertRL 100;
BA_ "GenSigCycleTime" SG_ 732 HighTireTempAlertRL 100;
BA_ "GenSigSendType" SG_ 732 HighTireTempAlertRR 7;
BA_ "GenSigCycleTimeActive" SG_ 732 HighTireTempAlertRR 100;
BA_ "GenSigCycleTime" SG_ 732 HighTireTempAlertRR 100;
BA_ "GenSigSendType" SG_ 732 HighTireTempAlertFR 7;
BA_ "GenSigCycleTimeActive" SG_ 732 HighTireTempAlertFR 100;
BA_ "GenSigCycleTime" SG_ 732 HighTireTempAlertFR 100;
BA_ "GenSigSendType" SG_ 732 HighTireTempAlertFL 7;
BA_ "GenSigCycleTimeActive" SG_ 732 HighTireTempAlertFL 100;
BA_ "GenSigCycleTime" SG_ 732 HighTireTempAlertFL 100;
BA_ "GenSigSendType" SG_ 732 PresLeakageAlertSpare 7;
BA_ "GenSigCycleTimeActive" SG_ 732 PresLeakageAlertSpare 100;
BA_ "GenSigCycleTime" SG_ 732 PresLeakageAlertSpare 100;
BA_ "GenSigSendType" SG_ 732 PresLeakageAlertRL 7;
BA_ "GenSigCycleTimeActive" SG_ 732 PresLeakageAlertRL 100;
BA_ "GenSigCycleTime" SG_ 732 PresLeakageAlertRL 100;
BA_ "GenSigSendType" SG_ 732 PresLeakageAlertRR 7;
BA_ "GenSigCycleTimeActive" SG_ 732 PresLeakageAlertRR 100;
BA_ "GenSigCycleTime" SG_ 732 PresLeakageAlertRR 100;
BA_ "GenSigSendType" SG_ 732 PresLeakageAlertFR 7;
BA_ "GenSigCycleTimeActive" SG_ 732 PresLeakageAlertFR 100;
BA_ "GenSigCycleTime" SG_ 732 PresLeakageAlertFR 100;
BA_ "GenSigSendType" SG_ 732 PresLeakageAlertFL 7;
BA_ "GenSigCycleTimeActive" SG_ 732 PresLeakageAlertFL 100;
BA_ "GenSigCycleTime" SG_ 732 PresLeakageAlertFL 100;
BA_ "GenSigSendType" SG_ 732 TpmsAlertStatus 7;
BA_ "GenSigCycleTimeActive" SG_ 732 TpmsAlertStatus 100;
BA_ "GenSigCycleTime" SG_ 732 TpmsAlertStatus 100;
BA_ "GenSigSendType" SG_ 732 TpmsReceiverRXFault 7;
BA_ "GenSigCycleTimeActive" SG_ 732 TpmsReceiverRXFault 100;
BA_ "GenSigCycleTime" SG_ 732 TpmsReceiverRXFault 100;
BA_ "GenSigSendType" SG_ 732 SensorMalfncFaultSpare 7;
BA_ "GenSigCycleTimeActive" SG_ 732 SensorMalfncFaultSpare 100;
BA_ "GenSigCycleTime" SG_ 732 SensorMalfncFaultSpare 100;
BA_ "GenSigSendType" SG_ 732 SensorMalfncFaultRL 7;
BA_ "GenSigCycleTimeActive" SG_ 732 SensorMalfncFaultRL 100;
BA_ "GenSigCycleTime" SG_ 732 SensorMalfncFaultRL 100;
BA_ "GenSigSendType" SG_ 732 SensorMalfncFaultRR 7;
BA_ "GenSigCycleTimeActive" SG_ 732 SensorMalfncFaultRR 100;
BA_ "GenSigCycleTime" SG_ 732 SensorMalfncFaultRR 100;
BA_ "GenSigSendType" SG_ 732 SensorMalfncFaultFR 7;
BA_ "GenSigCycleTimeActive" SG_ 732 SensorMalfncFaultFR 100;
BA_ "GenSigCycleTime" SG_ 732 SensorMalfncFaultFR 100;
BA_ "GenSigSendType" SG_ 732 SensorMalfncFaultFL 7;
BA_ "GenSigCycleTimeActive" SG_ 732 SensorMalfncFaultFL 100;
BA_ "GenSigCycleTime" SG_ 732 SensorMalfncFaultFL 100;
BA_ "GenSigSendType" SG_ 732 TpmsFaultStatus 7;
BA_ "GenSigCycleTimeActive" SG_ 732 TpmsFaultStatus 100;
BA_ "GenSigCycleTime" SG_ 732 TpmsFaultStatus 100;
BA_ "GenSigSendType" SG_ 732 TpmsNotLearntFault 7;
BA_ "GenSigCycleTimeActive" SG_ 732 TpmsNotLearntFault 100;
BA_ "GenSigCycleTime" SG_ 732 TpmsNotLearntFault 100;
BA_ "GenSigSendType" SG_ 732 SensorMissingFaultRL 7;
BA_ "GenSigCycleTimeActive" SG_ 732 SensorMissingFaultRL 100;
BA_ "GenSigCycleTime" SG_ 732 SensorMissingFaultRL 100;
BA_ "GenSigSendType" SG_ 732 SensorMissingFaultRR 7;
BA_ "GenSigCycleTimeActive" SG_ 732 SensorMissingFaultRR 100;
BA_ "GenSigCycleTime" SG_ 732 SensorMissingFaultRR 100;
BA_ "GenSigSendType" SG_ 732 SensorMissingFaultFR 7;
BA_ "GenSigCycleTimeActive" SG_ 732 SensorMissingFaultFR 100;
BA_ "GenSigCycleTime" SG_ 732 SensorMissingFaultFR 100;
BA_ "GenSigSendType" SG_ 732 SensorMissingFaultFL 7;
BA_ "GenSigCycleTimeActive" SG_ 732 SensorMissingFaultFL 100;
BA_ "GenSigCycleTime" SG_ 732 SensorMissingFaultFL 100;
BA_ "GenSigSendType" SG_ 732 TpmsLearnStatus 7;
BA_ "GenSigCycleTimeActive" SG_ 732 TpmsLearnStatus 100;
BA_ "GenSigCycleTime" SG_ 732 TpmsLearnStatus 100;
BA_ "GenSigSendType" SG_ 732 SpareTireSwapFlagRL 7;
BA_ "GenSigCycleTimeActive" SG_ 732 SpareTireSwapFlagRL 100;
BA_ "GenSigCycleTime" SG_ 732 SpareTireSwapFlagRL 100;
BA_ "GenSigSendType" SG_ 732 SpareTireSwapFlagRR 7;
BA_ "GenSigCycleTimeActive" SG_ 732 SpareTireSwapFlagRR 100;
BA_ "GenSigCycleTime" SG_ 732 SpareTireSwapFlagRR 100;
BA_ "GenSigSendType" SG_ 732 SpareTireSwapFlagFR 7;
BA_ "GenSigCycleTimeActive" SG_ 732 SpareTireSwapFlagFR 100;
BA_ "GenSigCycleTime" SG_ 732 SpareTireSwapFlagFR 100;
BA_ "GenSigSendType" SG_ 732 SpareTireSwapFlagFL 7;
BA_ "GenSigCycleTimeActive" SG_ 732 SpareTireSwapFlagFL 100;
BA_ "GenSigCycleTime" SG_ 732 SpareTireSwapFlagFL 100;
BA_ "GenSigSendType" SG_ 732 SensorLearningStatus 7;
BA_ "GenSigCycleTimeActive" SG_ 732 SensorLearningStatus 100;
BA_ "GenSigCycleTime" SG_ 732 SensorLearningStatus 100;
BA_ "GenSigSendType" SG_ 732 SensorDetectFlagSpare 7;
BA_ "GenSigCycleTimeActive" SG_ 732 SensorDetectFlagSpare 100;
BA_ "GenSigCycleTime" SG_ 732 SensorDetectFlagSpare 100;
BA_ "GenSigSendType" SG_ 732 SensorDetectFlagRL 7;
BA_ "GenSigCycleTimeActive" SG_ 732 SensorDetectFlagRL 100;
BA_ "GenSigCycleTime" SG_ 732 SensorDetectFlagRL 100;
BA_ "GenSigSendType" SG_ 732 SensorDetectFlagRR 7;
BA_ "GenSigCycleTimeActive" SG_ 732 SensorDetectFlagRR 100;
BA_ "GenSigCycleTime" SG_ 732 SensorDetectFlagRR 100;
BA_ "GenSigSendType" SG_ 732 SensorDetectFlagFR 7;
BA_ "GenSigCycleTimeActive" SG_ 732 SensorDetectFlagFR 100;
BA_ "GenSigCycleTime" SG_ 732 SensorDetectFlagFR 100;
BA_ "GenSigSendType" SG_ 732 SensorDetectFlagFL 7;
BA_ "GenSigCycleTimeActive" SG_ 732 SensorDetectFlagFL 100;
BA_ "GenSigCycleTime" SG_ 732 SensorDetectFlagFL 100;
BA_ "GenSigSendType" SG_ 733 SensorIDnotLearntSpare 7;
BA_ "GenSigCycleTimeActive" SG_ 733 SensorIDnotLearntSpare 100;
BA_ "GenSigCycleTime" SG_ 733 SensorIDnotLearntSpare 100;
BA_ "GenSigSendType" SG_ 733 SensorIDnotLearntRL 7;
BA_ "GenSigCycleTimeActive" SG_ 733 SensorIDnotLearntRL 100;
BA_ "GenSigCycleTime" SG_ 733 SensorIDnotLearntRL 100;
BA_ "GenSigSendType" SG_ 733 SensorIDnotLearntRR 7;
BA_ "GenSigCycleTimeActive" SG_ 733 SensorIDnotLearntRR 100;
BA_ "GenSigCycleTime" SG_ 733 SensorIDnotLearntRR 100;
BA_ "GenSigSendType" SG_ 733 SensorIDnotLearntFR 7;
BA_ "GenSigCycleTimeActive" SG_ 733 SensorIDnotLearntFR 100;
BA_ "GenSigCycleTime" SG_ 733 SensorIDnotLearntFR 100;
BA_ "GenSigSendType" SG_ 733 SensorIDnotLearntFL 7;
BA_ "GenSigCycleTimeActive" SG_ 733 SensorIDnotLearntFL 100;
BA_ "GenSigCycleTime" SG_ 733 SensorIDnotLearntFL 100;
BA_ "GenSigSendType" SG_ 734 TirePressureFL 7;
BA_ "GenSigCycleTimeActive" SG_ 734 TirePressureFL 100;
BA_ "GenSigCycleTime" SG_ 734 TirePressureFL 100;
BA_ "GenSigSendType" SG_ 734 TirePressureFR 7;
BA_ "GenSigCycleTimeActive" SG_ 734 TirePressureFR 100;
BA_ "GenSigCycleTime" SG_ 734 TirePressureFR 100;
BA_ "GenSigSendType" SG_ 734 TirePressureRR 7;
BA_ "GenSigCycleTimeActive" SG_ 734 TirePressureRR 100;
BA_ "GenSigCycleTime" SG_ 734 TirePressureRR 100;
BA_ "GenSigSendType" SG_ 734 TirePressureRL 7;
BA_ "GenSigCycleTimeActive" SG_ 734 TirePressureRL 100;
BA_ "GenSigCycleTime" SG_ 734 TirePressureRL 100;
BA_ "GenSigSendType" SG_ 734 TirePressureSpare 7;
BA_ "GenSigCycleTimeActive" SG_ 734 TirePressureSpare 100;
BA_ "GenSigCycleTime" SG_ 734 TirePressureSpare 100;
BA_ "GenSigStartValue" SG_ 735 TireTemperatureFL 40;
BA_ "GenSigSendType" SG_ 735 TireTemperatureFL 7;
BA_ "GenSigCycleTimeActive" SG_ 735 TireTemperatureFL 100;
BA_ "GenSigCycleTime" SG_ 735 TireTemperatureFL 100;
BA_ "GenSigStartValue" SG_ 735 TireTemperatureFR 40;
BA_ "GenSigSendType" SG_ 735 TireTemperatureFR 7;
BA_ "GenSigCycleTimeActive" SG_ 735 TireTemperatureFR 100;
BA_ "GenSigCycleTime" SG_ 735 TireTemperatureFR 100;
BA_ "GenSigStartValue" SG_ 735 TireTemperatureRR 40;
BA_ "GenSigSendType" SG_ 735 TireTemperatureRR 7;
BA_ "GenSigCycleTimeActive" SG_ 735 TireTemperatureRR 100;
BA_ "GenSigCycleTime" SG_ 735 TireTemperatureRR 100;
BA_ "GenSigStartValue" SG_ 735 TireTemperatureRL 40;
BA_ "GenSigSendType" SG_ 735 TireTemperatureRL 7;
BA_ "GenSigCycleTimeActive" SG_ 735 TireTemperatureRL 100;
BA_ "GenSigCycleTime" SG_ 735 TireTemperatureRL 100;
BA_ "GenSigStartValue" SG_ 735 TireTemperatureSpare 40;
BA_ "GenSigSendType" SG_ 735 TireTemperatureSpare 7;
BA_ "GenSigCycleTimeActive" SG_ 735 TireTemperatureSpare 100;
BA_ "GenSigCycleTime" SG_ 735 TireTemperatureSpare 100;
BA_ "GenSigTimeoutTime_HU_Mid_X451" SG_ 744 HuCCmFanSpdDuringVR 1000;
BA_ "GenSigTimeoutTime_HU_High_X451" SG_ 744 HuCCmFanSpdDuringVR 1000;
BA_ "GenSigTimeoutTime_HU_B" SG_ 744 HuCCmFanSpdDuringVR 1000;
BA_ "GenSigTimeoutTime_HU_A" SG_ 744 HuCCmFanSpdDuringVR 1000;
BA_ "GenSigTimeoutMsg_HU_Mid_X451" SG_ 744 HuCCmFanSpdDuringVR 1000;
BA_ "GenSigTimeoutMsg_HU_High_X451" SG_ 744 HuCCmFanSpdDuringVR 1000;
BA_ "GenSigTimeoutMsg_HU_B" SG_ 744 HuCCmFanSpdDuringVR 1000;
BA_ "GenSigTimeoutMsg_HU_A" SG_ 744 HuCCmFanSpdDuringVR 1000;
BA_ "GenSigSendType" SG_ 744 HuCCmFanSpdDuringVR 7;
BA_ "GenSigCycleTimeActive" SG_ 744 HuCCmFanSpdDuringVR 200;
BA_ "GenSigCycleTime" SG_ 744 HuCCmFanSpdDuringVR 200;
BA_ "GenSigTimeoutMsg_HU_High_X445" SG_ 744 HuCCmFanSpdDuringVR 1000;
BA_ "GenSigTimeoutMsg_HU_Mid_X445" SG_ 744 HuCCmFanSpdDuringVR 1000;
BA_ "GenSigTimeoutTime_HU_High_X445" SG_ 744 HuCCmFanSpdDuringVR 1000;
BA_ "GenSigTimeoutTime_HU_Mid_X445" SG_ 744 HuCCmFanSpdDuringVR 1000;
BA_ "GenSigTimeoutMsg_IVI" SG_ 744 HuCCmFanSpdDuringVR 1000;
BA_ "GenSigTimeoutTime_IVI" SG_ 744 HuCCmFanSpdDuringVR 1000;
BA_ "GenSigTimeoutTime_HU_Mid_X451" SG_ 744 HuCCmVRSession 1000;
BA_ "GenSigTimeoutTime_HU_High_X451" SG_ 744 HuCCmVRSession 1000;
BA_ "GenSigTimeoutTime_HU_B" SG_ 744 HuCCmVRSession 1000;
BA_ "GenSigTimeoutTime_HU_A" SG_ 744 HuCCmVRSession 1000;
BA_ "GenSigTimeoutMsg_HU_Mid_X451" SG_ 744 HuCCmVRSession 1000;
BA_ "GenSigTimeoutMsg_HU_High_X451" SG_ 744 HuCCmVRSession 1000;
BA_ "GenSigTimeoutMsg_HU_B" SG_ 744 HuCCmVRSession 1000;
BA_ "GenSigTimeoutMsg_HU_A" SG_ 744 HuCCmVRSession 1000;
BA_ "GenSigSendType" SG_ 744 HuCCmVRSession 7;
BA_ "GenSigCycleTimeActive" SG_ 744 HuCCmVRSession 200;
BA_ "GenSigCycleTime" SG_ 744 HuCCmVRSession 200;
BA_ "GenSigTimeoutMsg_HU_High_X445" SG_ 744 HuCCmVRSession 1000;
BA_ "GenSigTimeoutMsg_HU_Mid_X445" SG_ 744 HuCCmVRSession 1000;
BA_ "GenSigTimeoutTime_HU_High_X445" SG_ 744 HuCCmVRSession 1000;
BA_ "GenSigTimeoutTime_HU_Mid_X445" SG_ 744 HuCCmVRSession 1000;
BA_ "GenSigTimeoutMsg_IVI" SG_ 744 HuCCmVRSession 1000;
BA_ "GenSigTimeoutTime_IVI" SG_ 744 HuCCmVRSession 1000;
BA_ "GenSigTimeoutTime_HU_Mid_X451" SG_ 928 TripDuration_TripA 2500;
BA_ "GenSigTimeoutTime_HU_High_X451" SG_ 928 TripDuration_TripA 2500;
BA_ "GenSigTimeoutTime_HU_B" SG_ 928 TripDuration_TripA 2500;
BA_ "GenSigTimeoutTime_HU_A" SG_ 928 TripDuration_TripA 2500;
BA_ "GenSigTimeoutMsg_HU_Mid_X451" SG_ 928 TripDuration_TripA 2500;
BA_ "GenSigTimeoutMsg_HU_High_X451" SG_ 928 TripDuration_TripA 2500;
BA_ "GenSigTimeoutMsg_HU_B" SG_ 928 TripDuration_TripA 2500;
BA_ "GenSigTimeoutMsg_HU_A" SG_ 928 TripDuration_TripA 2500;
BA_ "GenSigSendType" SG_ 928 TripDuration_TripA 7;
BA_ "GenSigCycleTimeActive" SG_ 928 TripDuration_TripA 500;
BA_ "GenSigCycleTime" SG_ 928 TripDuration_TripA 500;
BA_ "GenSigTimeoutMsg_HU_High_X445" SG_ 928 TripDuration_TripA 2500;
BA_ "GenSigTimeoutMsg_HU_Mid_X445" SG_ 928 TripDuration_TripA 2500;
BA_ "GenSigTimeoutTime_HU_High_X445" SG_ 928 TripDuration_TripA 2500;
BA_ "GenSigTimeoutTime_HU_Mid_X445" SG_ 928 TripDuration_TripA 2500;
BA_ "GenSigTimeoutMsg_IVI" SG_ 928 TripDuration_TripA 2500;
BA_ "GenSigTimeoutTime_IVI" SG_ 928 TripDuration_TripA 2500;
BA_ "GenSigTimeoutTime_HU_Mid_X451" SG_ 928 AvgSpd_TripA 2500;
BA_ "GenSigTimeoutTime_HU_High_X451" SG_ 928 AvgSpd_TripA 2500;
BA_ "GenSigTimeoutTime_HU_B" SG_ 928 AvgSpd_TripA 2500;
BA_ "GenSigTimeoutTime_HU_A" SG_ 928 AvgSpd_TripA 2500;
BA_ "GenSigTimeoutMsg_HU_Mid_X451" SG_ 928 AvgSpd_TripA 2500;
BA_ "GenSigTimeoutMsg_HU_High_X451" SG_ 928 AvgSpd_TripA 2500;
BA_ "GenSigTimeoutMsg_HU_B" SG_ 928 AvgSpd_TripA 2500;
BA_ "GenSigTimeoutMsg_HU_A" SG_ 928 AvgSpd_TripA 2500;
BA_ "GenSigSendType" SG_ 928 AvgSpd_TripA 7;
BA_ "GenSigCycleTimeActive" SG_ 928 AvgSpd_TripA 500;
BA_ "GenSigCycleTime" SG_ 928 AvgSpd_TripA 500;
BA_ "GenSigTimeoutMsg_HU_High_X445" SG_ 928 AvgSpd_TripA 2500;
BA_ "GenSigTimeoutMsg_HU_Mid_X445" SG_ 928 AvgSpd_TripA 2500;
BA_ "GenSigTimeoutTime_HU_High_X445" SG_ 928 AvgSpd_TripA 2500;
BA_ "GenSigTimeoutTime_HU_Mid_X445" SG_ 928 AvgSpd_TripA 2500;
BA_ "GenSigTimeoutMsg_IVI" SG_ 928 AvgSpd_TripA 2500;
BA_ "GenSigTimeoutTime_IVI" SG_ 928 AvgSpd_TripA 2500;
BA_ "GenSigTimeoutTime_HU_Mid_X451" SG_ 928 TripDistance_TripA 2500;
BA_ "GenSigTimeoutTime_HU_High_X451" SG_ 928 TripDistance_TripA 2500;
BA_ "GenSigTimeoutTime_HU_B" SG_ 928 TripDistance_TripA 2500;
BA_ "GenSigTimeoutTime_HU_A" SG_ 928 TripDistance_TripA 2500;
BA_ "GenSigTimeoutMsg_HU_Mid_X451" SG_ 928 TripDistance_TripA 2500;
BA_ "GenSigTimeoutMsg_HU_High_X451" SG_ 928 TripDistance_TripA 2500;
BA_ "GenSigTimeoutMsg_HU_B" SG_ 928 TripDistance_TripA 2500;
BA_ "GenSigTimeoutMsg_HU_A" SG_ 928 TripDistance_TripA 2500;
BA_ "GenSigSendType" SG_ 928 TripDistance_TripA 7;
BA_ "GenSigCycleTimeActive" SG_ 928 TripDistance_TripA 500;
BA_ "GenSigCycleTime" SG_ 928 TripDistance_TripA 500;
BA_ "GenSigTimeoutMsg_HU_High_X445" SG_ 928 TripDistance_TripA 2500;
BA_ "GenSigTimeoutMsg_HU_Mid_X445" SG_ 928 TripDistance_TripA 2500;
BA_ "GenSigTimeoutTime_HU_High_X445" SG_ 928 TripDistance_TripA 2500;
BA_ "GenSigTimeoutTime_HU_Mid_X445" SG_ 928 TripDistance_TripA 2500;
BA_ "GenSigTimeoutMsg_IVI" SG_ 928 TripDistance_TripA 2500;
BA_ "GenSigTimeoutTime_IVI" SG_ 928 TripDistance_TripA 2500;
BA_ "GenSigTimeoutTime_HU_Mid_X451" SG_ 928 AvgFuelEconomy_TripA 2500;
BA_ "GenSigTimeoutTime_HU_High_X451" SG_ 928 AvgFuelEconomy_TripA 2500;
BA_ "GenSigTimeoutTime_HU_B" SG_ 928 AvgFuelEconomy_TripA 2500;
BA_ "GenSigTimeoutTime_HU_A" SG_ 928 AvgFuelEconomy_TripA 2500;
BA_ "GenSigTimeoutMsg_HU_Mid_X451" SG_ 928 AvgFuelEconomy_TripA 2500;
BA_ "GenSigTimeoutMsg_HU_High_X451" SG_ 928 AvgFuelEconomy_TripA 2500;
BA_ "GenSigTimeoutMsg_HU_B" SG_ 928 AvgFuelEconomy_TripA 2500;
BA_ "GenSigTimeoutMsg_HU_A" SG_ 928 AvgFuelEconomy_TripA 2500;
BA_ "GenSigSendType" SG_ 928 AvgFuelEconomy_TripA 7;
BA_ "GenSigCycleTimeActive" SG_ 928 AvgFuelEconomy_TripA 500;
BA_ "GenSigCycleTime" SG_ 928 AvgFuelEconomy_TripA 500;
BA_ "GenSigTimeoutMsg_HU_High_X445" SG_ 928 AvgFuelEconomy_TripA 2500;
BA_ "GenSigTimeoutMsg_HU_Mid_X445" SG_ 928 AvgFuelEconomy_TripA 2500;
BA_ "GenSigTimeoutTime_HU_High_X445" SG_ 928 AvgFuelEconomy_TripA 2500;
BA_ "GenSigTimeoutTime_HU_Mid_X445" SG_ 928 AvgFuelEconomy_TripA 2500;
BA_ "GenSigTimeoutMsg_IVI" SG_ 928 AvgFuelEconomy_TripA 2500;
BA_ "GenSigTimeoutTime_IVI" SG_ 928 AvgFuelEconomy_TripA 2500;
BA_ "GenSigTimeoutTime_HU_Mid_X451" SG_ 929 TripDuration_TripB 2500;
BA_ "GenSigTimeoutTime_HU_High_X451" SG_ 929 TripDuration_TripB 2500;
BA_ "GenSigTimeoutTime_HU_B" SG_ 929 TripDuration_TripB 2500;
BA_ "GenSigTimeoutTime_HU_A" SG_ 929 TripDuration_TripB 2500;
BA_ "GenSigTimeoutMsg_HU_Mid_X451" SG_ 929 TripDuration_TripB 2500;
BA_ "GenSigTimeoutMsg_HU_High_X451" SG_ 929 TripDuration_TripB 2500;
BA_ "GenSigTimeoutMsg_HU_B" SG_ 929 TripDuration_TripB 2500;
BA_ "GenSigTimeoutMsg_HU_A" SG_ 929 TripDuration_TripB 2500;
BA_ "GenSigSendType" SG_ 929 TripDuration_TripB 7;
BA_ "GenSigCycleTimeActive" SG_ 929 TripDuration_TripB 500;
BA_ "GenSigCycleTime" SG_ 929 TripDuration_TripB 500;
BA_ "GenSigTimeoutMsg_HU_High_X445" SG_ 929 TripDuration_TripB 2500;
BA_ "GenSigTimeoutMsg_HU_Mid_X445" SG_ 929 TripDuration_TripB 2500;
BA_ "GenSigTimeoutTime_HU_High_X445" SG_ 929 TripDuration_TripB 2500;
BA_ "GenSigTimeoutTime_HU_Mid_X445" SG_ 929 TripDuration_TripB 2500;
BA_ "GenSigTimeoutMsg_IVI" SG_ 929 TripDuration_TripB 2500;
BA_ "GenSigTimeoutTime_IVI" SG_ 929 TripDuration_TripB 2500;
BA_ "GenSigTimeoutTime_HU_Mid_X451" SG_ 929 AvgSpd_TripB 2500;
BA_ "GenSigTimeoutTime_HU_High_X451" SG_ 929 AvgSpd_TripB 2500;
BA_ "GenSigTimeoutTime_HU_B" SG_ 929 AvgSpd_TripB 2500;
BA_ "GenSigTimeoutTime_HU_A" SG_ 929 AvgSpd_TripB 2500;
BA_ "GenSigTimeoutMsg_HU_Mid_X451" SG_ 929 AvgSpd_TripB 2500;
BA_ "GenSigTimeoutMsg_HU_High_X451" SG_ 929 AvgSpd_TripB 2500;
BA_ "GenSigTimeoutMsg_HU_B" SG_ 929 AvgSpd_TripB 2500;
BA_ "GenSigTimeoutMsg_HU_A" SG_ 929 AvgSpd_TripB 2500;
BA_ "GenSigSendType" SG_ 929 AvgSpd_TripB 7;
BA_ "GenSigCycleTimeActive" SG_ 929 AvgSpd_TripB 500;
BA_ "GenSigCycleTime" SG_ 929 AvgSpd_TripB 500;
BA_ "GenSigTimeoutMsg_HU_High_X445" SG_ 929 AvgSpd_TripB 2500;
BA_ "GenSigTimeoutMsg_HU_Mid_X445" SG_ 929 AvgSpd_TripB 2500;
BA_ "GenSigTimeoutTime_HU_High_X445" SG_ 929 AvgSpd_TripB 2500;
BA_ "GenSigTimeoutTime_HU_Mid_X445" SG_ 929 AvgSpd_TripB 2500;
BA_ "GenSigTimeoutMsg_IVI" SG_ 929 AvgSpd_TripB 2500;
BA_ "GenSigTimeoutTime_IVI" SG_ 929 AvgSpd_TripB 2500;
BA_ "GenSigTimeoutTime_HU_Mid_X451" SG_ 929 AvgFuelEconomy_TripB 2500;
BA_ "GenSigTimeoutTime_HU_High_X451" SG_ 929 AvgFuelEconomy_TripB 2500;
BA_ "GenSigTimeoutTime_HU_B" SG_ 929 AvgFuelEconomy_TripB 2500;
BA_ "GenSigTimeoutTime_HU_A" SG_ 929 AvgFuelEconomy_TripB 2500;
BA_ "GenSigTimeoutMsg_HU_Mid_X451" SG_ 929 AvgFuelEconomy_TripB 2500;
BA_ "GenSigTimeoutMsg_HU_High_X451" SG_ 929 AvgFuelEconomy_TripB 2500;
BA_ "GenSigTimeoutMsg_HU_B" SG_ 929 AvgFuelEconomy_TripB 2500;
BA_ "GenSigTimeoutMsg_HU_A" SG_ 929 AvgFuelEconomy_TripB 2500;
BA_ "GenSigSendType" SG_ 929 AvgFuelEconomy_TripB 7;
BA_ "GenSigCycleTimeActive" SG_ 929 AvgFuelEconomy_TripB 500;
BA_ "GenSigCycleTime" SG_ 929 AvgFuelEconomy_TripB 500;
BA_ "GenSigTimeoutMsg_HU_High_X445" SG_ 929 AvgFuelEconomy_TripB 2500;
BA_ "GenSigTimeoutMsg_HU_Mid_X445" SG_ 929 AvgFuelEconomy_TripB 2500;
BA_ "GenSigTimeoutTime_HU_High_X445" SG_ 929 AvgFuelEconomy_TripB 2500;
BA_ "GenSigTimeoutTime_HU_Mid_X445" SG_ 929 AvgFuelEconomy_TripB 2500;
BA_ "GenSigTimeoutMsg_IVI" SG_ 929 AvgFuelEconomy_TripB 2500;
BA_ "GenSigTimeoutTime_IVI" SG_ 929 AvgFuelEconomy_TripB 2500;
BA_ "GenSigTimeoutTime_HU_Mid_X451" SG_ 929 TripDistance_TripB 2500;
BA_ "GenSigTimeoutTime_HU_High_X451" SG_ 929 TripDistance_TripB 2500;
BA_ "GenSigTimeoutTime_HU_B" SG_ 929 TripDistance_TripB 2500;
BA_ "GenSigTimeoutTime_HU_A" SG_ 929 TripDistance_TripB 2500;
BA_ "GenSigTimeoutMsg_HU_Mid_X451" SG_ 929 TripDistance_TripB 2500;
BA_ "GenSigTimeoutMsg_HU_High_X451" SG_ 929 TripDistance_TripB 2500;
BA_ "GenSigTimeoutMsg_HU_B" SG_ 929 TripDistance_TripB 2500;
BA_ "GenSigTimeoutMsg_HU_A" SG_ 929 TripDistance_TripB 2500;
BA_ "GenSigSendType" SG_ 929 TripDistance_TripB 7;
BA_ "GenSigCycleTimeActive" SG_ 929 TripDistance_TripB 500;
BA_ "GenSigCycleTime" SG_ 929 TripDistance_TripB 500;
BA_ "GenSigTimeoutMsg_HU_High_X445" SG_ 929 TripDistance_TripB 2500;
BA_ "GenSigTimeoutMsg_HU_Mid_X445" SG_ 929 TripDistance_TripB 2500;
BA_ "GenSigTimeoutTime_HU_High_X445" SG_ 929 TripDistance_TripB 2500;
BA_ "GenSigTimeoutTime_HU_Mid_X445" SG_ 929 TripDistance_TripB 2500;
BA_ "GenSigTimeoutMsg_IVI" SG_ 929 TripDistance_TripB 2500;
BA_ "GenSigTimeoutTime_IVI" SG_ 929 TripDistance_TripB 2500;
VAL_ 509 BCmAmbLightModeSelActiveVal 3 "Reserved for future use." 2 "ON mode" 1 "OFF mode" 0 "Auto mode" ;
VAL_ 509 BCmAmbLightIllumSelActiveVal 7 "Reserved for future use." 6 "Reserved for future use." 5 "Level 5 Intensity" 4 "Level 4 Intensity" 3 "Level 3 Intensity" 2 "Level 2 Intensity" 1 "Level 1 Intensity" 0 "Reserved for future use." ;
VAL_ 509 AmbLightIllumPossibleLevels 7 "Reserved for future use." 6 "Reserved for future use." 5 "Intensity is varied in 5 levels" 4 "Intensity is varied in 4 levels" 3 "Intensity is varied in 3 levels" 2 "Intensity is varied in 2 levels" 1 "No Intensity variation possible. " 0 "Reserved for future use." ;
VAL_ 509 BCmAmbLightData 3 "Reserved" 2 "BCM sends ambient light data to HU" 1 "BCM Acknowledges the Ambient light data sent by HU" 0 "Reserved" ;
VAL_ 510 HuAmbLightModeSelActiveVal 3 "reserve for future use" 2 "ON mode" 1 "OFF mode" 0 "Auto mode" ;
VAL_ 510 HuAmbLightIllumSelActiveVal 7 "Reserved for future use." 6 "Reserved for future use." 5 "Level 5 Intensity" 4 "Level 4 Intensity" 3 "Level 3 Intensity" 2 "Level 2 Intensity" 1 "Level 1 Intensity" 0 "Reserved for future use." ;
VAL_ 510 HuAmbLightIllumPossibleLevels 7 "Reserved for future use." 6 "Reserved for future use." 5 "Intensity 5" 4 "Intensity 4" 3 "Intensity 3" 2 " Intensity 2 " 1 " Intensity 1" 0 "Reserved for future use." ;
VAL_ 510 HuAmbLightData 3 "Reserved" 2 "HU sends ambient  light user changed data changed to BCM" 1 "Hu Ackknowledges the  Ambient light data send by BCM" 0 "Reserved" ;
VAL_ 571 ColorThemeCoDrvr 7 "color 8" 6 "color 7" 5 "color 6" 4 "color 5" 3 "color 4" 2 "color 3" 1 "color 2" 0 "color 1" ;
VAL_ 571 ColorThemeDrvr 7 "color 8" 6 "color 7" 5 "color 6" 4 "color 5" 3 "color 4" 2 "color 3" 1 "color 2" 0 "color 1" ;
VAL_ 571 CcmHuRearBlwrOnOffState 1 "Rear Blower ON" 0 "Rear Blower OFF" ;
VAL_ 571 CcmHuUserInterventionBeep 1 "Beep" 0 "No Beep" ;
VAL_ 571 AutoDefogState 3 "Reserved" 2 "Active" 1 "Monitoring" 0 "Inactive" ;
VAL_ 571 CCmHuExpressCoolSwitchStatus 1 "Express Cool feature ON" 0 "Express Cool feature OFF" ;
VAL_ 571 CCmHuFanSpdStatus 15 "Reserved" 14 "Reserved" 13 "Reserved" 12 "Reserved" 11 "Reserved" 10 "Reserved" 9 "Reserved" 8 "Reserved" 7 "Speed 7" 6 "Speed 6" 5 "Speed 5" 4 "Speed 4" 3 "Speed 3" 2 "Speed 2" 1 "Speed 1" 0 "Speed 0 ( only for FATC dual ) / Reserved (ETC & FATC Single zone)" ;
VAL_ 571 CCmHuDistribSwitchStatus 7 "Reserved" 6 "Reserved" 5 "DefrostMode Status
" 4 "LegDefrostMode Status" 3 "LegMode Status" 2 "Chest-LegMode Status" 1 "ChestModeStatus" 0 "Reserved" ;
VAL_ 571 CCmHuDualModeSwStatus 1 "Dual Mode ON" 0 "Dual Mode OFF" ;
VAL_ 571 CCmHuTempWhlStatusPass 31 "HI" 30 "Reserved" 29 "30 Deg C" 28 "29.5 Deg C" 27 "29 Deg C" 26 "28.5 Deg C" 25 "28 Deg C" 24 "27.5 Deg C" 23 "27 Deg C" 22 "26.5 Deg C" 21 "26 Deg C" 20 "25.5 Deg C" 19 "25 Deg C" 18 "24.5 Deg C" 17 "24 Deg C" 16 "23.5 Deg C" 15 "23 Deg C" 14 "22.5 Deg C" 13 "22 Deg C" 12 "21.5 Deg C" 11 "21 Deg C" 10 "20.5 Deg C" 9 "20 Deg C" 8 "19.5 Deg C" 7 "19 Deg C" 6 "18.5 Deg C" 5 "18 Deg C" 4 "17.5 Deg C" 3 "17 Deg C" 2 "16.5 Deg C" 1 "16 Deg C" 0 "LO" ;
VAL_ 571 CCMHuFreshAirRecircSwitchStatus 3 "Reserved" 2 "Fresh Air ON" 1 "Recirculation with AQS (applicable for dual zone FATC)" 0 "Recirculation ON" ;
VAL_ 571 CCmHuAutoSwitchStatus 1 "Auto is ON" 0 "Auto is OFF" ;
VAL_ 571 CCmHuTempWhlStatus 31 "HI" 30 "Reserved" 29 "30 Deg C" 28 "29.5 Deg C" 27 "29 Deg C" 26 "28.5 Deg C" 25 "28 Deg C" 24 "27.5 Deg C" 23 "27 Deg C" 22 "26.5 Deg C" 21 "26 Deg C" 20 "25.5 Deg C" 19 "25 Deg C" 18 "24.5 Deg C" 17 "24 Deg C" 16 "23.5 Deg C" 15 "23 Deg C" 14 "22.5 Deg C" 13 "22 Deg C" 12 "21.5 Deg C" 11 "21 Deg C" 10 "20.5 Deg C" 9 "20 Deg C" 8 "19.5 Deg C" 7 "19 Deg C" 6 "18.5 Deg C" 5 "18 Deg C" 4 "17.5 Deg C" 3 "17 Deg C" 2 "16.5 Deg C" 1 "16 Deg C" 0 "LO" ;
VAL_ 571 CCmHuEconModeSwitchStatus 1 "Economy is ON" 0 "Economy is OFF" ;
VAL_ 571 CCmHuMaxDefrstSwitchStatus 1 "Max defrost ON" 0 "Max defrost OFF" ;
VAL_ 571 CCmHuRearDefogSwitchStatus 1 "Rear defog is ON" 0 "Rear defog is OFF" ;
VAL_ 571 CCmHuTempWhlStatusDrvr 31 "HI" 30 "Reserved" 29 "30 Deg C" 28 "29.5 Deg C" 27 "29 Deg C" 26 "28.5 Deg C" 25 "28 Deg C" 24 "27.5 Deg C" 23 "27 Deg C" 22 "26.5 Deg C" 21 "26 Deg C" 20 "25.5 Deg C" 19 "25 Deg C" 18 "24.5 Deg C" 17 "24 Deg C" 16 "23.5 Deg C" 15 "23 Deg C" 14 "22.5 Deg C" 13 "22 Deg C" 12 "21.5 Deg C" 11 "21 Deg C" 10 "20.5 Deg C" 9 "20 Deg C" 8 "19.5 Deg C" 7 "19 Deg C" 6 "18.5 Deg C" 5 "18 Deg C" 4 "17.5 Deg C" 3 "17 Deg C" 2 "16.5 Deg C" 1 "16 Deg C" 0 "LO" ;
VAL_ 571 CCmHuAirConCompSwitchStatus 1 "AC is ON" 0 "AC is OFF" ;
VAL_ 571 CCmHuCtrlPnlStatus 1 "Control Panel ON" 0 "Control Panel OFF" ;
VAL_ 571 CCmHuChangeBit 1 "Change bit OFF" 0 "Change bit ON" ;
VAL_ 571 CCmHuUserInterventionStatusFlag 31 "Reserved" 30 "Reserved" 29 "Reserved" 28 "Reserved" 27 "Reserved" 26 "Reserved" 25 "Reserved" 24 "Reserved" 23 "Reserved" 22 "Reserved" 21 "Reserved" 20 "Reserved" 19 "Reserved" 18 "Autodefog User Intervention flag " 17 "Rear Blower Flag" 16 "FL Seat Ventilation Flag" 15 "FR Seat Ventilation Flag" 14 "Express Cool Flag" 13 "Rear defog Flag" 12 "Temperature Wheel  flag" 11 "Dual button flag" 10 "Fan speed wheel flag" 9 "Temperature Wheel driver flag" 8 "Temperature Wheel Passenger flag" 7 "Distribution button flag" 6 "Recirculation button flag" 5 "Maxdefrost button flag" 4 "Off button flag" 3 "Auto button flag" 2 "Econ button flag" 1 "AC Button flag" 0 "CCmHuUserInterventionStatusFlagClear" ;
VAL_ 571 CCmHuTempWhlStatusStatus 3 "Signal not available" 2 "Reserved for future" 1 "Reserved for future" 0 "Plausible " ;
VAL_ 571 CCmHuErrStatus 1 "CCM Error" 0 "CCM fully available " ;
VAL_ 571 CCmHuDualModeSwStatusStatus 3 "Signal not available" 2 "Value is implausible " 1 "Reserved for future" 0 "Value is correct" ;
VAL_ 571 CCmHuTempWhlStatusPassStatus 3 "Signal not available" 2 "Reserved for future" 1 "Reserved for future" 0 "Plausible" ;
VAL_ 571 CCmHuTempWhlStatusDrvrStatus 3 "Signal not available" 2 "Reserved for future" 1 "Reserved for future" 0 "Plausible  " ;
VAL_ 573 LockStateESCL 1 "ESCL is locked" 0 "ESCL is not locked" ;
VAL_ 573 UnlockStateESCL 1 "ESCL is unlocked" 0 "ESCL is not unlocked" ;
VAL_ 651 EPAsStatusGen2 3 "Reserved " 2 "EPAS Not available & Lamp ON" 1 "Reserved" 0 "EPAS Fullly available & Lamp Off" ;
VAL_ 651 SAsAngEPAsDir 1 "Steering Wheel turned in the Counter clockwise direction" 0 "Steering Wheel turned in the Clockwise direction" ;
VAL_ 651 SAsAngEPASStatus 3 "Reserved" 2 "SAS angle Value is implausible" 1 "Reserved " 0 "Information given by SAS angle is correct and according to specification" ;
VAL_ 656 StuckModeAvailability 1 "Stuck Mode function is available" 0 "Stuck Mode function is not available" ;
VAL_ 656 StuckModeStateStatus 3 "Reserved" 2 "Stuck mode is implausible" 1 "Reserved" 0 "Stuck mode is plausible" ;
VAL_ 656 StuckModeState 7 "Reserved" 6 "stuck mode deactivated" 5 "stuck mode cannot help" 4 "Well Done!" 3 "Stuck mode Turned off due to high Teamprature" 2 "Stuck Mode ON" 1 "Stuck Identified by ABS" 0 "Stuck Mode OFF" ;
VAL_ 656 WSsPulseCountFrontRHStatus 3 "Reserved" 2 "value is implausible" 1 "Reserved" 0 "Value is plausible" ;
VAL_ 656 WSsPulseCountRearLHStatus 3 "Reserved" 2 "value is implausible" 1 "Reserved" 0 "Value is plausible" ;
VAL_ 656 WSsPulseCountRearRHStatus 3 "Reserved" 2 "value is implausible" 1 "Reserved" 0 "Value is plausible" ;
VAL_ 656 WSsPulseCountFrontLHStatus 3 "Reserved" 2 "value is implausible" 1 "Reserved" 0 "Value is plausible" ;
VAL_ 656 DrvModeIndctnESPStatusNew 3 "Signal is not available" 2 "Signal is implausible" 1 "Reserved" 0 "Signal is correct" ;
VAL_ 656 DrvModeIndctnESPNew 7 "Rough Road" 6 "Wet/Rain" 5 "Reserved" 4 "Sand" 3 "Mud / Ruts / Gravel " 2 "Grass / Snow" 1 "Sports" 0 "Normal" ;
VAL_ 693 ParkBrkState 1 "Park Brake is ON" 0 "Park Brake is Off" ;
VAL_ 693 IcPlatformVariant 15 "Reserved" 14 "Reserved" 13 "Reserved" 12 "IC_Gen3_4LCD" 11 "IC_Gen3_10.25TFT" 10 "IC_Digital_7TFT" 9 "IC_4LCD_X451" 8 "IC_7TFT_Q5" 7 "IC_7TFT_X451" 6 "IC_4LCD_Q5" 5 "IC-F" 4 "IC-C-Eagle" 3 "IC-B" 2 "IC-C" 1 "IC-E" 0 "IC-D" ;
VAL_ 693 OATICSigStatus 3 "Signal not available" 2 "Value is impluasible" 1 "Reserved" 0 "Value is plausible" ;
VAL_ 693 IcPresence 1 "Reserved" 0 "IC Present" ;
VAL_ 693 SRSWarningLampStatus 1 "Lamp Failure" 0 "Lamp No failure" ;
VAL_ 693 VsSPulseCountSigStatus 3 "Signal not available" 2 "Reserved for future" 1 "Reserved for future" 0 "Value is correct" ;
VAL_ 693 IcHuVoiceAlertState 26 "Smart key out of range" 25 "Key Fob battery Low" 24 "Service Remainder" 23 "Water in Fuel" 22 "Low Oil Pressure" 21 "Low Brake fluid" 20 "Low fuel warning" 19 "Rear Left Tyre Pressure Monitoring" 18 "Rear Right Tyre Pressure Monitoring" 17 "Front Left Tyre Pressure Monitoring" 16 "Front Right Tyre Pressure Monitoring" 15 "Park Brake ON" 14 "Driver Seat Belt Remainder" 13 "Tail Gate open" 12 "Rear Left door open" 11 "Rear Right door open" 10 "Co Driver Door open" 9 "Driver Door Open" 8 "Door Open - general warning" 7 "Economy Mode" 6 "Sport Mode" 5 "Normal/ City Mode" 4 "Rough Road Mode" 3 "Dynamic Mode" 2 "Comfort Mode" 1 "Auto Mode" 0 "No Warning" ;
VAL_ 693 IcHuVoiceAlertStateStatus 1 "Active" 0 "Inactive" ;
VAL_ 693 ICCurDriveModeSig 15 "Reserved" 14 "Reserved" 13 "Reserved" 12 "Reserved" 11 "Reserved" 10 "Reserved" 9 "Reserved" 8 "Reserved" 7 "Reserved" 6 "Eco Mode" 5 "Sport Mode" 4 "City Mode" 3 "Dynamic Mode" 2 "Rough Road Mode" 1 "Comfort Mode" 0 "Auto Mode" ;
VAL_ 693 IcHuCarImageSelection 15 "Reserved" 14 "Reserved" 13 "Reserved" 12 "Reserved" 11 "Reserved" 10 "X451 EV Car Image" 9 "X446 Car Image" 8 "X445 Car Image" 7 "X442 Car Image" 6 "X441 Car Image" 5 "X454 Car Image" 4 "X453 Car Image" 3 "X452 Car Image" 2 "X451 Car Image" 1 "Q502 Car Image" 0 "Q501 Car Image" ;
VAL_ 693 IcSbDispReq 1 "Active" 0 "InActive" ;
VAL_ 693 IcSbrDrvrSeatBeltSwitchStatus 1 "Driver Seat Belt is not buckled" 0 "Driver Seat belt is buckled" ;
VAL_ 695 IcHuDTeInfoStatus 3 "Signal not available" 2 "Information given is implausible due to a detected failure " 1 "Reserved" 0 "Information given correct and according to specification" ;
VAL_ 695 IcHuDrvrSeatBeltInfo 1 "Driver Seat Belt On" 0 "Driver Seat Belt Off" ;
VAL_ 695 IcHuVehRegion 3 "Reserved" 2 "UK" 1 "Domestic" 0 "Export" ;
VAL_ 695 IcHuTyreSize 15 "Reserved" 14 "Reserved" 13 "Reserved" 12 "Reserved" 11 "Reserved" 10 "Reserved" 9 "Reserved" 8 "Reserved" 7 "Reserved" 6 "R19" 5 "R13" 4 "R18" 3 "R17" 2 "R16" 1 "R15" 0 "R14" ;
VAL_ 697 IcHuResetTripB 1 "Yes" 0 "No" ;
VAL_ 697 IcHuResetTripA 1 "Yes" 0 "No" ;
VAL_ 697 IcHuDriveType 1 "RHD" 0 "LHD" ;
VAL_ 698 IllumDimLvlSettingStatus 3 "Signal not available" 2 "Reserved" 1 "Reserved" 0 "Value is pluasible" ;
VAL_ 698 SwitchDimmingControlIPC 1 "Enable" 0 "Disable" ;
VAL_ 698 IllumOnOffCtrlStatus 3 "signal not available" 2 "Reserved" 1 "Reserved" 0 "value is plausible" ;
VAL_ 698 IllumOnOffCtrl 1 "illumination ON" 0 "illumination OFF" ;
VAL_ 698 SwitchDimmingControlIPCStatus 3 "Signal Not Available" 2 "Reserved for future use" 1 "Reserved for future use." 0 "Plausible and signal is correct" ;
VAL_ 700 IPCRemoteCheckStatus 3 "Signal Not available" 2 "Signal is implausible" 1 "Reserved" 0 "Signal is correct" ;
VAL_ 700 IPCRemoteCheck 3 "Reserved" 2 "IPC Remote AC & Engine Pre-condition check failed." 1 "IPC Remote AC & Engine Pre-condition check passed." 0 "Default State/Remote Command not requested" ;
VAL_ 700 NextServDueAlertStatus 3 "Reserved" 2 "Plausible" 1 "Reserved" 0 "Signal Not available" ;
VAL_ 700 NextServDueAlert 1 "Next service is due" 0 "Next Service is not due" ;
VAL_ 700 IcHuIceState 3 "Reserved for future use" 2 "Reserved for future use" 1 "Text Warning  is On" 0 "Text Warning is Off" ;
VAL_ 700 IcHuBrakeFluidLowState 3 "Reserved for future use" 2 "Lamp is ON" 1 "Lamp is Flashing" 0 "Lamp is Off" ;
VAL_ 700 IcHuFastenSeatBeltState 3 "Reserved for future use" 2 "Reserved for future use" 1 "Text Warning  is On" 0 "Text Warning is Off" ;
VAL_ 700 IcHuBatteryChargingState 3 "Reserved for future use" 2 "Lamp is ON" 1 "Lamp is Flashing" 0 "Lamp is Off" ;
VAL_ 702 IcHuOnBoardCompState 1 "Enabled" 0 "Disabled" ;
VAL_ 702 IcHuIcInfoFeaturePresenceAck 1 "Present" 0 "Not Present" ;
VAL_ 702 IcHuAlertStateStatus 1 "Active" 0 "Inactive" ;
VAL_ 702 IcHuAlertType 3 "Reserved" 2 "Reserved" 1 "Text Alert" 0 "Voice & Text Alert" ;
VAL_ 702 DriveAlert1_TeaBreak 1 "Tea Break Alert ON" 0 "Tea Break Alert OFF" ;
VAL_ 702 IcHuAlertState 127 "Reserved for future  (0x7F - 0xFF)" 126 "Reserved for future" 125 "Reserved for future" 124 "Reserved for future" 123 "Reserved for future" 122 "Reserved for future" 121 "Reserved for future" 120 "Reserved for future" 119 "Reserved for future" 118 "Reserved for future" 117 "Reserved for future" 116 "Reserved for future" 115 "Reserved for future" 114 "Reserved for future" 113 "Reserved for future" 112 "Reserved for future" 111 "Reserved for future" 110 "Reserved for future" 109 "Reserved for future" 108 "Reserved for future" 107 "Reserved for future" 106 "Reserved for future" 105 "Reserved for future" 104 "Reserved for future" 103 "Reserved for future" 102 "Reserved for future" 101 "Reserved for future" 100 "Reserved for future" 99 "Reserved for future" 98 "Reserved for future" 97 "Custom Drive/Terrain Mode		

" 96 "Drift Mode" 95 "Charging Lid Open" 94 "Rock Mode" 93 "Boost Mode" 92 "High Beam voice Alert" 91 "Shift to Park (P) or Neutral (N) To Start Engine" 90 "Owner’s Birthday " 89 "SHIFT TO PARK (P) to Exit" 88 "Bonnet open" 87 "Fasten Third Row Passenger Seatbelts" 86 "Fasten Second Row Passenger  Seatbelts" 85 "Fasten Passenger Seatbelts" 84 "Fasten Driver & Passenger Seatbelts" 83 "Malfunction detected, Please safely park the vehicle and Exit immediately" 82 "DDOA level 2 text2 voice alert" 81 "DDOA level 2 text1 voice alert" 80 "DDOA level 1 text voice alert" 79 "Battery Saver Mode Alert if SoC <30% " 78 "welcome message ev" 77 "charging status" 76 "battery low and user change gear to s mode" 75 "hand brake to be engaged (hand brake engaged during charging)" 74 "charge full" 73 "System de-energies" 72 "HV system fault, contact service center" 71 "Vehicle will shift to Neutral in next 5 mins for your Safety" 70 "HV system fault, please stop the vehicle & contact service center" 69 "EV charging update" 68 "Hazard on alert" 67 "Head lamps ON alert" 66 "Park lamps on alert" 65 "Engage Park brake + Take key fob out" 64 "Take key Fob out" 63 "Low Ambient Temperature / Its Already Cold Outside" 62 "Roll Up the windows if down" 61 "Express Cooling OFF, Roll Up the windows if down" 60 "Express Cooling ON windows may roll DOWN" 59 "Express Cooling OFF, Normal Cooling Mode ON" 58 "Express Cooling ON" 57 "Key Not Found" 56 "Cruise ON/Ready to Cruise" 55 "Fasten seat belt co-driver" 54 "Key Fob battery Low" 53 "Water in Fuel" 52 "Drive Alert1 - Tea Break" 51 "Fuel Level Low State" 50 "Engine Oil Pressure Low State" 49 "Fuel filter clogging" 48 "Service Reminder Kms" 47 "Service Reminder Days" 46 "Cruise Activated" 45 "Forward Collision Warning Indication" 44 "Pressure Leakage Alert Spare" 43 "Pressure Leakage Alert RR" 42 "Pressure Leakage Alert RL" 41 "Pressure Leakage Alert FR" 40 "Pressure Leakage Alert FL" 39 "HighTireTemp Alert Spare" 38 "HighTireTemp Alert RR" 37 "HighTireTemp Alert RL" 36 "HighTireTemp Alert FR" 35 "HighTireTemp Alert FL" 34 "High Tire Pressure Alert Spare" 33 "High Tire Pressure Alert RR" 32 "High Tire Pressure Alert RL" 31 "High Tire Pressure Alert FR" 30 "High Tire Pressure Alert FL" 29 "Low Tire Pressure Alert Spare" 28 "Low Tire Pressure Alert RR" 27 "Low Tire Pressure Alert RL" 26 "Low Tire Pressure Alert FR" 25 "Low Tire Pressure Alert FL" 24 "TPMS - General warning" 23 "Low SoC Indication" 22 "Low Brake Fluid" 21 "Park Brake Engaged" 20 "HDC Activated" 19 "HDC deactivated due to speed above set value" 18 "Fasten seat belt - Driver" 17 "Tail gate open" 16 "Rear left door open" 15 "Rear right door open" 14 "Co-Driver Door open" 13 "Driver Door open" 12 "Door open- General warning" 11 "Grass/Snow" 10 "Sand" 9 "Mud/Rust/Gravel" 8 "Wet/Rain Mode" 7 "Economy Mode" 6 "Sport Mode" 5 "City Mode" 4 "Rough Road Mode" 3 "Dynamic Mode" 2 "Comfort mode" 1 "Auto Mode" 0 "No Warning" ;
VAL_ 704 HuIcSourceNew 127 "IVI info in IC feature Not present" 126 "Reserved for future" 125 "Reserved for future" 124 "Reserved for future" 123 "Reserved for future" 122 "Reserved for future" 121 "Reserved for future" 120 "Reserved for future" 119 "Reserved for future" 118 "Reserved for future" 117 "Reserved for future" 116 "Reserved for future" 115 "Reserved for future" 114 "Reserved for future" 113 "Reserved for future" 112 "Reserved for future" 111 "Reserved for future" 110 "Reserved for future" 109 "Reserved for future" 108 "Reserved for future" 107 "Reserved for future" 106 "Reserved for future" 105 "Reserved for future" 104 "Reserved for future" 103 "Reserved for future" 102 "Reserved for future" 101 "Reserved for future" 100 "Reserved for future" 99 "Reserved for future" 98 "Reserved for future" 97 "Reserved for future" 96 "Reserved for future" 95 "Reserved for future" 94 "Reserved for future" 93 "Reserved for future" 92 "Reserved for future" 91 "Reserved for future" 90 "Reserved for future" 89 "Reserved for future" 88 "Reserved for future" 87 "Reserved for future" 86 "Reserved for future" 85 "Reserved for future" 84 "Reserved for future" 83 "Reserved for future" 82 "Reserved for future" 81 "Reserved for future" 80 "Reserved for future" 79 "Reserved for future" 78 "Reserved for future" 77 "Reserved for future" 76 "Reserved for future" 75 "Reserved for future" 74 "Reserved for future" 73 "Reserved for future" 72 "Reserved for future" 71 "Reserved for future" 70 "Reserved for future" 69 "Reserved for future" 68 "Reserved for future" 67 "Reserved for future" 66 "Reserved for future" 65 "Reserved for future" 64 "Reserved for future" 63 "Reserved for future" 62 "Reserved for future" 61 "Reserved for future" 60 "Reserved for future" 59 "Reserved for future" 58 "Reserved for future" 57 "Reserved for future" 56 "Reserved for future" 55 "Reserved for future" 54 "Reserved for future" 53 "Reserved for future" 52 "Reserved for future" 51 "Reserved for future" 50 "Reserved for future" 49 "Reserved for future" 48 "Reserved for future" 47 "Reserved for future" 46 "Reserved for future" 45 "Reserved for future" 44 "Reserved for future" 43 "Reserved for future" 42 "Reserved for future" 41 "Reserved for future" 40 "Reserved for future" 39 "Reserved for future" 38 "Reserved for future" 37 "Reserved for future" 36 "Reserved for future" 35 "Reserved for future" 34 "Reserved for future" 33 "Reserved for future" 32 "Reserved for future" 31 "Reserved for future" 30 "Reserved for future" 29 "Reserved for future" 28 "Hungama" 27 "Gaana" 26 "JioSaavn" 25 "Media OFF" 24 "Alexa SiriusXM" 23 "Alexa ideezer" 22 "Alexa Pandora" 21 "Alexa iHeartRadio" 20 "Alexa TuneIN" 19 "Alexa Spotify" 18 "Alexa Kindle" 17 "Alexa Audible" 16 "Alexa Amazon music" 15 "CarPlay VR" 14 "Android Auto VR" 13 "Alexa VR" 12 "Voice recognition" 11 "SMS Read Out" 10 "CarPlay Audio" 9 "Android Auto Audio" 8 "Phone" 7 "Bluetooth Audio" 6 "Aux" 5 "DRM" 4 "FM" 3 "AM" 2 "iPod" 1 "USB" 0 "No Device" ;
VAL_ 704 GpsCompassPresence 1 "Compass information not available" 0 "Compass information available" ;
VAL_ 704 GPsCourseInfoStatusIVI 3 "Signal Not Available" 2 "Signal value is implausible" 1 "Reserved for future use." 0 "Plausible  - Information given is correct and according to specification" ;
VAL_ 704 StuckModeUserResponse 3 "User Turned Off Stuck Mode" 2 "User Ignored Stuck Mode Activation request" 1 "User made stuck mode ON" 0 "No Action" ;
VAL_ 704 HuIcDistanceDisplayUnitEnum 7 "Reserved" 6 "Reserved" 5 "Reserved" 4 "Feet" 3 "Yards" 2 "Meter" 1 "Miles" 0 "Kilo Metre" ;
VAL_ 704 HuPresence 1 "Reserved" 0 "HU Present" ;
VAL_ 704 HuPlatformVariant 31 "Reserved" 30 "Reserved" 29 "Reserved" 28 "Reserved" 27 "Reserved" 26 "Gen3mid_05" 25 "Gen3mid_03" 24 "Gen3mid_02" 23 "Gen3mid_01" 22 "Gen3_High4" 21 "Gen3_High++" 20 "Gen3_High+" 19 "Gen3_High" 18 "Gen3_Mid+" 17 "Gen3_Mid" 16 "HU_High_X445" 15 "HU_Mid_X445" 14 "X0_Level_A_VaVe" 13 "HU_7" 12 "HU_High_X451" 11 "HU_Mid_X451" 10 "HU_High_Q5" 9 "HU_Mid_Q5" 8 "HU_Low_Q5" 7 "Gen1+ Level B" 6 "Gen1+ Level A" 5 "Level B Eagle" 4 "Hexa_HU_7_VaVe" 3 "Nexon_Level_B_VaVe" 2 "Nexon_Level_A_VaVe" 1 "Lavel B" 0 "Level A" ;
VAL_ 704 SbIcDispState 3 "Reserved" 2 "SbIcDispActive" 1 "SbIcDispStandBy" 0 "SbIcDispSwitchOff" ;
VAL_ 704 HuIcAlertStatusAck 7 "Error" 6 "Aborted" 5 "Ignored" 4 "Delivered" 3 "In Process" 2 "In Queue" 1 "Received" 0 "No Alert" ;
VAL_ 704 HuIcAlertStateAck 127 "Reserved for future (0x7F -0xFF)" 126 "Reserved for future" 125 "Reserved for future" 124 "Reserved for future" 123 "Reserved for future" 122 "Reserved for future" 121 "Reserved for future" 120 "Reserved for future" 119 "Reserved for future" 118 "Reserved for future" 117 "Reserved for future" 116 "Reserved for future" 115 "Reserved for future" 114 "Reserved for future" 113 "Reserved for future" 112 "Reserved for future" 111 "Reserved for future" 110 "Reserved for future" 109 "Reserved for future" 108 "Reserved for future" 107 "Reserved for future" 106 "Reserved for future" 105 "Reserved for future" 104 "Reserved for future" 103 "Reserved for future" 102 "Reserved for future" 101 "Reserved for future" 100 "Reserved for future" 99 "Reserved for future" 98 "Reserved for future" 97 "Custom Drive/Terrain Mode" 96 "Drift Mode" 95 "Charging Lid Open" 94 "Rock Mode" 93 "Boost Mode" 92 "High Beam voice alert" 91 "Shift to Park (P) or Neutral (N) To Start Engine" 90 "Owner’s Birthday " 89 "SHIFT TO PARK (P) to Exit" 88 "Bonnet open" 87 "Fasten Third Row Passenger Seatbelts" 86 "Fasten Second Row Passenger  Seatbelts" 85 "Fasten Passenger Seatbelts" 84 "Fasten Driver & Passenger Seatbelts" 83 "Malfunction detected, Please safely park the vehicle and Exit immediately" 82 "DDOA level 2 text2 voice alert" 81 "DDOA level 2 text1 voice alert" 80 "DDOA level 1 text voice alert" 79 "Battery Saver Mode Alert if SoC <30% " 78 "welcome message ev" 77 "charging status" 76 "battery low and user change gear to s mode" 75 "hand brake to be engaged (hand brake engaged during charging)" 74 "charge full" 73 "System de-energies" 72 "HV system fault, contact service center" 71 "Vehicle will shift to Neutral in next 5 mins for your Safety" 70 "HV system fault, please stop the vehicle & contact service center" 69 "EV charging update" 68 "Hazard on alert" 67 "Head lamps ON alert" 66 "Park lamps on alert" 65 "Engage Park brake + Take key fob out" 64 "Take key Fob out" 63 "Low Ambient Temperature / Its Already Cold Outside" 62 "Roll Up the windows if down" 61 "Express Cooling OFF, Roll Up the windows if down" 60 "Express Cooling ON windows may roll DOWN" 59 "Express Cooling OFF, Normal Cooling Mode ON" 58 "Express Cooling ON" 57 "Key Not Found" 56 "Cruise ON/Ready to Cruise" 55 "Fasten seat belt co-driver" 54 "Key Fob battery Low" 53 "Water in Fuel" 52 "Drive Alert1 - Tea Break" 51 "Fuel Level Low State" 50 "Engine Oil Pressure Low State" 49 "Fuel filter clogging" 48 "Service Reminder Kms" 47 "Service Reminder Days" 46 "Cruise Activated" 45 "Forward Collision Warning Indication" 44 "Pressure Leakage Alert Spare" 43 "Pressure Leakage Alert RR" 42 "Pressure Leakage Alert RL" 41 "Pressure Leakage Alert FR" 40 "Pressure Leakage Alert FL" 39 "High Tire Pressure Alert Spare" 38 "HighTireTemp Alert RR" 37 "HighTireTemp Alert RL" 36 "HighTireTemp Alert FR" 35 "HighTireTemp Alert FL" 34 "High Tire Pressure Alert Spare" 33 "High Tire Pressure Alert RR" 32 "High Tire Pressure Alert RL" 31 "High Tire Pressure Alert FR" 30 "High Tire Pressure Alert FL" 29 "Low Tire Pressure Alert Spare" 28 "Low Tire Pressure Alert RR" 27 "Low Tire Pressure Alert RL" 26 "Low Tire Pressure Alert FR" 25 "Low Tire Pressure Alert FL" 24 "TPMS - General warning" 23 "Low SoC Indication" 22 "Low Brake Fluid" 21 "Park Brake Engaged" 20 "HDC Activated" 19 "HDC deactivated due to speed above set value" 18 "Fasten seat belt - Driver" 17 "Tail gate open" 16 "Rear left door open" 15 "Rear right door open" 14 "Co-Driver Door open" 13 "Driver Door open" 12 "Door open- General warning" 11 "Grass/Snow" 10 "Sand" 9 "Mud/Rust/Gravel" 8 "Wet/Rain Mode" 7 "Economy Mode" 6 "Sport Mode" 5 "City Mode" 4 "Rough Road Mode" 3 "Dynamic Mode" 2 "Comfort mode" 1 "Auto Mode" 0 "No Warning" ;
VAL_ 706 HuIcNaviSource 3 "Reserved" 2 "Car Play" 1 "Android Auto" 0 "Reserved" ;
VAL_ 706 HuIcCarPlayManeuverType 63 "Reserved" 62 "Reserved" 61 "Reserved" 60 "Reserved" 59 "Reserved" 58 "Reserved" 57 "Reserved" 56 "Reserved" 55 "Reserved" 54 "Reserved" 53 "Change Highway Right. Highway to highway change from the right side of the road" 52 "Change Highway Left. Highway to highway change from the left side of the road" 51 "Change Highway. Highway to highway change with implied or unknown side of the road" 50 "Slight Right Turn. Turn on to a different road (compare to Keep Right)" 49 "Slight Left Turn.Turn on to a different road (compare to Keep Left)" 48 "Sharp Right Turn. Angle is between 135° and 180°" 47 "Sharp Left Turn. Angle is between -135° and -180°" 46 "Round about Exit19. Exit the round about at the 19th street" 45 "Round about Exit18. Exit the round about at the 18th street" 44 "Round about Exit17. Exit the round about at the 17th street" 43 "Round about Exit16. Exit the round about at the 16th street" 42 "Round about Exit15. Exit the round about at the 15th street" 41 "Round about Exit14. Exit the round about at the 14th street" 40 "Round about Exit13. Exit the round about at the 13th street" 39 "Round about Exit12. Exit the round about at the 12th street" 38 "Round about Exit11. Exit the round about at the 11th street" 37 "Round about Exit10. Exit the round about at the 10th street" 36 "Round about Exit9. Exit the round about at the 9th street" 35 "Round about Exit8. Exit the round about at the 8th street" 34 "Round about Exit7. Exit the round about at the 7thstreet" 33 "Round about Exit6. Exit the round about at the 6th street" 32 "Round about Exit5. Exit the round about at the 5th street" 31 "Round about Exit4. Exit the round about at the 4th street" 30 "Round about Exit3. Exit the round about at the 3rd street" 29 "Round about Exit2. Exit the round about at the 2nd street" 28 "Round about Exit1. Exit the round about at the 1st street" 27 "Arrive End Of Directions. Navigation has completed, but the rest of the journey will need to use another transport method" 26 "Make a U-turn when possible" 25 "Arrive At Destination Right. Destination has been reached; it is on the right and navigation will end" 24 "Arrive At Destination Left. Destination has been reached; it is on the left and navigation will end" 23 "Highway Off Ramp Right. Exit the highway on the right" 22 "Highway Off Ramp Left. Exit the highway on the left" 21 "At the end of the road,turn right" 20 "At the end of the road,turn left" 19 "Use the roundabout to make a U-turn" 18 "Make a U-turn and proceed to the route" 17 "Change to a different ferry" 16 "Exit Ferry" 15 "Enter Ferry" 14 "Keep Right. Usually for bifurcations or other smooth maneuvers (compare to Slight Right Turn)" 13 "Keep Left. Usually for bifurcations or other smooth maneuvers (compare to Slight Left Turn)" 12 "Arrive At destination. Destination has beed reached , navigation will end" 11 "Proceed to the beginning of the route" 10 "Arrive End of Navigation has completed , but the rest of the journey will need to use another transport method" 9 "On Ramp. Take the ramp to merge onto the highway" 8 "Off Ramp. Take the ramp to leave the highway" 7 "Exit Roundabout" 6 "Enter Roundabout" 5 "Continue to follow the road the vehilce is currently on" 4 "Make a U-turn" 3 "StraightAhead. Continue straight through the intersection (implies a road name will change)" 2 "RightTurn.Angleisbetween 45°and 135°" 1 "LeftTurn.Angleisbetween -45°and-135°" 0 "NoTurn(default value)" ;
VAL_ 706 HuIcNextTurnSideEnum 31 "Reserved" 30 "Reserved" 29 "Reserved" 28 "Reserved" 27 "Reserved" 26 "Reserved" 25 "Destination Reached" 24 "Destination Straight" 23 "Off Ramp Normal" 22 "Off Ramp Slight" 21 "On Ramp Turn" 20 "On Ramp Sharp" 19 "On Ramp Normal" 18 "On Ramp Slight" 17 "Keep Left /Right" 16 "Destination" 15 "Ferry Train" 14 "Ferry Boat" 13 "Straight" 12 "Round about Enter and Exit" 11 "Roundabout exit" 10 "Roundabout enter" 9 "Merge" 8 "Fork" 7 "Off Ramp" 6 "On Ramp" 5 "U Turn" 4 "Sharp Turn" 3 "Turn" 2 "Slight Turn" 1 "Name Change" 0 "Depart" ;
VAL_ 706 HuIcNextTurnRoundDistUnits 3 "Kilo Miles" 2 "Miles" 1 "Kilo Metre" 0 "Metre" ;
VAL_ 706 HuIcNaviStatus 3 "Reserved" 2 "Active" 1 "Inactive" 0 "Unavailable" ;
VAL_ 706 HuIcNextTurnSide 3 "Reserved" 2 "Left" 1 "Right" 0 "Unspecified" ;
VAL_ 706 HuIcRoundAboutType 15 "Reserved" 14 "Reserved" 13 "Reserved" 12 "Reserved" 11 "Reserved" 10 "Reserved" 9 "Reserved" 8 "Reserved" 7 "Roundabout Exit 8. Exit the roundabout at the 8th street " 6 "Roundabout Exit 7. Exit the roundabout at the 7th street " 5 "Roundabout Exit 6. Exit the roundabout at the 6th street " 4 "Roundabout Exit 5. Exit the roundabout at the 5th street " 3 "Roundabout Exit 4. Exit the roundabout at the 4th street " 2 "Roundabout Exit 3. Exit the roundabout at the 3rd  street " 1 "Roundabout Exit 2. Exit the roundabout at the 2nd street " 0 "Roundabout Exit 1. Exit the roundabout at the 1st street " ;
VAL_ 706 HuIcColorStatus 7 "Reserved" 6 "Reserved" 5 "Reserved" 4 "Orange" 3 "Pink" 2 "Red" 1 "Green" 0 "Blue" ;
VAL_ 707 HuIcNextTurnRoundDistUnitsNew 7 "Reserved" 6 "Reserved" 5 "Yard" 4 "Feet" 3 "Miles" 2 "Kilo Metre" 1 "Metre" 0 "Unknown" ;
VAL_ 707 LinSwcSbPowerModeCan 3 "Reserved" 2 "SwcActive" 1 "SwcSwitchOff" 0 "SwcUnpowered" ;
VAL_ 707 LinSwcIcKey9Can 7 "Reserved" 6 "Reserved" 5 "Reserved" 4 "Reserved" 3 "Key stuck" 2 "Long Pressed" 1 "Pressed" 0 "Not Pressed" ;
VAL_ 707 LinSwcIcKey8Can 7 "Reserved" 6 "Reserved" 5 "Reserved" 4 "Reserved" 3 "Key stuck" 2 "Long Pressed" 1 "Pressed" 0 "Not Pressed" ;
VAL_ 707 LinSwcIcKey7Can 7 "Reserved" 6 "Reserved" 5 "Reserved" 4 "Reserved" 3 "Key stuck" 2 "Long Pressed" 1 "Pressed" 0 "Not Pressed" ;
VAL_ 707 LinSwcIcKey6Can 7 "Reserved" 6 "Reserved" 5 "Reserved" 4 "Reserved" 3 "Key stuck" 2 "Long Pressed" 1 "Pressed" 0 "Not Pressed" ;
VAL_ 707 LinSwcIcViewCan 7 "Reserved" 6 "Reserved" 5 "Reserved" 4 "Reserved" 3 "Key stuck" 2 "Long Pressed" 1 "Pressed" 0 "Not Pressed" ;
VAL_ 707 LinSwcIcMenuSelectCan 7 "Reserved" 6 "Reserved" 5 "Reserved" 4 "Reserved" 3 "Key stuck" 2 "Long Pressed" 1 "Pressed" 0 "Not Pressed" ;
VAL_ 707 LinSwcIcMenuDownCan 7 "Reserved" 6 "Reserved" 5 "Reserved" 4 "Reserved" 3 "Key stuck" 2 "Long Pressed" 1 "Pressed" 0 "Not Pressed" ;
VAL_ 707 LinSwcIcMenuUpCan 7 "Reserved" 6 "Reserved" 5 "Reserved" 4 "Reserved" 3 "Key stuck" 2 "Long Pressed" 1 "Pressed" 0 "Not Pressed" ;
VAL_ 707 LinSwcIcpaginationCan 7 "Reserved" 6 "Reserved" 5 "Reserved" 4 "Reserved" 3 "Key stuck" 2 "Long Pressed" 1 "Pressed" 0 "Not Pressed" ;
VAL_ 707 LinSwcPresenceCanStatus 3 "Signal not available" 2 "Value is implausible" 1 "Reserved" 0 "Value is plausible" ;
VAL_ 707 LinSwcIcVariant 7 "Reserved" 6 "Reserved" 5 "9 Switch LIN" 4 "9 Switch Analog" 3 "5 Switch LIN" 2 "4 Switch LIN" 1 "5 Switch Analog" 0 "4 Switch Analog" ;
VAL_ 707 LinSwcPresenceCan 1 "Present" 0 "Not Present" ;
VAL_ 707 HuIcVoiceAlertStatusAck 7 "Error" 6 "Aborted" 5 "Ignored" 4 "Delivered" 3 "In Process" 2 "In Queue" 1 "Received" 0 "No Alert" ;
VAL_ 707 HuIcVoiceAlertStateAck 26 "Smart key out of range" 25 "Key Fob battery Low" 24 "Service Remainder" 23 "Water in Fuel" 22 "Low Oil Pressure" 21 "Low Brake fluid" 20 "Low fuel warning" 19 "Rear Left Tyre Pressure Monitoring" 18 "Rear Right Tyre Pressure Monitoring" 17 "Front Left Tyre Pressure Monitoring" 16 "Front Right Tyre Pressure Monitoring" 15 "Park Brake ON" 14 "Driver Seat Belt Remainder" 13 "Tail Gate open" 12 "Rear Left door open" 11 "Rear Right door open" 10 "Co Driver Door open" 9 "Driver Door Open" 8 "Door Open - general warning" 7 "Economy Mode" 6 "Sport Mode" 5 "Normal/City Mode" 4 "Rough Road Mode" 3 "Dynamic Mode" 2 "Comfort Mode" 1 "Auto Mode" 0 "No Warning" ;
VAL_ 710 PDcHuFaultState 31 "Reserved for future use." 30 "Reserved for future use." 29 "Reserved for future use." 28 "Reserved for future use." 27 "Reserved for future use." 26 "Reserved for future use." 25 "Reserved for future use." 24 "Reserved for future use." 23 "Reserved for future use." 22 "Reserved for future use." 21 "Reserved for future use." 20 "Reserved for future use." 19 "Reserved for future use." 18 "Reserved for future use." 17 "Reserved for future use." 16 "Reserved for future use." 15 "Reserved for future use." 14 "Reserved for future use." 13 "Reserved for future use." 12 "Reserved for future use." 11 " Reserved for future use." 10 "Reserved for future use." 9 "Reserved for future use." 8 "Reserved for future use." 7 " Park Brake Engaged" 6 "Tailgate Open" 5 "Minor Fault" 4 "Too much Noisy environment " 3 "Vehicle Speed too High		
" 2 "Trailer Connected" 1 " Critical fault" 0 "No Fault" ;
VAL_ 710 PDcHuAudioZoneState 7 "Reserved for future use." 6 "Reserved for future use." 5 "Reserved for future use." 4 "Reserved for future use." 3 "Continuous Beep" 2 "Fast Beep" 1 "Slow Beep" 0 "No Audio" ;
VAL_ 710 PDcHuVisualZoneRearLHSensState 15 "Reserved for future use." 14 "Reserved for future use." 13 "Reserved for future use." 12 "Reserved for future use." 11 "Reserved for future use." 10 "Reserved for future use." 9 "Reserved for future use." 8 "Reserved for future use." 7 "Reserved for future use." 6 "Zone 6" 5 "Zone 5" 4 "Zone 4" 3 "Zone 3" 2 "Zone 2" 1 "Zone 1" 0 "No Obstacle" ;
VAL_ 710 PDcHuVisualZoneRearMidRHSensStat 15 "Reserved for future use." 14 "Reserved for future use." 13 "Reserved for future use." 12 "Reserved for future use." 11 "Reserved for future use." 10 "Reserved for future use." 9 "Reserved for future use." 8 "Reserved for future use." 7 "Reserved for future use." 6 "Zone 6" 5 "Zone 5" 4 "Zone 4" 3 "Zone 3" 2 "Zone 2" 1 "Zone 1" 0 "No Obstacle" ;
VAL_ 710 PDcHuVisualZoneRearRHSensState 15 "Reserved for future use." 14 "Reserved for future use." 13 "Reserved for future use." 12 "Reserved for future use." 11 "Reserved for future use." 10 "Reserved for future use." 9 "Reserved for future use." 8 "Reserved for future use." 7 "Reserved for future use." 6 "Zone 6" 5 "Zone 5" 4 "Zone 4" 3 "Zone 3" 2 "Zone 2" 1 "Zone 1" 0 "No Obstacle" ;
VAL_ 710 PDcHuVisualZoneRearMidLHSensStat 15 "Reserved for future use." 14 "Reserved for future use." 13 "Reserved for future use." 12 "Reserved for future use." 11 "Reserved for future use." 10 "Reserved for future use." 9 "Reserved for future use." 8 "Reserved for future use." 7 "Reserved for future use." 6 "Zone 6" 5 "Zone 5" 4 "Zone 4" 3 "Zone 3" 2 "Zone 2" 1 "Zone 1" 0 "No Obstacle" ;
VAL_ 710 PDcPresence 1 "Reserved		

" 0 "PDC Present" ;
VAL_ 710 PDcHuState 1 "Active" 0 "Inactive" ;
VAL_ 710 PDcHuPwrModeState 15 "Reserved" 14 "Reserved" 13 "Reserved" 12 "Reserved" 11 "Reserved" 10 "Reserved" 9 "Reserved" 8 "Reserved" 7 "Reserved" 6 "Reserved" 5 "PDC Active (reverse to forward)" 4 "Front active" 3 "Pre-active " 2 "PDcTimer" 1 "PDcActive" 0 "PDcStandBy" ;
VAL_ 710 PDcVariant 3 "Reserved for future use" 2 "Front Only" 1 "Front & Rear" 0 "Rear Only" ;
VAL_ 710 PDcHuVisualZoneFrontLHSensState 15 "Reserved for future use." 14 "Reserved for future use." 13 "Reserved for future use." 12 "Reserved for future use." 11 "Reserved for future use." 10 "Reserved for future use." 9 "Reserved for future use." 8 "Reserved for future use." 7 "Reserved for future use." 6 "Zone 6" 5 "Zone 5" 4 "Zone 4" 3 "Zone 3" 2 "Zone 2" 1 "Zone 1" 0 "No Obstacle" ;
VAL_ 710 PDcHuVisualZoneFrontMidLHSensSta 15 "Reserved for future use." 14 "Reserved for future use." 13 "Reserved for future use." 12 "Reserved for future use." 11 "Reserved for future use." 10 "Reserved for future use." 9 "Reserved for future use." 8 "Reserved for future use." 7 "Reserved for future use." 6 "Zone 6" 5 "Zone 5" 4 "Zone 4" 3 "Zone 3" 2 "Zone 2" 1 "Zone 1" 0 "No Obstacle" ;
VAL_ 710 PDcHuVisualZoneFrontMidRHSensSta 15 "Reserved for future use." 14 "Reserved for future use." 13 "Reserved for future use." 12 "Reserved for future use." 11 "Reserved for future use." 10 "Reserved for future use." 9 "Reserved for future use." 8 "Reserved for future use." 7 "Reserved for future use." 6 "Zone 6" 5 "Zone 5" 4 "Zone 4" 3 "Zone 3" 2 "Zone 2" 1 "Zone 1" 0 "No Obstacle" ;
VAL_ 710 PDcHuVisualZoneFrontRHSensState 15 "Reserved for future use." 14 "Reserved for future use." 13 "Reserved for future use." 12 "Reserved for future use." 11 "Reserved for future use." 10 "Reserved for future use." 9 "Reserved for future use." 8 "Reserved for future use." 7 "Reserved for future use." 6 "Zone 6" 5 "Zone 5" 4 "Zone 4" 3 "Zone 3" 2 "Zone 2" 1 "Zone 1" 0 "No Obstacle" ;
VAL_ 710 PDcHuFrontAudioZoneState 7 "Reserved for future use." 6 "Reserved for future use." 5 "Reserved for future use." 4 "Reserved for future use." 3 "Continuous Beep" 2 "Fast Beep" 1 "Slow Beep" 0 "No Audio" ;
VAL_ 710 PDcHuFrontFaultState 31 "Reserved for future use." 30 "Reserved for future use." 29 "Reserved for future use." 28 "Reserved for future use." 27 "Reserved for future use." 26 "Reserved for future use." 25 "Reserved for future use." 24 "Reserved for future use." 23 "Reserved for future use." 22 "Reserved for future use." 21 "Reserved for future use." 20 "Reserved for future use." 19 "Reserved for future use." 18 "Reserved for future use." 17 "Reserved for future use." 16 "Reserved for future use." 15 "Reserved for future use." 14 "Reserved for future use." 13 "Reserved for future use." 12 "Reserved for future use." 11 " Reserved for future use." 10 "Reserved for future use." 9 "Reserved for future use." 8 "Reserved for future use." 7 "Reserved for future use." 6 "Reserved for future use." 5 "Reserved for future use." 4 "Reserved for future use." 3 "Reserved for future use." 2 "Too much Noisy environment " 1 " Critical fault" 0 "No Fault" ;
VAL_ 710 PDcHuFrontState 1 "Active" 0 "Inactive" ;
VAL_ 710 PDcIPcFrontActive 1 "Enable" 0 "Disable" ;
VAL_ 710 PDcIPcRearActive 1 "Enable" 0 "Disable" ;
VAL_ 711 PDcHuProxFrontRHSensStateStatus 3 "Signal  PDcHuProxFrontRHSensState not available. " 2 "Information given at PDcHuProxFrontRHSensState is implausible." 1 "Reserved for future use." 0 "Information given at PDcHuProxFrontRHSensState is correct and according to specification " ;
VAL_ 711 PDcHuProxFrontMidRHSensStateStat 3 "Signal  PDcHuProxFrontMidRHSensState not available  " 2 "Information given at PDcHuProxFrontMidRHSensState is implausible" 1 "Reserved for future use." 0 "Information given atPDcHuProxFrontMidRHSensState is correct and according to specification " ;
VAL_ 711 PDcHuProxFrontMidLHSensStateStat 3 "Signal  PDcHuProxFrontMidLHSensState not available  " 2 "Information given at PDcHuProxFrontMidLHSensState is implausible" 1 "Reserved for future use." 0 "Information given at PDcHuProxFrontMidLHSensState is correct and according to specification " ;
VAL_ 711 PDcHuProxFrontLHSensStateStatus 3 "Signal  PDcHuProxFrontLHSensState  not available  " 2 "Information given at PDcHuProxFrontLHSensState is implausible" 1 "Reserved for future use." 0 "Information given at PDcHuProxFrontLHSensStateis correct and according to specification " ;
VAL_ 712 PDcHuProxRearRHSensStateStatus 3 "signal not available" 2 "value is implausible" 1 "Reserved" 0 "value is plausible" ;
VAL_ 712 PDcHuProxRearMidRHSensStateStatu 3 "signal not available" 2 "value is implausible" 1 "Reserved" 0 "value is plausible" ;
VAL_ 712 PDcHuProxRearMidLHSensStateStatu 3 "signal not available" 2 "value is implausible" 1 "Reserved" 0 "value is plausible" ;
VAL_ 712 PDcHuProxRearLHSensStateStatus 3 "signal not available" 2 "value is implausible" 1 "Reserved" 0 "value is plausible" ;
VAL_ 713 HuIcMediaState 15 "Reserved" 14 "Reserved" 13 "Reserved" 12 "Reserved" 11 "Reserved" 10 "Reserved" 9 "Reserved" 8 "Tuner Scan State" 7 "Tuner Auto Store" 6 "Reverse Seeking" 5 "Forward seeking" 4 "Fast Reverse" 3 "Fast Forward" 2 "Play" 1 "Pause" 0 "Stop" ;
VAL_ 713 HuIcSource 15 "Reserved for future" 14 "Reserved for future" 13 "Alexa" 12 "Voice recognition" 11 "SMS Read Out" 10 "CarPlay Audio" 9 "Android Auto Audio" 8 "Phone" 7 "Bluetooth Audio" 6 "Aux" 5 "DRM" 4 "FM" 3 "AM" 2 "iPod" 1 "USB" 0 "No Device" ;
VAL_ 713 HuIcBTStatus 7 "Reserved" 6 "Reserved" 5 "Deleted" 4 "Disconnected" 3 "Connected" 2 "Paired" 1 "Searching" 0 "No BT connection" ;
VAL_ 713 HuIcRepeatOneState 1 "Repeat One ON" 0 "Repeat One OFF" ;
VAL_ 713 HuIcMuteStatus 1 "Mute" 0 "UnMute" ;
VAL_ 713 HuIcSMSReceiveState 1 "SMS received" 0 "No SMS" ;
VAL_ 713 HuIcRepeatState 1 "Repeat ON" 0 "Repeat OFF" ;
VAL_ 713 HuIcPhoneCallStatus 7 "Reserved" 6 "Call ended" 5 "Hold" 4 "Active Conference Call" 3 "Active Call" 2 "Outgoing Call" 1 "Incoming Call" 0 "No Phone Call" ;
VAL_ 713 HuIcNetworkSignalStatus 7 "Level 7" 6 "Level 6" 5 "Level 5" 4 "Level 4" 3 "Level 3" 2 "Level 2" 1 "Level 1" 0 "Level 0" ;
VAL_ 713 HuIcInfoFeaturePresence 1 "Present" 0 "Not Present" ;
VAL_ 713 HuIcShuffleState 1 "Shuffle ON" 0 "Shuffle OFF" ;
VAL_ 715 CcmHuRearBlwrSwitchState 3 "Speed 3" 2 "Speed 2" 1 "Speed 1" 0 "Speed 0" ;
VAL_ 715 RemoteAcStatus 3 "Signal not available" 2 "Implausible" 1 "Reserved for future use" 0 "Plausible and signal is correct" ;
VAL_ 715 RemoteAcState 1 "Remote AC ON" 0 "Remote AC OFF" ;
VAL_ 715 CCmVariantType 3 "ETC without HU" 2 "ETC with HU" 1 "FATC dual zone available" 0 "FATC single zone available" ;
VAL_ 715 CCmPresence 1 "Reserved" 0 "Present" ;
VAL_ 715 VehicleInteriorTempStatus 3 "Signal Not Available" 2 "Value is implausibe" 1 "Reserved" 0 "Value is plausible" ;
VAL_ 720 TurnRHTelltaleStatus 3 "Signal not available" 2 "Implausible" 1 "Reserved" 0 "Value is plausible" ;
VAL_ 720 TurnRHTelltale 1 "RH Turn  Indicator ON" 0 "RH Turn  Indicator OFF" ;
VAL_ 720 TurnLHTelltaleStatus 3 "Signal not available" 2 "Implausible" 1 "Reserved" 0 "Value is plausible" ;
VAL_ 720 TurnLHTelltale 1 "LH Turn Indicator ON" 0 "LH Turn Indicator OFF" ;
VAL_ 720 PositionLmpTelltaleStatus 3 "Signal not available" 2 "signal is implausible" 1 "Reserved" 0 "Value is plausible" ;
VAL_ 720 PositionLmpTelltale 1 "Position Lamp ON" 0 "Position Lamp OFF" ;
VAL_ 720 BCMVariant 7 "Reserved" 6 "Reserved" 5 "Reserved" 4 "Reserved" 3 "Reserved" 2 "BCM variant is Mid Gateway" 1 "BCM variant is Mid" 0 "BCM variant is Base" ;
VAL_ 720 BCMPresence 1 "Reserved" 0 "BCM is present" ;
VAL_ 720 RevGearStatus 3 "Signal not available" 2 "Reserved" 1 "Reserved" 0 "Value is pluasible" ;
VAL_ 720 RevGear 1 "Reverse gear engaged" 0 "Reverse gear disengaged" ;
VAL_ 720 LightSensActiveStatus 3 "Signal not available" 2 "Reserved" 1 "Reserved" 0 "Value is plausible" ;
VAL_ 720 LightSensActive 1 "Light sensor is activated" 0 "No activation of light sensor" ;
VAL_ 720 RVcPresence 3 "Ficosa Camera" 2 "Bosch Camera" 1 "Not Present" 0 "RVC Auto learning not available" ;
VAL_ 722 PowerModeStateStatus 3 "Signal not avialable" 2 "Reserved" 1 "Reserved" 0 "Value is plausible" ;
VAL_ 722 PowerModeState 15 "Reserved" 14 "Reserved" 13 "Reserved" 12 "Reserved" 11 "Transport Drive Run" 10 "Transport Drive Crank" 9 "Start(Crank)" 8 "Run(Engine Run)" 7 "Transport Drive" 6 "Active(Ignition ON)" 5 "Accessory Delay" 4 "Accessory" 3 "KeyIn" 2 "Transport Park" 1 "Awake" 0 "Pre Stand By" ;
VAL_ 722 PositionLmpTelltaleStatus 3 "Signal not available" 2 "signal is implausible" 1 "Reserved" 0 "Value is plausible" ;
VAL_ 722 PositionLmpTelltale 1 "Position Lamp ON" 0 "Position Lamp OFF" ;
VAL_ 722 TurnRHTelltale 1 "RH Turn  Indicator ON" 0 "RH Turn  Indicator OFF" ;
VAL_ 722 TurnLHTelltaleStatus 3 "Signal not available" 2 "Implausible" 1 "Reserved" 0 "Value is plausible" ;
VAL_ 722 TurnLHTelltale 1 "LH Turn Indicator ON" 0 "LH Turn Indicator OFF" ;
VAL_ 722 TurnRHTelltaleStatus 3 "Signal not available" 2 "Implausible" 1 "Reserved" 0 "Value is plausible" ;
VAL_ 722 BattSaverFnONStatus 3 "Signal not avialable" 2 "Reserved" 1 "Reserved" 0 "Value is plausible" ;
VAL_ 722 BattSaverFnON 1 "BattSaver Active" 0 "BattSaver Inactive" ;
VAL_ 722 CockpitSigECuStatus 3 "Signal CockpitSigECu Not Available" 2 "Implausible - Information given at CockpitSigECu signal value is implausible." 1 "Reserved for future use." 0 "Plausible  - Information given by CockpitSigECu is correct and according to specification  " ;
VAL_ 722 VehicleLockStateStatus 3 "Signal is not available" 2 "Signal is implausible" 1 "Reserved" 0 "Signal is plausible" ;
VAL_ 722 HighBeamTelltaleStatus 3 "Signal not available" 2 "Reserved" 1 "Reserved" 0 "Value is plausible" ;
VAL_ 722 HighBeamTelltale 1 "High Beam ON" 0 "High Beam OFF" ;
VAL_ 722 VehicleLockState 7 "TCU Unlocked " 6 "TCU Locked " 5 "Reverse Unlock" 4 "Crash Unlocked" 3 "Unlocked" 2 "Internally Locked" 1 "Externally Locked" 0 "Reserved for future use" ;
VAL_ 729 VehicleMobilizationStateStatus 3 "Signal  Not Available" 2 "Signal is Implausible" 1 "Reserved for future use" 0 "Plausible-Information is correct" ;
VAL_ 729 VehicleMobilizationState 3 "Reserved for future use" 2 "Immobilised by TCU" 1 "Mobilised by TCU" 0 "Reserved for future use" ;
VAL_ 729 PepsHuMrrProximityUnfoldSelState 1 "ORVM Proximity Auto Fold / Unfold feature ON" 0 "ORVM Proximity Auto Fold / Unfold feature OFF" ;
VAL_ 729 PepsHuMrrProximityUnfoldFuncStat 1 "ORVM Proximity Auto Fold / Unfold Function Present" 0 "ORVM Proximity Auto Fold / Unfold Function Absent" ;
VAL_ 729 PEPsClampState 7 "Reserved" 6 "Reserved" 5 "Reserved" 4 "CRANK ON" 3 "IGN ON" 2 "ACC ON" 1 "OFF" 0 "RESERVED" ;
VAL_ 729 PEPsClampStateStatus 3 "Signal not available" 2 "Value is implausibe" 1 "Reserved" 0 "Value is plausible" ;
VAL_ 729 PEPsPresence 1 "Reserved" 0 "PEPS is present" ;
VAL_ 729 PEPsKeyInState 1 "Key Is Inside The Vehicle" 0 "Key Is Not Inside The Vehicle" ;
VAL_ 732 TpmsTireSensorConfig 3 "Reserved" 2 "Reserved" 1 "5 tire sensor Configuration" 0 "4 tire sensor Configuration" ;
VAL_ 732 TPMSPresence 1 "Reserved" 0 "TPMS is present" ;
VAL_ 732 LowTirePresAlertSpare 1 "Low Pressure Alert In Spare Tire" 0 "No Low Pressure In Spare Tire" ;
VAL_ 732 LowTirePresAlertRL 1 "Low Pressure Alert In RL Tire" 0 "No Low Pressure In RL Tire" ;
VAL_ 732 LowTirePresAlertRR 1 "Low Pressure Alert In RR Tire" 0 "No Low Pressure In RR Tire" ;
VAL_ 732 LowTirePresAlertFR 1 "Low Pressure Alert In FR Tire" 0 "No Low Pressure In FR Tire" ;
VAL_ 732 LowTirePresAlertFL 1 "Low Pressure Alert In FL Tire" 0 "No Low Pressure In FL Tire" ;
VAL_ 732 HighTirePresAlertSpare 1 "High Pressure Alert In Spare Tire" 0 "No High Pressure In Spare Tire" ;
VAL_ 732 HighTirePresAlertRL 1 "High Pressure Alert In RL Tire" 0 "No High Pressure In RL Tire" ;
VAL_ 732 HighTirePresAlertRR 1 "High Pressure Alert In RR Tire" 0 "No High Pressure In RR Tire" ;
VAL_ 732 HighTirePresAlertFR 1 "High Pressure Alert In FR Tire" 0 "No High Pressure In FR Tire" ;
VAL_ 732 HighTirePresAlertFL 1 "High Pressure Alert In FL Tire" 0 "No High Pressure In FL Tire" ;
VAL_ 732 HighTireTempAlertSpare 1 "High Temperature Alert In Spare Tire" 0 "No High Temperature In Spare Tire" ;
VAL_ 732 HighTireTempAlertRL 1 "High Temperature Alert In RL Tire" 0 "No High Temperature In RL Tire" ;
VAL_ 732 HighTireTempAlertRR 1 "High Temperature Alert In RR Tire" 0 "No High temperature in RR Tire" ;
VAL_ 732 HighTireTempAlertFR 1 "High Temperature Alert In FR Tire" 0 "No High Temperature In FR Tire" ;
VAL_ 732 HighTireTempAlertFL 1 "High Temperature Alert In FL Tire" 0 "No High Temperature In FL Tire" ;
VAL_ 732 PresLeakageAlertSpare 1 "Pressure Leakage Alert In Spare Tire" 0 "No Pressure leakage in Spare Tire" ;
VAL_ 732 PresLeakageAlertRL 1 "Pressure Leakage Alert In RL Tire" 0 "No Pressure leakage in RL Tire" ;
VAL_ 732 PresLeakageAlertRR 1 "Pressure Leakage Alert In RR Tire" 0 "No Pressure leakage in RR Tire" ;
VAL_ 732 PresLeakageAlertFR 1 "Pressure Leakage Alert In FR Tire" 0 "No Pressure leakage in FR Tire" ;
VAL_ 732 PresLeakageAlertFL 1 "Pressure Leakage Alert In FL Tire" 0 "No Pressure leakage in FL Tire" ;
VAL_ 732 TpmsAlertStatus 3 "Any Alert to be Issued" 2 "Reserved" 0 "No Alert to be Issued" 1 "Reserved" ;
VAL_ 732 TpmsReceiverRXFault 1 "Receiver Has Rx Fault" 0 "No Rx Fault Present" ;
VAL_ 732 SensorMalfncFaultSpare 1 "Low Bat or Tx Fault In Spare Tire" 0 "No Low Bat or Tx Fault In Spare Tire" ;
VAL_ 732 SensorMalfncFaultRL 1 "Low Bat or Tx Fault In RL Tire" 0 "No Low Bat or Tx Fault In RL Tire" ;
VAL_ 732 SensorMalfncFaultRR 1 "Low Bat or Tx Fault In RR Tire" 0 "No Low Bat or Tx Fault In RR Tire" ;
VAL_ 732 SensorMalfncFaultFR 1 "Low Bat or Tx Fault In FR Tire" 0 "No Low Bat or Tx Fault In FR Tire" ;
VAL_ 732 SensorMalfncFaultFL 1 "Low Bat or Tx Fault In FL Tire" 0 "No Low Bat or Tx Fault In FL Tire" ;
VAL_ 732 TpmsFaultStatus 3 "TPMS System Has Fault" 2 "Reserved" 1 "Reserved" 0 "TPMS System Is Fully Functional" ;
VAL_ 732 TpmsNotLearntFault 1 "Receiver is not Learnt" 0 "Receiver is Learnt" ;
VAL_ 732 SensorMissingFaultRL 1 "Sensor Missing in RL Tire" 0 "No Sensor Missing in RL Tire" ;
VAL_ 732 SensorMissingFaultRR 1 "Sensor Missing in RR Tire" 0 "No Sensor Missing in RR Tire" ;
VAL_ 732 SensorMissingFaultFR 1 "Sensor Missing in FR Tire" 0 "No Sensor Missing in FR Tire" ;
VAL_ 732 SensorMissingFaultFL 1 "Sensor Missing in FL Tire" 0 "No Sensor Missing In FL Tire" ;
VAL_ 732 TpmsLearnStatus 3 "Last Learning Is Failed" 2 "Last Learning Is Passed" 1 "TPMS Is In Learning Mode" 0 "Default Status" ;
VAL_ 732 SpareTireSwapFlagRL 1 "RL Tire Has Spare Tire Swap" 0 "No Spare Tire Swap with RL Tire" ;
VAL_ 732 SpareTireSwapFlagRR 1 "RR Tire Has Spare Tire Swap" 0 "No Spare Tire Swap with RR Tire" ;
VAL_ 732 SpareTireSwapFlagFR 1 "FR Tire Has Spare Tire Swap" 0 "No Spare Tire Swap with FR Tire" ;
VAL_ 732 SpareTireSwapFlagFL 1 "FL Tire Has Spare Tire Swap" 0 "No Spare Tire Swap With FL Tire" ;
VAL_ 732 SensorLearningStatus 7 "Signal Is Invalid" 6 "Reserved" 5 "TPMS Learning Spare Tire" 4 "TPMS Learning RL Tire" 3 "TPMS Learning RR Tire" 2 "TPMS Learning FR Tire" 1 "TPMS Learning FL Tire" 0 "Learning No Tire" ;
VAL_ 732 SensorDetectFlagSpare 0 "Sensor Not Detected In Spare Tire" 1 "Sensor Detected In Spare Tire" ;
VAL_ 732 SensorDetectFlagRL 0 "Sensor not Detected in RL Tire" 1 "Sensor Detected In RL Tire" ;
VAL_ 732 SensorDetectFlagRR 0 "Sensor not Detected in RR Tire" 1 "Sensor Detected In RR Tire" ;
VAL_ 732 SensorDetectFlagFR 0 "Sensor not Detected in FR Tire" 1 "Sensor Detected In FR Tire" ;
VAL_ 732 SensorDetectFlagFL 0 "Sensor Not Detected In FL Tire" 1 "Sensor Detected In FL Tire" ;
VAL_ 733 SensorIDnotLearntSpare 1 "Sensor ID Not Learnt In Spare Tire" 0 "Sensor ID Learnt In Spare Tire" ;
VAL_ 733 SensorIDnotLearntRL 1 "Sensor ID Not Learnt In RL Tire" 0 "Sensor ID Learnt In RL Tire" ;
VAL_ 733 SensorIDnotLearntRR 1 "Sensor ID Not Learnt In RR Tire" 0 "Sensor ID Learnt In RR Tire" ;
VAL_ 733 SensorIDnotLearntFR 1 "Sensor ID Not Learnt In FR Tire" 0 "Sensor ID Learnt In FR Tire" ;
VAL_ 733 SensorIDnotLearntFL 1 "Sensor ID Not Learnt In FL Tire" 0 "Sensor ID Learnt In FL Tire" ;
VAL_ 744 HuCCmFanSpdDuringVR 15 "Reserved" 14 "Reserved" 13 "Reserved" 12 "Reserved" 11 "Reserved" 10 "Reserved" 9 "Reserved" 8 "Reserved" 7 "Speed 7" 6 "Speed 6" 5 "Speed 5" 4 "Speed 4" 3 "Speed 3" 2 "Speed 2" 1 "Speed 1" 0 "Speed 0" ;
VAL_ 744 HuCCmVRSession 3 "Reserved" 2 "Reserved" 1 "Active" 0 "Not Active" ;
